VERSION "dbc-export 1 2025.20.8"

NS_ :

BS_:

BU_: ADSP APB APP APS APSB BB BMS CC CMP CMPD CP DAS DI DIF DIR DPB EPAS3P EPAS3S EPASTP EPASTS EPBL EPBR ESP EVSE FC GTW HCML HCMR HVP IBST ICR IDB LS OCS1P ODIN PARK PCS PLG PM PMF PMR PNCD PTC RADC RCM RCM2 RCM3 RCU SCCM SCM SCS SDCR TAS TCU TPMS TRCM UDS UI UIS UMC USM VC VCFRONT VCLEFT VCRIGHT VCSEC VEH

BO_ 1560 UDS_icrRequest: 8 UDS
 SG_ UDS_icrRequestData : 7|64@0+ (1,0) [0|1.84467440737e+19] "" Vector__XXX

BO_ 1603 UDS_ocs1pRequest: 8 UDS
 SG_ UDS_ocs1pRequestData : 7|64@0+ (1,0) [0|1.84467440737e+19] "" Vector__XXX

BO_ 1614 UDS_parkRequest: 8 UDS
 SG_ UDS_parkRequestData : 7|64@0+ (1,0) [0|1.84467440737e+19] "" Vector__XXX

BO_ 1576 UDS_pcsRequest: 8 UDS
 SG_ UDS_pcsRequestData : 7|64@0+ (1,0) [0|1.84467440737e+19] "" Vector__XXX

BO_ 1634 UDS_plgRequest: 8 UDS
 SG_ UDS_plgRequestData : 7|64@0+ (1,0) [0|1.84467440737e+19] "" Vector__XXX

BO_ 1568 UDS_pmRequest: 8 UDS
 SG_ UDS_pmRequestData : 7|64@0+ (1,0) [0|1.84467440737e+19] "" Vector__XXX

BO_ 1604 UDS_pmfRequest: 8 UDS
 SG_ UDS_pmfRequestData : 7|64@0+ (1,0) [0|1.84467440737e+19] "" Vector__XXX

BO_ 1540 UDS_pmrRequest: 8 UDS
 SG_ UDS_pmrRequestData : 7|64@0+ (1,0) [0|1.84467440737e+19] "" Vector__XXX

BO_ 1734 UDS_ptcRequest: 8 UDS
 SG_ UDS_ptcRequestData : 7|64@0+ (1,0) [0|1.84467440737e+19] "" Vector__XXX

BO_ 1649 UDS_radcRequest: 8 UDS
 SG_ UDS_radcRequestData : 7|64@0+ (1,0) [0|1.84467440737e+19] "" Vector__XXX

BO_ 1601 UDS_rcmRequest: 8 UDS
 SG_ UDS_rcmRequestData : 7|64@0+ (1,0) [0|1.84467440737e+19] "" Vector__XXX

BO_ 1664 UDS_sccmRequest: 8 UDS
 SG_ UDS_sccmRequestData : 7|64@0+ (1,0) [0|1.84467440737e+19] "" Vector__XXX

BO_ 1723 UDS_sdcrRequest: 8 UDS
 SG_ UDS_sdcrRequestData : 7|64@0+ (1,0) [0|1.84467440737e+19] "" Vector__XXX

BO_ 1611 UDS_tasRequest: 8 UDS
 SG_ UDS_tasRequestData : 7|64@0+ (1,0) [0|1.84467440737e+19] "" Vector__XXX

BO_ 1551 UDS_thcRequest: 8 UDS
 SG_ UDS_thcRequestData_H : 7|32@0+ (1,0) [0|4294967295] "" Vector__XXX
 SG_ UDS_thcRequestData_L : 39|32@0+ (1,0) [0|4294967295] "" Vector__XXX

BO_ 1615 UDS_tpmsRequest: 8 UDS
 SG_ UDS_tpmsRequestData : 7|64@0+ (1,0) [0|1.84467440737e+19] "" Vector__XXX

BO_ 1578 UDS_vcbatt1Request: 8 UDS
 SG_ UDS_vcbatt1RequestData : 7|64@0+ (1,0) [0|1.84467440737e+19] "" Vector__XXX

BO_ 1588 UDS_vcbatt2Request: 8 UDS
 SG_ UDS_vcbatt2RequestData : 7|64@0+ (1,0) [0|1.84467440737e+19] "" Vector__XXX

BO_ 1636 UDS_vcbattRequest: 8 UDS
 SG_ UDS_vcbattRequestData : 7|64@0+ (1,0) [0|1.84467440737e+19] "" Vector__XXX

BO_ 1580 UDS_vcfront1Request: 8 UDS
 SG_ UDS_vcfront1RequestData : 7|64@0+ (1,0) [0|1.84467440737e+19] "" Vector__XXX

BO_ 1582 UDS_vcfront2Request: 8 UDS
 SG_ UDS_vcfront2RequestData : 7|64@0+ (1,0) [0|1.84467440737e+19] "" Vector__XXX

BO_ 1536 UDS_vcfrontRequest: 8 UDS
 SG_ UDS_vcfrontRequestData : 7|64@0+ (1,0) [0|1.84467440737e+19] "" Vector__XXX

BO_ 1570 UDS_vcleftRequest: 8 UDS
 SG_ UDS_vcleftRequestData_H : 7|32@0+ (1,0) [0|4294967295] "" Vector__XXX
 SG_ UDS_vcleftRequestData_L : 39|32@0+ (1,0) [0|4294967295] "" Vector__XXX

BO_ 1544 UDS_vcrightRequest: 8 UDS
 SG_ UDS_vcrightRequestData_H : 7|32@0+ (1,0) [0|4294967295] "" Vector__XXX
 SG_ UDS_vcrightRequestData_L : 39|32@0+ (1,0) [0|4294967295] "" Vector__XXX

BO_ 1546 UDS_vcsecRequest: 8 UDS
 SG_ UDS_vcsecRequestData : 7|64@0+ (1,0) [0|1.84467440737e+19] "" Vector__XXX

BO_ 1056 UIS_log: 8 UIS
 SG_ UIS_logMux M : 0|32@1+ (1,0) [0|4294967295] "" Vector__XXX
 SG_ UIS_zramWriteTicks m0 : 32|32@1+ (1,0) [0|4294967295] "" Vector__XXX
 SG_ UIS_zramWriteIO m1 : 32|32@1+ (1,0) [0|4294967295] "" Vector__XXX
 SG_ UIS_zramReadTicks m2 : 32|32@1+ (1,0) [0|4294967295] "" Vector__XXX
 SG_ UIS_zramReadIO m3 : 32|32@1+ (1,0) [0|4294967295] "" Vector__XXX
 SG_ UIS_zramOriginalSize m4 : 32|32@1+ (1,0) [0|4294967295] "" Vector__XXX
 SG_ UIS_zramNotifyFree m5 : 32|32@1+ (1,0) [0|4294967295] "" Vector__XXX
 SG_ UIS_zramInvalidIO m6 : 32|32@1+ (1,0) [0|4294967295] "" Vector__XXX
 SG_ UIS_zramFailedWrites m7 : 32|32@1+ (1,0) [0|4294967295] "" Vector__XXX
 SG_ UIS_zramFailedReads m8 : 32|32@1+ (1,0) [0|4294967295] "" Vector__XXX
 SG_ UIS_zramCompressionRatio m9 : 32|32@1+ (1,0) [0|4294967295] "" Vector__XXX
 SG_ UIS_zramCompressedSize m10 : 32|32@1+ (1,0) [0|4294967295] "" Vector__XXX
 SG_ UIS_wifiTemperature m11 : 32|32@1+ (1,0) [0|4294967295] "" Vector__XXX
 SG_ UIS_wifiStackState m12 : 32|32@1+ (1,0) [0|4294967295] "" Vector__XXX
 SG_ UIS_wifiStackReady m13 : 32|32@1+ (1,0) [0|4294967295] "" Vector__XXX
 SG_ UIS_wifiBars m14 : 32|32@1+ (1,0) [0|4294967295] "" Vector__XXX
 SG_ UIS_wifiAutoJoinLowRSSI m15 : 32|32@1+ (1,0) [0|1] "" Vector__XXX
 SG_ UIS_webbrowserMemUsage m16 : 32|32@1+ (1,0) [0|4294967295] "" Vector__XXX
 SG_ UIS_webbrowserCPUUsage m17 : 32|32@1+ (1,0) [0|4294967295] "" Vector__XXX
 SG_ UIS_vmtouchMemUsage m18 : 32|32@1+ (1,0) [0|4294967295] "" Vector__XXX
 SG_ UIS_vmtouchCPUUsage m19 : 32|32@1+ (1,0) [0|4294967295] "" Vector__XXX
 SG_ UIS_videodMemUsage m20 : 32|32@1+ (1,0) [0|4294967295] "" Vector__XXX
 SG_ UIS_videodCPUUsage m21 : 32|32@1+ (1,0) [0|4294967295] "" Vector__XXX
 SG_ UIS_vehicleMemUsage m22 : 32|32@1+ (1,0) [0|4294967295] "" Vector__XXX
 SG_ UIS_vehicleCPUUsage m23 : 32|32@1+ (1,0) [0|4294967295] "" Vector__XXX
 SG_ UIS_valhallaserverMemUsage m24 : 32|32@1+ (1,0) [0|4294967295] "" Vector__XXX
 SG_ UIS_valhallaserverCPUUsage m25 : 32|32@1+ (1,0) [0|4294967295] "" Vector__XXX
 SG_ UIS_valetMode m26 : 32|32@1+ (1,0) [0|1] "" Vector__XXX
 SG_ UIS_uiQtCarUptime m27 : 32|32@1+ (1,0) [0|4294967295] "" Vector__XXX
 SG_ UIS_uiQtCarSwapUsage m28 : 32|32@1+ (1,0) [0|4294967295] "" Vector__XXX
 SG_ UIS_uiMeanFPS m29 : 32|32@1+ (1,0) [0|4294967295] "" Vector__XXX
 SG_ UIS_uiMaxFrametime m30 : 32|32@1+ (1,0) [0|4294967295] "" Vector__XXX
 SG_ UIS_uiFramesOver200Ms m31 : 32|32@1+ (1,0) [0|4294967295] "" Vector__XXX
 SG_ UIS_uiFramesOver100Ms m32 : 32|32@1+ (1,0) [0|4294967295] "" Vector__XXX
 SG_ UIS_tunerVoltageUBatt m33 : 32|32@1+ (1,0) [0|4294967295] "" Vector__XXX
 SG_ UIS_tunerVoltageOperation m34 : 32|32@1+ (1,0) [0|4294967295] "" Vector__XXX
 SG_ UIS_tunerVoltageMQS m35 : 32|32@1+ (1,0) [0|4294967295] "" Vector__XXX
 SG_ UIS_tunerVoltageAntenna2 m36 : 32|32@1+ (1,0) [0|4294967295] "" Vector__XXX
 SG_ UIS_tunerVoltageAntenna1 m37 : 32|32@1+ (1,0) [0|4294967295] "" Vector__XXX
 SG_ UIS_tunerVoltage3V3 m38 : 32|32@1+ (1,0) [0|4294967295] "" Vector__XXX
 SG_ UIS_tunerVoltage1V8 m39 : 32|32@1+ (1,0) [0|4294967295] "" Vector__XXX
 SG_ UIS_tunerTemperatureFahrenheit m40 : 32|32@1+ (1,0) [0|4294967295] "" Vector__XXX
 SG_ UIS_tunerTemperatureCelsius m41 : 32|32@1+ (1,0) [0|4294967295] "" Vector__XXX
 SG_ UIS_tunerCurrentAntenna2 m42 : 32|32@1+ (1,0) [0|4294967295] "" Vector__XXX
 SG_ UIS_tunerCurrentAntenna1 m43 : 32|32@1+ (1,0) [0|4294967295] "" Vector__XXX
 SG_ UIS_touchEventsAggCount m44 : 32|32@1+ (1,0) [0|4294967295] "" Vector__XXX
 SG_ UIS_tmserverMemUsage m45 : 32|32@1+ (1,0) [0|4294967295] "" Vector__XXX
 SG_ UIS_tmserverCPUUsage m46 : 32|32@1+ (1,0) [0|4294967295] "" Vector__XXX
 SG_ UIS_testDriveMode m47 : 32|32@1+ (1,0) [0|4294967295] "" Vector__XXX
 SG_ UIS_teslachromiumMemUsage m48 : 32|32@1+ (1,0) [0|4294967295] "" Vector__XXX
 SG_ UIS_teslachromiumCPUUsage m49 : 32|32@1+ (1,0) [0|4294967295] "" Vector__XXX
 SG_ UIS_teslacefzygotMemUsage m50 : 32|32@1+ (1,0) [0|4294967295] "" Vector__XXX
 SG_ UIS_teslacefzygotCPUUsage m51 : 32|32@1+ (1,0) [0|4294967295] "" Vector__XXX
 SG_ UIS_teslacefgpuMemUsage m52 : 32|32@1+ (1,0) [0|4294967295] "" Vector__XXX
 SG_ UIS_teslacefgpuCPUUsage m53 : 32|32@1+ (1,0) [0|4294967295] "" Vector__XXX
 SG_ UIS_teslaMediaCacheSize m54 : 32|32@1+ (1,0) [0|4294967295] "" Vector__XXX
 SG_ UIS_teslaMediaCacheCost m55 : 32|32@1+ (1,0) [0|4294967295] "" Vector__XXX
 SG_ UIS_tegraModemManState m56 : 32|32@1+ (1,0) [0|4294967295] "" Vector__XXX
 SG_ UIS_systemWakeTime m57 : 32|32@1+ (1,0) [0|4294967295] "" Vector__XXX
 SG_ UIS_systemUptime m58 : 32|32@1+ (1,0) [0|4294967295] "" Vector__XXX
 SG_ UIS_systemMemSwapUsage m59 : 32|32@1+ (1,0) [0|4294967295] "" Vector__XXX
 SG_ UIS_suspensionGeofence m60 : 32|32@1+ (1,0) [0|1] "" Vector__XXX
 SG_ UIS_superchargePaymentNeeded m61 : 32|32@1+ (1,0) [0|4294967295] "" Vector__XXX
 SG_ UIS_sudokuMemUsage m62 : 32|32@1+ (1,0) [0|4294967295] "" Vector__XXX
 SG_ UIS_sudokuCPUUsage m63 : 32|32@1+ (1,0) [0|4294967295] "" Vector__XXX
 SG_ UIS_spotifyserverMemUsage m64 : 32|32@1+ (1,0) [0|4294967295] "" Vector__XXX
 SG_ UIS_spotifyserverCPUUsage m65 : 32|32@1+ (1,0) [0|4294967295] "" Vector__XXX
 SG_ UIS_speechrecoMemUsage m66 : 32|32@1+ (1,0) [0|4294967295] "" Vector__XXX
 SG_ UIS_speechrecoCPUUsage m67 : 32|32@1+ (1,0) [0|4294967295] "" Vector__XXX
 SG_ UIS_solitaireMemUsage m68 : 32|32@1+ (1,0) [0|4294967295] "" Vector__XXX
 SG_ UIS_solitaireCPUUsage m69 : 32|32@1+ (1,0) [0|4294967295] "" Vector__XXX
 SG_ UIS_sleepType m70 : 32|32@1+ (1,0) [0|4294967295] "" Vector__XXX
 SG_ UIS_sleepTime m71 : 32|32@1+ (1,0) [0|4294967295] "" Vector__XXX
 SG_ UIS_sleepState m72 : 32|32@1+ (1,0) [0|4294967295] "" Vector__XXX
 SG_ UIS_sleepCount m73 : 32|32@1+ (1,0) [0|4294967295] "" Vector__XXX
 SG_ UIS_slackerLoginResult m74 : 32|32@1+ (1,0) [0|4294967295] "" Vector__XXX
 SG_ UIS_settingsAutoTurnSignal m75 : 32|32@1+ (1,0) [0|4294967295] "" Vector__XXX
 SG_ UIS_serviceModePlus m76 : 32|32@1+ (1,0) [0|4294967295] "" Vector__XXX
 SG_ UIS_serviceMode m77 : 32|32@1+ (1,0) [0|4294967295] "" Vector__XXX
 SG_ UIS_serverMemUsage m78 : 32|32@1+ (1,0) [0|4294967295] "" Vector__XXX
 SG_ UIS_serverCPUUsage m79 : 32|32@1+ (1,0) [0|4294967295] "" Vector__XXX
 SG_ UIS_sentryState m80 : 32|32@1+ (1,0) [0|4294967295] "" Vector__XXX
 SG_ UIS_sentryNeedsNap m81 : 32|32@1+ (1,0) [0|4294967295] "" Vector__XXX
 SG_ UIS_sentryIncidentCount m82 : 32|32@1+ (1,0) [0|4294967295] "" Vector__XXX
 SG_ UIS_scheduledChargingMode m83 : 32|32@1+ (1,0) [0|4294967295] "" Vector__XXX
 SG_ UIS_scheduleChargeStartTime m84 : 32|32@1+ (1,0) [0|4294967295] "" Vector__XXX
 SG_ UIS_scheduleChargeEndTime m85 : 32|32@1+ (1,0) [0|4294967295] "" Vector__XXX
 SG_ UIS_remoteRequestType m86 : 32|32@1+ (1,0) [0|4294967295] "" Vector__XXX
 SG_ UIS_releasenotesMemUsage m87 : 32|32@1+ (1,0) [0|4294967295] "" Vector__XXX
 SG_ UIS_releasenotesCPUUsage m88 : 32|32@1+ (1,0) [0|4294967295] "" Vector__XXX
 SG_ UIS_rearDisplayUserPresent m89 : 32|32@1+ (1,0) [0|1] "" Vector__XXX
 SG_ UIS_rearDisplayState m90 : 32|32@1+ (1,0) [0|4294967295] "" Vector__XXX
 SG_ UIS_radioserveMemUsage m91 : 32|32@1+ (1,0) [0|4294967295] "" Vector__XXX
 SG_ UIS_radioserveCPUUsage m92 : 32|32@1+ (1,0) [0|4294967295] "" Vector__XXX
 SG_ UIS_qtcarMemUsage m93 : 32|32@1+ (1,0) [0|4294967295] "" Vector__XXX
 SG_ UIS_qtcarCPUUsage m94 : 32|32@1+ (1,0) [0|4294967295] "" Vector__XXX
 SG_ UIS_psiMemSome m95 : 32|32@1+ (1,0) [0|4294967295] "" Vector__XXX
 SG_ UIS_psiMemFull m96 : 32|32@1+ (1,0) [0|4294967295] "" Vector__XXX
 SG_ UIS_psiIOSome m97 : 32|32@1+ (1,0) [0|4294967295] "" Vector__XXX
 SG_ UIS_psiIOFull m98 : 32|32@1+ (1,0) [0|4294967295] "" Vector__XXX
 SG_ UIS_psiCpuSome m99 : 32|32@1+ (1,0) [0|4294967295] "" Vector__XXX
 SG_ UIS_powerManagerState m100 : 32|5@1+ (1,0) [0|31] "" Vector__XXX
 SG_ UIS_polytopiax8664MemUsage m101 : 32|32@1+ (1,0) [0|4294967295] "" Vector__XXX
 SG_ UIS_polytopiax8664CPUUsage m102 : 32|32@1+ (1,0) [0|4294967295] "" Vector__XXX
 SG_ UIS_odincefMemUsage m103 : 32|32@1+ (1,0) [0|4294967295] "" Vector__XXX
 SG_ UIS_odincefCPUUsage m104 : 32|32@1+ (1,0) [0|4294967295] "" Vector__XXX
 SG_ UIS_odinStatusCmdResult m105 : 32|32@1+ (1,0) [0|4294967295] "" Vector__XXX
 SG_ UIS_odinStatusCmdDurationMs m106 : 32|32@1+ (1,0) [0|4294967295] "" Vector__XXX
 SG_ UIS_odinProcessState m107 : 32|32@1+ (1,0) [0|4294967295] "" Vector__XXX
 SG_ UIS_odinOrchestratorStartCount m108 : 32|32@1+ (1,0) [0|4294967295] "" Vector__XXX
 SG_ UIS_odinOrchestratorFailCount m109 : 32|32@1+ (1,0) [0|4294967295] "" Vector__XXX
 SG_ UIS_odinNetworkStartCount m110 : 32|32@1+ (1,0) [0|4294967295] "" Vector__XXX
 SG_ UIS_odinNetworkFailCount m111 : 32|32@1+ (1,0) [0|4294967295] "" Vector__XXX
 SG_ UIS_odinMemUsage m112 : 32|32@1+ (1,0) [0|4294967295] "" Vector__XXX
 SG_ UIS_odinListTasksCmdResult m113 : 32|32@1+ (1,0) [0|4294967295] "" Vector__XXX
 SG_ UIS_odinListTasksCmdDurationMs m114 : 32|32@1+ (1,0) [0|4294967295] "" Vector__XXX
 SG_ UIS_odinHrlUploadLimits m115 : 32|32@1+ (1,0) [0|4294967295] "" Vector__XXX
 SG_ UIS_odinHrlLogUploadState m116 : 32|32@1+ (1,0) [0|4294967295] "" Vector__XXX
 SG_ UIS_odinHermesConnectionState m117 : 32|32@1+ (1,0) [0|4294967295] "" Vector__XXX
 SG_ UIS_odinGatewayConnectionState m118 : 32|32@1+ (1,0) [0|4294967295] "" Vector__XXX
 SG_ UIS_odinFileSystemState m119 : 32|32@1+ (1,0) [0|4294967295] "" Vector__XXX
 SG_ UIS_odinEcuLogUploadState m120 : 32|32@1+ (1,0) [0|4294967295] "" Vector__XXX
 SG_ UIS_odinEcuLogForceTriggerUpload m121 : 32|32@1+ (1,0) [0|4294967295] "" Vector__XXX
 SG_ UIS_odinCPUUsage m122 : 32|32@1+ (1,0) [0|4294967295] "" Vector__XXX
 SG_ UIS_odinAuthFailCount m123 : 32|32@1+ (1,0) [0|4294967295] "" Vector__XXX
 SG_ UIS_odinAuthCount m124 : 32|32@1+ (1,0) [0|4294967295] "" Vector__XXX
 SG_ UIS_nvmeTemperature m125 : 32|32@1+ (1,0) [0|4294967295] "" Vector__XXX
 SG_ UIS_nvmePercentLifetimeUsed m126 : 32|32@1+ (1,0) [0|4294967295] "" Vector__XXX
 SG_ UIS_nvmeDataUnitsWritten100mb m127 : 32|32@1+ (1,0) [0|4294967295] "" Vector__XXX
 SG_ UIS_numUncorrMemErrorsECC m128 : 32|32@1+ (1,0) [0|4294967295] "" Vector__XXX
 SG_ UIS_numCorrMemErrorsECC m129 : 32|32@1+ (1,0) [0|4294967295] "" Vector__XXX
 SG_ UIS_nuanceserverMemUsage m130 : 32|32@1+ (1,0) [0|4294967295] "" Vector__XXX
 SG_ UIS_nuanceserverCPUUsage m131 : 32|32@1+ (1,0) [0|4294967295] "" Vector__XXX
 SG_ UIS_navAudioVolume m132 : 32|32@1+ (1,0) [0|4294967295] "" Vector__XXX
 SG_ UIS_muteNavVolume m133 : 32|32@1+ (1,0) [0|4294967295] "" Vector__XXX
 SG_ UIS_mounterdState m134 : 32|32@1+ (1,0) [0|4294967295] "" Vector__XXX
 SG_ UIS_mounterdMountCountTotal m135 : 32|32@1+ (1,0) [0|4294967295] "" Vector__XXX
 SG_ UIS_mounterdFrontHubDisconnected m136 : 32|32@1+ (1,0) [0|4294967295] "" Vector__XXX
 SG_ UIS_mounterdFrontHubConnected m137 : 32|32@1+ (1,0) [0|4294967295] "" Vector__XXX
 SG_ UIS_mounterdFilesystemCountFat32 m138 : 32|32@1+ (1,0) [0|4294967295] "" Vector__XXX
 SG_ UIS_mounterdFilesystemCountExt4 m139 : 32|32@1+ (1,0) [0|4294967295] "" Vector__XXX
 SG_ UIS_mounterdFilesystemCountExt3 m140 : 32|32@1+ (1,0) [0|4294967295] "" Vector__XXX
 SG_ UIS_mounterdFilesystemCountExfat m141 : 32|32@1+ (1,0) [0|4294967295] "" Vector__XXX
 SG_ UIS_mounterdEncryptionCapacityGB m142 : 32|32@1+ (1,0) [0|4294967295] "" Vector__XXX
 SG_ UIS_mounterdDeviceCount m143 : 32|32@1+ (1,0) [0|4294967295] "" Vector__XXX
 SG_ UIS_mounterdDashcamCapacityGB m144 : 32|32@1+ (1,0) [0|4294967295] "" Vector__XXX
 SG_ UIS_modemECallppAvail m145 : 32|32@1+ (1,0) [0|1] "" Vector__XXX
 SG_ UIS_modemBusyActive m146 : 32|32@1+ (1,0) [0|1] "" Vector__XXX
 SG_ UIS_mirrorGeofenceActive m147 : 32|32@1+ (1,0) [0|1] "" Vector__XXX
 SG_ UIS_mediaserveMemUsage m148 : 32|32@1+ (1,0) [0|4294967295] "" Vector__XXX
 SG_ UIS_mediaserveCPUUsage m149 : 32|32@1+ (1,0) [0|4294967295] "" Vector__XXX
 SG_ UIS_mediaPlaybackStatus m150 : 32|32@1+ (1,0) [0|4294967295] "" Vector__XXX
 SG_ UIS_mediaNeedAuthToken m151 : 32|32@1+ (1,0) [0|1] "" Vector__XXX
 SG_ UIS_mediaImageCacheSize m152 : 32|32@1+ (1,0) [0|4294967295] "" Vector__XXX
 SG_ UIS_mediaImageCacheCost m153 : 32|32@1+ (1,0) [0|4294967295] "" Vector__XXX
 SG_ UIS_limex8664MemUsage m154 : 32|32@1+ (1,0) [0|4294967295] "" Vector__XXX
 SG_ UIS_limex8664CPUUsage m155 : 32|32@1+ (1,0) [0|4294967295] "" Vector__XXX
 SG_ UIS_inSuperchargerGeofence m156 : 32|32@1+ (1,0) [0|1] "" Vector__XXX
 SG_ UIS_igpuTemperature m157 : 32|32@1+ (1,0) [0|4294967295] "" Vector__XXX
 SG_ UIS_homelinkState m158 : 32|32@1+ (1,0) [0|4294967295] "" Vector__XXX
 SG_ UIS_hermesdynamicMemUsage m159 : 32|32@1+ (1,0) [0|4294967295] "" Vector__XXX
 SG_ UIS_hermesdynamicCPUUsage m160 : 32|32@1+ (1,0) [0|4294967295] "" Vector__XXX
 SG_ UIS_hermesclientMemUsage m161 : 32|32@1+ (1,0) [0|4294967295] "" Vector__XXX
 SG_ UIS_hermesclientCPUUsage m162 : 32|32@1+ (1,0) [0|4294967295] "" Vector__XXX
 SG_ UIS_headsetPairResult m163 : 32|32@1+ (1,0) [0|4294967295] "" Vector__XXX
 SG_ UIS_headsetConnectionState m164 : 32|32@1+ (1,0) [0|4294967295] "" Vector__XXX
 SG_ UIS_gtwSocUartTxStatTimeouts m165 : 32|32@1+ (1,0) [0|4294967295] "" Vector__XXX
 SG_ UIS_gtwSocUartTxStatPackets m166 : 32|32@1+ (1,0) [0|4294967295] "" Vector__XXX
 SG_ UIS_gtwSocUartTxStatNacks m167 : 32|32@1+ (1,0) [0|4294967295] "" Vector__XXX
 SG_ UIS_gtwSocUartTxStatBadTooBig m168 : 32|32@1+ (1,0) [0|4294967295] "" Vector__XXX
 SG_ UIS_gtwSocUartTxStatAnsMismatch m169 : 32|32@1+ (1,0) [0|4294967295] "" Vector__XXX
 SG_ UIS_gtwSocUartRxStatValidPackets m170 : 32|32@1+ (1,0) [0|4294967295] "" Vector__XXX
 SG_ UIS_gtwSocUartRxStatUnhandled m171 : 32|32@1+ (1,0) [0|4294967295] "" Vector__XXX
 SG_ UIS_gtwSocUartRxStatMsgErr m172 : 32|32@1+ (1,0) [0|4294967295] "" Vector__XXX
 SG_ UIS_gtwSocUartRxStatHeartbeats m173 : 32|32@1+ (1,0) [0|4294967295] "" Vector__XXX
 SG_ UIS_gtwSocUartRxStatHandleErr m174 : 32|32@1+ (1,0) [0|4294967295] "" Vector__XXX
 SG_ UIS_gtwSocUartRxStatBadTooSmall m175 : 32|32@1+ (1,0) [0|4294967295] "" Vector__XXX
 SG_ UIS_gtwSocUartRxStatBadTooBig m176 : 32|32@1+ (1,0) [0|4294967295] "" Vector__XXX
 SG_ UIS_gtwSocUartRxStatBadChecksum m177 : 32|32@1+ (1,0) [0|4294967295] "" Vector__XXX
 SG_ UIS_gpsmanagerMemUsage m178 : 32|32@1+ (1,0) [0|4294967295] "" Vector__XXX
 SG_ UIS_gpsmanagerCPUUsage m179 : 32|32@1+ (1,0) [0|4294967295] "" Vector__XXX
 SG_ UIS_godot_TIME_PROCESS m180 : 32|32@1+ (1,0) [0|4294967295] "" Vector__XXX
 SG_ UIS_godot_TIME_FPS m181 : 32|32@1+ (1,0) [0|4294967295] "" Vector__XXX
 SG_ UIS_godot_MEMORY_STATIC m182 : 32|32@1+ (1,0) [0|4294967295] "" Vector__XXX
 SG_ UIS_godot_MEMORY_DYNAMIC m183 : 32|32@1+ (1,0) [0|4294967295] "" Vector__XXX
 SG_ UIS_godotMemUsage m184 : 32|32@1+ (1,0) [0|4294967295] "" Vector__XXX
 SG_ UIS_godotCPUUsage m185 : 32|32@1+ (1,0) [0|4294967295] "" Vector__XXX
 SG_ UIS_firmwareReleaseScope m186 : 32|32@1+ (1,0) [0|4294967295] "" Vector__XXX
 SG_ UIS_featureSuperchargingEnabled m187 : 32|32@1+ (1,0) [0|4294967295] "" Vector__XXX
 SG_ UIS_estimatedOccupancyCount m188 : 32|32@1+ (1,0) [0|4294967295] "" Vector__XXX
 SG_ UIS_embeddedGameState m189 : 32|32@1+ (1,0) [0|4294967295] "" Vector__XXX
 SG_ UIS_embeddedGameName m190 : 32|32@1+ (1,0) [0|4294967295] "" Vector__XXX
 SG_ UIS_dumTclipUploadState m191 : 32|32@1+ (1,0) [0|4294967295] "" Vector__XXX
 SG_ UIS_dumTclipUploadActive m192 : 32|32@1+ (1,0) [0|4294967295] "" Vector__XXX
 SG_ UIS_dumTclipTransferCount m193 : 32|32@1+ (1,0) [0|4294967295] "" Vector__XXX
 SG_ UIS_dumTclipSuccessfulUploadCoun m194 : 32|32@1+ (1,0) [0|4294967295] "" Vector__XXX
 SG_ UIS_dumTclipClipCount m195 : 32|32@1+ (1,0) [0|4294967295] "" Vector__XXX
 SG_ UIS_dmRearTouchDeviceExists m196 : 32|32@1+ (1,0) [0|4294967295] "" Vector__XXX
 SG_ UIS_dmRearPowerState m197 : 32|32@1+ (1,0) [0|1] "" Vector__XXX
 SG_ UIS_dmRearLinkCheckOk m198 : 32|32@1+ (1,0) [0|1] "" Vector__XXX
 SG_ UIS_dmRearEnabled m199 : 32|32@1+ (1,0) [0|4294967295] "" Vector__XXX
 SG_ UIS_dmRearConnected m200 : 32|32@1+ (1,0) [0|4294967295] "" Vector__XXX
 SG_ UIS_dmRearBacklightPowerLevel m201 : 32|32@1+ (1,0) [0|4294967295] "" Vector__XXX
 SG_ UIS_dmRearBacklightNits m202 : 32|32@1+ (1,0) [0|4294967295] "" Vector__XXX
 SG_ UIS_dmRearBacklightFault m203 : 32|32@1+ (1,0) [0|4294967295] "" Vector__XXX
 SG_ UIS_dmRearBacklightDutyCycle m204 : 32|32@1+ (1,0) [0|4294967295] "" Vector__XXX
 SG_ UIS_dmRearBacklightDevExists m205 : 32|32@1+ (1,0) [0|1] "" Vector__XXX
 SG_ UIS_dmRearAsilStatusMsb m206 : 32|32@1+ (1,0) [0|4294967295] "" Vector__XXX
 SG_ UIS_dmRearAsilStatusLsb m207 : 32|32@1+ (1,0) [0|4294967295] "" Vector__XXX
 SG_ UIS_dmIcuTouchIrqCount m208 : 32|32@1+ (1,0) [0|4294967295] "" Vector__XXX
 SG_ UIS_dmIcuPowerState m209 : 32|32@1+ (1,0) [0|1] "" Vector__XXX
 SG_ UIS_dmIcuLinkCheckOk m210 : 32|32@1+ (1,0) [0|1] "" Vector__XXX
 SG_ UIS_dmIcuEnabled m211 : 32|32@1+ (1,0) [0|4294967295] "" Vector__XXX
 SG_ UIS_dmIcuConnected m212 : 32|32@1+ (1,0) [0|4294967295] "" Vector__XXX
 SG_ UIS_dmIcuBacklightPowerLevel m213 : 32|32@1+ (1,0) [0|4294967295] "" Vector__XXX
 SG_ UIS_dmIcuBacklightNits m214 : 32|32@1+ (1,0) [0|4294967295] "" Vector__XXX
 SG_ UIS_dmIcuBacklightFault m215 : 32|32@1+ (1,0) [0|4294967295] "" Vector__XXX
 SG_ UIS_dmIcuBacklightDutyCycle m216 : 32|32@1+ (1,0) [0|4294967295] "" Vector__XXX
 SG_ UIS_dmIcuBacklightDevExists m217 : 32|32@1+ (1,0) [0|1] "" Vector__XXX
 SG_ UIS_dmIcuAsilShortFlag m218 : 32|32@1+ (1,0) [0|4294967295] "" Vector__XXX
 SG_ UIS_dmIcuAsilResumeFlag m219 : 32|32@1+ (1,0) [0|4294967295] "" Vector__XXX
 SG_ UIS_dmIcuAsilOpenFlag m220 : 32|32@1+ (1,0) [0|4294967295] "" Vector__XXX
 SG_ UIS_dmIcuAsilFirmwareStatus m221 : 32|32@1+ (1,0) [0|4294967295] "" Vector__XXX
 SG_ UIS_dmGatewayLinkWedged m222 : 32|32@1+ (1,0) [0|4294967295] "" Vector__XXX
 SG_ UIS_dmCenterTouchIrqCount m223 : 32|32@1+ (1,0) [0|4294967295] "" Vector__XXX
 SG_ UIS_dmCenterTouchDeviceExists m224 : 32|32@1+ (1,0) [0|4294967295] "" Vector__XXX
 SG_ UIS_dmCenterSOsdVideoCrcData m225 : 32|32@1+ (1,0) [0|4294967295] "" Vector__XXX
 SG_ UIS_dmCenterSOsdExactCrcCheck m226 : 32|32@1+ (1,0) [0|4294967295] "" Vector__XXX
 SG_ UIS_dmCenterPowerState m227 : 32|32@1+ (1,0) [0|1] "" Vector__XXX
 SG_ UIS_dmCenterOsdDisplayedState m228 : 32|32@1+ (1,0) [0|1] "" Vector__XXX
 SG_ UIS_dmCenterOsdDayNightState m229 : 32|32@1+ (1,0) [0|4294967295] "" Vector__XXX
 SG_ UIS_dmCenterModeSettingStatus m230 : 32|32@1+ (1,0) [0|4294967295] "" Vector__XXX
 SG_ UIS_dmCenterMOsdVideoCrcData m231 : 32|32@1+ (1,0) [0|4294967295] "" Vector__XXX
 SG_ UIS_dmCenterMOsdExactCrcCheck m232 : 32|32@1+ (1,0) [0|4294967295] "" Vector__XXX
 SG_ UIS_dmCenterLinkCheckOk m233 : 32|32@1+ (1,0) [0|1] "" Vector__XXX
 SG_ UIS_dmCenterEnabled m234 : 32|32@1+ (1,0) [0|4294967295] "" Vector__XXX
 SG_ UIS_dmCenterConnected m235 : 32|32@1+ (1,0) [0|4294967295] "" Vector__XXX
 SG_ UIS_dmCenterBacklightPowerLevel m236 : 32|32@1+ (1,0) [0|4294967295] "" Vector__XXX
 SG_ UIS_dmCenterBacklightNits m237 : 32|32@1+ (1,0) [0|4294967295] "" Vector__XXX
 SG_ UIS_dmCenterBacklightFault m238 : 32|32@1+ (1,0) [0|4294967295] "" Vector__XXX
 SG_ UIS_dmCenterBacklightDutyCycle m239 : 32|32@1+ (1,0) [0|4294967295] "" Vector__XXX
 SG_ UIS_dmCenterBacklightDevExists m240 : 32|32@1+ (1,0) [0|1] "" Vector__XXX
 SG_ UIS_dmCenterAsilShortFlag m241 : 32|32@1+ (1,0) [0|4294967295] "" Vector__XXX
 SG_ UIS_dmCenterAsilResumeFlag m242 : 32|32@1+ (1,0) [0|4294967295] "" Vector__XXX
 SG_ UIS_dmCenterAsilOpenFlag m243 : 32|32@1+ (1,0) [0|4294967295] "" Vector__XXX
 SG_ UIS_dmCenterAsilFirmwareStatus m244 : 32|32@1+ (1,0) [0|4294967295] "" Vector__XXX
 SG_ UIS_dgpuTemperature m245 : 32|32@1+ (1,0) [0|4294967295] "" Vector__XXX
 SG_ UIS_developerMode m246 : 32|32@1+ (1,0) [0|4294967295] "" Vector__XXX
 SG_ UIS_dashcamviewerMemUsage m247 : 32|32@1+ (1,0) [0|4294967295] "" Vector__XXX
 SG_ UIS_dashcamviewerCPUUsage m248 : 32|32@1+ (1,0) [0|4294967295] "" Vector__XXX
 SG_ UIS_dashcamTransferTimeMs m249 : 32|32@1+ (1,0) [0|4294967295] "" Vector__XXX
 SG_ UIS_dashcamTransferSizeMB m250 : 32|32@1+ (1,0) [0|4294967295] "" Vector__XXX
 SG_ UIS_dashcamTransferRateMBps m251 : 32|32@1+ (1,0) [0|4294967295] "" Vector__XXX
 SG_ UIS_dashcamTransferFileCount m252 : 32|32@1+ (1,0) [0|4294967295] "" Vector__XXX
 SG_ UIS_dashcamTransferCount m253 : 32|32@1+ (1,0) [0|4294967295] "" Vector__XXX
 SG_ UIS_dashcamStorageState m254 : 32|32@1+ (1,0) [0|4294967295] "" Vector__XXX
 SG_ UIS_dashcamStorageSentryMB m255 : 32|32@1+ (1,0) [0|4294967295] "" Vector__XXX
 SG_ UIS_dashcamStorageSavedMB m256 : 32|32@1+ (1,0) [0|4294967295] "" Vector__XXX
 SG_ UIS_dashcamStorageRecentMB m257 : 32|32@1+ (1,0) [0|4294967295] "" Vector__XXX
 SG_ UIS_dashcamStorageAvailableMB m258 : 32|32@1+ (1,0) [0|4294967295] "" Vector__XXX
 SG_ UIS_dashcamState m259 : 32|32@1+ (1,0) [0|4294967295] "" Vector__XXX
 SG_ UIS_dashcamSavedToSentryCount m260 : 32|32@1+ (1,0) [0|4294967295] "" Vector__XXX
 SG_ UIS_dashcamSavedToSavedCount m261 : 32|32@1+ (1,0) [0|4294967295] "" Vector__XXX
 SG_ UIS_dashcamSavedToOnboardCount m262 : 32|32@1+ (1,0) [0|4294967295] "" Vector__XXX
 SG_ UIS_dashcamOnboardTransferCount m263 : 32|32@1+ (1,0) [0|4294967295] "" Vector__XXX
 SG_ UIS_dashcamOnboardSavePressCount m264 : 32|32@1+ (1,0) [0|4294967295] "" Vector__XXX
 SG_ UIS_dashcamOnboardMB m265 : 32|32@1+ (1,0) [0|4294967295] "" Vector__XXX
 SG_ UIS_dashcamOnboardAvailableMB m266 : 32|32@1+ (1,0) [0|4294967295] "" Vector__XXX
 SG_ UIS_cpuTemperature m267 : 32|32@1+ (1,0) [0|4294967295] "" Vector__XXX
 SG_ UIS_compositorRenderMinRenderTim m268 : 32|32@1+ (1,0) [0|4294967295] "" Vector__XXX
 SG_ UIS_compositorRenderMinFrameTime m269 : 32|32@1+ (1,0) [0|4294967295] "" Vector__XXX
 SG_ UIS_compositorRenderMaxRenderTim m270 : 32|32@1+ (1,0) [0|4294967295] "" Vector__XXX
 SG_ UIS_compositorRenderMaxFrameTime m271 : 32|32@1+ (1,0) [0|4294967295] "" Vector__XXX
 SG_ UIS_compositorRenderGpuPercentag m272 : 32|32@1+ (1,0) [0|4294967295] "" Vector__XXX
 SG_ UIS_compositorRenderFrameRate m273 : 32|32@1+ (1,0) [0|4294967295] "" Vector__XXX
 SG_ UIS_compositorRenderFrameCount m274 : 32|32@1+ (1,0) [0|4294967295] "" Vector__XXX
 SG_ UIS_compositorRenderAvgRenderTim m275 : 32|32@1+ (1,0) [0|4294967295] "" Vector__XXX
 SG_ UIS_compositorFrameMonitorState m276 : 32|32@1+ (1,0) [0|4294967295] "" Vector__XXX
 SG_ UIS_cobaltlinuxMemUsage m277 : 32|32@1+ (1,0) [0|4294967295] "" Vector__XXX
 SG_ UIS_cobaltlinuxCPUUsage m278 : 32|32@1+ (1,0) [0|4294967295] "" Vector__XXX
 SG_ UIS_clusterMemUsage m279 : 32|32@1+ (1,0) [0|4294967295] "" Vector__XXX
 SG_ UIS_clusterMeanFPS m280 : 32|32@1+ (1,0) [0|4294967295] "" Vector__XXX
 SG_ UIS_clusterMaxFrametime m281 : 32|32@1+ (1,0) [0|4294967295] "" Vector__XXX
 SG_ UIS_clusterFramesOver200Ms m282 : 32|32@1+ (1,0) [0|4294967295] "" Vector__XXX
 SG_ UIS_clusterFramesOver100Ms m283 : 32|32@1+ (1,0) [0|4294967295] "" Vector__XXX
 SG_ UIS_clusterDisplayState m284 : 32|32@1+ (1,0) [0|4294967295] "" Vector__XXX
 SG_ UIS_clusterCPUUsage m285 : 32|32@1+ (1,0) [0|4294967295] "" Vector__XXX
 SG_ UIS_chromiumadapterMemUsage m286 : 32|32@1+ (1,0) [0|4294967295] "" Vector__XXX
 SG_ UIS_chromiumadapterCPUUsage m287 : 32|32@1+ (1,0) [0|4294967295] "" Vector__XXX
 SG_ UIS_chargeOnSolarNoChargeReason m288 : 32|32@1+ (1,0) [0|4294967295] "" Vector__XXX
 SG_ UIS_ceruleanx8664MemUsage m289 : 32|32@1+ (1,0) [0|4294967295] "" Vector__XXX
 SG_ UIS_ceruleanx8664CPUUsage m290 : 32|32@1+ (1,0) [0|4294967295] "" Vector__XXX
 SG_ UIS_centerDisplayState m291 : 32|32@1+ (1,0) [0|4294967295] "" Vector__XXX
 SG_ UIS_centerDisplayEvent m292 : 32|32@1+ (1,0) [0|4294967295] "" Vector__XXX
 SG_ UIS_centerDispAsilB_msb m293 : 32|32@1+ (1,0) [0|4294967295] "" Vector__XXX
 SG_ UIS_centerDispAsilB_lsb m294 : 32|32@1+ (1,0) [0|4294967295] "" Vector__XXX
 SG_ UIS_centerDispAsilA_msb m295 : 32|32@1+ (1,0) [0|4294967295] "" Vector__XXX
 SG_ UIS_centerDispAsilA_lsb m296 : 32|32@1+ (1,0) [0|4294967295] "" Vector__XXX
 SG_ UIS_cellularLinkManagerState m297 : 32|32@1+ (1,0) [0|4294967295] "" Vector__XXX
 SG_ UIS_carAssistState m298 : 32|32@1+ (1,0) [0|4294967295] "" Vector__XXX
 SG_ UIS_carAssistSessionCount m299 : 32|32@1+ (1,0) [0|4294967295] "" Vector__XXX
 SG_ UIS_carAssistErrorCode m300 : 32|32@1+ (1,0) [0|4294967295] "" Vector__XXX
 SG_ UIS_cameraRRepeaterStreamMissing m301 : 32|32@1+ (1,0) [0|1] "" Vector__XXX
 SG_ UIS_cameraRRepeaterStream m302 : 32|32@1+ (1,0) [0|4294967295] "" Vector__XXX
 SG_ UIS_cameraRRepeaterPopup m303 : 32|32@1+ (1,0) [0|1] "" Vector__XXX
 SG_ UIS_cameraRRepeaterPipeline m304 : 32|32@1+ (1,0) [0|4294967295] "" Vector__XXX
 SG_ UIS_cameraRRepeaterMaxFrametime m305 : 32|32@1+ (1,0) [0|4294967295] "" Vector__XXX
 SG_ UIS_cameraRRepeaterLateFrames m306 : 32|32@1+ (1,0) [0|4294967295] "" Vector__XXX
 SG_ UIS_cameraRRepeaterFramerate m307 : 32|32@1+ (1,0) [0|4294967295] "" Vector__XXX
 SG_ UIS_cameraLRepeaterStreamMissing m308 : 32|32@1+ (1,0) [0|1] "" Vector__XXX
 SG_ UIS_cameraLRepeaterStream m309 : 32|32@1+ (1,0) [0|4294967295] "" Vector__XXX
 SG_ UIS_cameraLRepeaterPopup m310 : 32|32@1+ (1,0) [0|1] "" Vector__XXX
 SG_ UIS_cameraLRepeaterPipeline m311 : 32|32@1+ (1,0) [0|4294967295] "" Vector__XXX
 SG_ UIS_cameraLRepeaterMaxFrametime m312 : 32|32@1+ (1,0) [0|4294967295] "" Vector__XXX
 SG_ UIS_cameraLRepeaterLateFrames m313 : 32|32@1+ (1,0) [0|4294967295] "" Vector__XXX
 SG_ UIS_cameraLRepeaterFramerate m314 : 32|32@1+ (1,0) [0|4294967295] "" Vector__XXX
 SG_ UIS_cameraFrontStreamMissing m315 : 32|32@1+ (1,0) [0|4294967295] "" Vector__XXX
 SG_ UIS_cameraFrontStream m316 : 32|32@1+ (1,0) [0|4294967295] "" Vector__XXX
 SG_ UIS_cameraFrontPopup m317 : 32|32@1+ (1,0) [0|4294967295] "" Vector__XXX
 SG_ UIS_cameraFrontPipeline m318 : 32|32@1+ (1,0) [0|4294967295] "" Vector__XXX
 SG_ UIS_cameraBackupStreamQuality m319 : 32|32@1+ (1,0) [0|4294967295] "" Vector__XXX
 SG_ UIS_cameraBackupStreamMissing m320 : 32|32@1+ (1,0) [0|1] "" Vector__XXX
 SG_ UIS_cameraBackupStream m321 : 32|32@1+ (1,0) [0|4294967295] "" Vector__XXX
 SG_ UIS_cameraBackupPopup m322 : 32|32@1+ (1,0) [0|1] "" Vector__XXX
 SG_ UIS_cameraBackupPipeline m323 : 32|32@1+ (1,0) [0|4294967295] "" Vector__XXX
 SG_ UIS_cameraBackupMaxFrametime m324 : 32|32@1+ (1,0) [0|4294967295] "" Vector__XXX
 SG_ UIS_cameraBackupLateFrames m325 : 32|32@1+ (1,0) [0|4294967295] "" Vector__XXX
 SG_ UIS_cameraBackupFramerate m326 : 32|32@1+ (1,0) [0|4294967295] "" Vector__XXX
 SG_ UIS_camBackupDecodeMinFrametime m327 : 32|32@1+ (1,0) [0|4294967295] "" Vector__XXX
 SG_ UIS_camBackupDecodeMaxFrametime m328 : 32|32@1+ (1,0) [0|4294967295] "" Vector__XXX
 SG_ UIS_camBackupDecodeFramecount m329 : 32|32@1+ (1,0) [0|4294967295] "" Vector__XXX
 SG_ UIS_camBackupDecodeAvgFrametime m330 : 32|32@1+ (1,0) [0|4294967295] "" Vector__XXX
 SG_ UIS_bootCount m331 : 32|32@1+ (1,0) [0|4294967295] "" Vector__XXX
 SG_ UIS_boardTemperature m332 : 32|32@1+ (1,0) [0|4294967295] "" Vector__XXX
 SG_ UIS_bluetoothStackState m333 : 32|32@1+ (1,0) [0|4294967295] "" Vector__XXX
 SG_ UIS_bluetoothStackRearState m334 : 32|32@1+ (1,0) [0|4294967295] "" Vector__XXX
 SG_ UIS_bluetoothPairResult m335 : 32|32@1+ (1,0) [0|4294967295] "" Vector__XXX
 SG_ UIS_bluetoothMemUsage m336 : 32|32@1+ (1,0) [0|4294967295] "" Vector__XXX
 SG_ UIS_bluetoothConnectionState m337 : 32|32@1+ (1,0) [0|4294967295] "" Vector__XXX
 SG_ UIS_bluetoothCPUUsage m338 : 32|32@1+ (1,0) [0|4294967295] "" Vector__XXX
 SG_ UIS_bluetoothAutoConnectionState m339 : 32|32@1+ (1,0) [0|4294967295] "" Vector__XXX
 SG_ UIS_bifrostOdinEngineUp m340 : 32|32@1+ (1,0) [0|4294967295] "" Vector__XXX
 SG_ UIS_bifrostOdinEngineRequests m341 : 32|32@1+ (1,0) [0|4294967295] "" Vector__XXX
 SG_ UIS_bifrostMemUsage m342 : 32|32@1+ (1,0) [0|4294967295] "" Vector__XXX
 SG_ UIS_bifrostCPUUsage m343 : 32|32@1+ (1,0) [0|4294967295] "" Vector__XXX
 SG_ UIS_backlightUserRequest m344 : 32|32@1+ (1,0) [0|4294967295] "" Vector__XXX
 SG_ UIS_audioVolumeLevel m345 : 32|32@1+ (1,0) [0|4294967295] "" Vector__XXX
 SG_ UIS_audioType m346 : 32|32@1+ (1,0) [0|4294967295] "" Vector__XXX
 SG_ UIS_audioState m347 : 32|32@1+ (1,0) [0|4294967295] "" Vector__XXX
 SG_ UIS_audioSource m348 : 32|32@1+ (1,0) [0|4294967295] "" Vector__XXX
 SG_ UIS_audioPWSGain m349 : 32|32@1+ (1,0) [0|4294967295] "" Vector__XXX
 SG_ UIS_audioMediaPlaying m350 : 32|32@1+ (1,0) [0|4294967295] "" Vector__XXX
 SG_ UIS_audioMediaBrowsing m351 : 32|32@1+ (1,0) [0|4294967295] "" Vector__XXX
 SG_ UIS_audioA2BRediscoveryCount m352 : 32|32@1+ (1,0) [0|4294967295] "" Vector__XXX
 SG_ UIS_amdSocPkgPower m353 : 32|32@1+ (1,0) [0|4294967295] "" Vector__XXX
 SG_ UIS_activeAppView m354 : 32|32@1+ (1,0) [0|4294967295] "" Vector__XXX

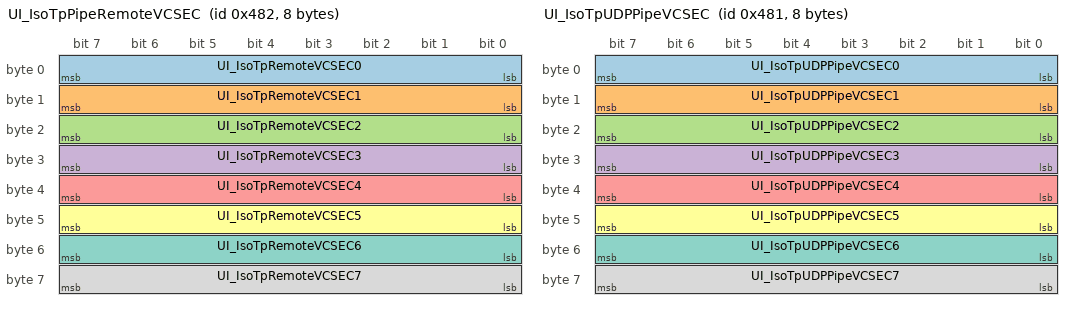
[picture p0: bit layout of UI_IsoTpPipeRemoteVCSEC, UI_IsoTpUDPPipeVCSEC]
BO_ 1154 UI_IsoTpPipeRemoteVCSEC: 8 UI
 SG_ UI_IsoTpRemoteVCSEC0 : 0|8@1+ (1,0) [0|255] "" Vector__XXX
 SG_ UI_IsoTpRemoteVCSEC1 : 8|8@1+ (1,0) [0|255] "" Vector__XXX
 SG_ UI_IsoTpRemoteVCSEC2 : 16|8@1+ (1,0) [0|255] "" Vector__XXX
 SG_ UI_IsoTpRemoteVCSEC3 : 24|8@1+ (1,0) [0|255] "" Vector__XXX
 SG_ UI_IsoTpRemoteVCSEC4 : 32|8@1+ (1,0) [0|255] "" Vector__XXX
 SG_ UI_IsoTpRemoteVCSEC5 : 40|8@1+ (1,0) [0|255] "" Vector__XXX
 SG_ UI_IsoTpRemoteVCSEC6 : 48|8@1+ (1,0) [0|255] "" Vector__XXX
 SG_ UI_IsoTpRemoteVCSEC7 : 56|8@1+ (1,0) [0|255] "" Vector__XXX

BO_ 1153 UI_IsoTpUDPPipeVCSEC: 8 UI
 SG_ UI_IsoTpUDPPipeVCSEC0 : 0|8@1+ (1,0) [0|255] "" Vector__XXX
 SG_ UI_IsoTpUDPPipeVCSEC1 : 8|8@1+ (1,0) [0|255] "" Vector__XXX
 SG_ UI_IsoTpUDPPipeVCSEC2 : 16|8@1+ (1,0) [0|255] "" Vector__XXX
 SG_ UI_IsoTpUDPPipeVCSEC3 : 24|8@1+ (1,0) [0|255] "" Vector__XXX
 SG_ UI_IsoTpUDPPipeVCSEC4 : 32|8@1+ (1,0) [0|255] "" Vector__XXX
 SG_ UI_IsoTpUDPPipeVCSEC5 : 40|8@1+ (1,0) [0|255] "" Vector__XXX
 SG_ UI_IsoTpUDPPipeVCSEC6 : 48|8@1+ (1,0) [0|255] "" Vector__XXX
 SG_ UI_IsoTpUDPPipeVCSEC7 : 56|8@1+ (1,0) [0|255] "" Vector__XXX

BO_ 979 UI_airbagCutoffStatus: 1 UI
 SG_ UI_airbagCutoffSwState : 0|2@1+ (1,0) [0|3] "" Vector__XXX
 SG_ UI_warningIndicatorStatus : 2|2@1+ (1,0) [0|2] "" Vector__XXX

BO_ 1523 UI_alertLog: 8 UI
 SG_ UI_alertID M : 0|8@1+ (1,0) [0|255] "" Vector__XXX
 SG_ UI_alertState : 15|1@1+ (1,0) [0|1] "" Vector__XXX
 SG_ UI_a006_remoteServiceAlertCode m6 : 16|32@1+ (1,0) [0|4294967295] "" Vector__XXX
 SG_ UI_a034_BackupCamera m34 : 16|1@1+ (1,0) [0|1] "" Vector__XXX
 SG_ UI_a034_Tuner m34 : 17|1@1+ (1,0) [0|1] "" Vector__XXX
 SG_ UI_a034_Bluetooth m34 : 18|1@1+ (1,0) [0|1] "" Vector__XXX
 SG_ UI_a034_WiFi m34 : 19|1@1+ (1,0) [0|1] "" Vector__XXX
 SG_ UI_a034_Cellular m34 : 20|1@1+ (1,0) [0|1] "" Vector__XXX
 SG_ UI_a034_TouchScreen m34 : 21|1@1+ (1,0) [0|1] "" Vector__XXX
 SG_ UI_a034_Display m34 : 22|1@1+ (1,0) [0|1] "" Vector__XXX
 SG_ UI_a034_Audio m34 : 23|1@1+ (1,0) [0|1] "" Vector__XXX
 SG_ UI_a034_FatalWakeup m34 : 24|1@1+ (1,0) [0|1] "" Vector__XXX
 SG_ UI_a034_UnknownWakeupError m34 : 25|1@1+ (1,0) [0|1] "" Vector__XXX
 SG_ UI_a036_audioWatchdogReason m36 : 16|8@1+ (1,0) [0|255] "" Vector__XXX
 SG_ UI_a045_ManualECallDisabled m45 : 16|1@1+ (1,0) [0|1] "" Vector__XXX
 SG_ UI_a045_ManualECallButtonDisconn m45 : 17|1@1+ (1,0) [0|1] "" Vector__XXX
 SG_ UI_a045_CellAntenna m45 : 18|1@1+ (1,0) [0|1] "" Vector__XXX
 SG_ UI_a045_GPSAntenna m45 : 19|1@1+ (1,0) [0|1] "" Vector__XXX
 SG_ UI_a045_ECallSpeaker m45 : 20|1@1+ (1,0) [0|1] "" Vector__XXX
 SG_ UI_a045_ECallMic m45 : 21|1@1+ (1,0) [0|1] "" Vector__XXX
 SG_ UI_a045_SIMTest m45 : 22|1@1+ (1,0) [0|1] "" Vector__XXX
 SG_ UI_a045_ENSTest m45 : 23|1@1+ (1,0) [0|1] "" Vector__XXX
 SG_ UI_a045_CellularTest m45 : 24|1@1+ (1,0) [0|1] "" Vector__XXX
 SG_ UI_a045_ModemFirmwareTest m45 : 25|1@1+ (1,0) [0|1] "" Vector__XXX
 SG_ UI_a052_kernelPanicSignature m52 : 16|32@1+ (1,0) [0|4294967295] "" Vector__XXX
 SG_ UI_a066_ProcessId m66 : 16|8@1+ (1,0) [0|255] "" Vector__XXX
 SG_ UI_a066_RingBlitter m66 : 24|1@1+ (1,0) [0|1] "" Vector__XXX
 SG_ UI_a066_RingBSD m66 : 25|1@1+ (1,0) [0|1] "" Vector__XXX
 SG_ UI_a066_RingRender m66 : 26|1@1+ (1,0) [0|1] "" Vector__XXX
 SG_ UI_a066_RingVideoEnhancement m66 : 27|1@1+ (1,0) [0|1] "" Vector__XXX
 SG_ UI_a066_EnginesHung m66 : 28|1@1+ (1,0) [0|1] "" Vector__XXX
 SG_ UI_a066_EnginesWedged m66 : 29|1@1+ (1,0) [0|1] "" Vector__XXX
 SG_ UI_a066_RecoveryFailed m66 : 30|1@1+ (1,0) [0|1] "" Vector__XXX
 SG_ UI_a066_FlipDoneTimedOut m66 : 31|1@1+ (1,0) [0|1] "" Vector__XXX
 SG_ UI_a066_TimedoutSoftRecovered m66 : 32|1@1+ (1,0) [0|1] "" Vector__XXX
 SG_ UI_a087_BmpResetType m87 : 16|3@1+ (1,0) [0|7] "" Vector__XXX
 SG_ UI_a096_PipelineId m96 : 16|8@1+ (1,0) [0|255] "" Vector__XXX
 SG_ UI_a096_UdpTimeout m96 : 24|1@1+ (1,0) [0|1] "" Vector__XXX
 SG_ UI_a096_PipelineWarning m96 : 25|1@1+ (1,0) [0|1] "" Vector__XXX
 SG_ UI_a096_PipelineError m96 : 26|1@1+ (1,0) [0|1] "" Vector__XXX
 SG_ UI_a096_UnexpectedExit m96 : 27|1@1+ (1,0) [0|1] "" Vector__XXX
 SG_ UI_a096_PipelineOverrun m96 : 28|1@1+ (1,0) [0|1] "" Vector__XXX
 SG_ UI_a096_MissingXWindow m96 : 29|1@1+ (1,0) [0|1] "" Vector__XXX
 SG_ UI_a099_emmcStatusRegister m99 : 16|32@1+ (1,0) [0|4294967295] "" Vector__XXX
 SG_ UI_a100_emmcFTLCounter m100 : 16|32@1+ (1,0) [0|4294967295] "" Vector__XXX
 SG_ UI_a131_DisplayPortFailureType m131 : 16|1@1+ (1,0) [0|1] "" Vector__XXX
 SG_ UI_a147_whichASIL m147 : 16|1@1+ (1,0) [0|1] "" Vector__XXX
 SG_ UI_a147_errorCode m147 : 24|8@1+ (1,0) [0|255] "" Vector__XXX
 SG_ UI_a148_sleepType m148 : 16|2@1+ (1,0) [0|3] "" Vector__XXX
 SG_ UI_a148_lastFailedDev m148 : 24|32@1+ (1,0) [0|4294967295] "" Vector__XXX
 SG_ UI_a148_lastFailedPmSuspendDev m148 : 56|5@1+ (1,0) [0|31] "" Vector__XXX
 SG_ UI_a149_displayType m149 : 16|8@1+ (1,0) [0|255] "" Vector__XXX
 SG_ UI_a149_errorCode m149 : 24|32@1+ (1,0) [0|4294967295] "" Vector__XXX
 SG_ UI_a153_processName m153 : 16|8@1+ (1,0) [0|255] "" Vector__XXX
 SG_ UI_a153_restartReason m153 : 24|8@1+ (1,0) [0|255] "" Vector__XXX
 SG_ UI_a158_UsbDeviceMountErrorCode m158 : 16|32@1+ (1,0) [0|4294967295] "" Vector__XXX
 SG_ UI_a160_WatchdogStarving m160 : 16|1@1+ (1,0) [0|1] "" Vector__XXX
 SG_ UI_a160_MemoryPressureCritical m160 : 17|1@1+ (1,0) [0|1] "" Vector__XXX
 SG_ UI_a160_MemoryUsageCritical m160 : 18|1@1+ (1,0) [0|1] "" Vector__XXX
 SG_ UI_a160_SlabUsageCritical m160 : 19|1@1+ (1,0) [0|1] "" Vector__XXX
 SG_ UI_a165_fsCorruptedDevice m165 : 16|4@1+ (1,0) [0|15] "" Vector__XXX
 SG_ UI_a166_fsErrorDevice m166 : 16|4@1+ (1,0) [0|15] "" Vector__XXX
 SG_ UI_a167_processId m167 : 16|5@1+ (1,0) [0|31] "" Vector__XXX
 SG_ UI_a173_errorCode m173 : 16|2@1+ (1,0) [0|3] "" Vector__XXX
 SG_ UI_a173_hookIndex m173 : 18|4@1+ (1,0) [0|15] "" Vector__XXX
 SG_ UI_a173_lastFailedPmSuspendDev m173 : 24|5@1+ (1,0) [0|31] "" Vector__XXX
 SG_ UI_a176_PrimaryAntenna m176 : 16|3@1+ (1,0) [0|7] "" Vector__XXX
 SG_ UI_a176_SecondaryAntenna m176 : 19|3@1+ (1,0) [0|7] "" Vector__XXX
 SG_ UI_a176_TertiaryAntenna m176 : 24|3@1+ (1,0) [0|7] "" Vector__XXX
 SG_ UI_a177_errorCode m177 : 16|5@1+ (1,0) [0|31] "" Vector__XXX
 SG_ UI_a178_irqNumber m178 : 16|16@1+ (1,0) [0|65535] "" Vector__XXX
 SG_ UI_a178_irqSourceId m178 : 32|32@1+ (1,0) [0|4294967295] "" Vector__XXX
 SG_ UI_a192_AudioRebootState m192 : 16|4@1+ (1,0) [0|15] "" Vector__XXX
 SG_ UI_a214_errorCode m214 : 16|8@1+ (1,0) [0|255] "" Vector__XXX
 SG_ UI_a214_lastFailedDev m214 : 24|32@1+ (1,0) [0|4294967295] "" Vector__XXX
 SG_ UI_a214_lastFailedPmSuspendDev m214 : 56|5@1+ (1,0) [0|31] "" Vector__XXX
 SG_ UI_a216_circuitProblem m216 : 16|8@1+ (1,0) [0|255] "" Vector__XXX
 SG_ UI_a216_circuitNode m216 : 24|8@1+ (1,0) [0|255] "" Vector__XXX
 SG_ UI_a217_cgroupName m217 : 16|5@1+ (1,0) [0|31] "" Vector__XXX
 SG_ UI_a220_errorCode m220 : 16|4@1+ (1,0) [0|15] "" Vector__XXX
 SG_ UI_a222_errorCode m222 : 16|4@1+ (1,0) [0|15] "" Vector__XXX
 SG_ UI_a223_database m223 : 16|6@1+ (1,0) [0|63] "" Vector__XXX
 SG_ UI_a226_count m226 : 16|16@1+ (1,0) [0|65535] "" Vector__XXX
 SG_ UI_a229_errorCode m229 : 16|8@1+ (1,0) [0|255] "" Vector__XXX
 SG_ UI_a231_sleepType m231 : 16|2@1+ (1,0) [0|3] "" Vector__XXX
 SG_ UI_a232_processExited m232 : 16|8@1+ (1,0) [0|255] "" Vector__XXX
 SG_ UI_a232_processSignal m232 : 24|8@1+ (1,0) [0|255] "" Vector__XXX
 SG_ UI_a240_ethErrorType m240 : 16|8@1+ (1,0) [0|255] "" Vector__XXX
 SG_ UI_a241_errorCode m241 : 16|8@1+ (1,0) [0|255] "" Vector__XXX

BO_ 291 UI_alertMatrix1: 8 UI
 SG_ UI_a001_DriverDoorOpen : 0|1@1+ (1,0) [0|1] "" Vector__XXX
 SG_ UI_a002_DoorOpen : 1|1@1+ (1,0) [0|1] "" Vector__XXX
 SG_ UI_a003_TrunkOpen : 2|1@1+ (1,0) [0|1] "" Vector__XXX
 SG_ UI_a004_FrunkOpen : 3|1@1+ (1,0) [0|1] "" Vector__XXX
 SG_ UI_a005_HeadlightsOnDoorOpen : 4|1@1+ (1,0) [0|1] "" Vector__XXX
 SG_ UI_a006_RemoteServiceAlert : 5|1@1+ (1,0) [0|1] "" Vector__XXX
 SG_ UI_a007_SoftPackConfigMismatch : 6|1@1+ (1,0) [0|1] "" Vector__XXX
 SG_ UI_a008_TouchScreenError : 7|1@1+ (1,0) [0|1] "" Vector__XXX
 SG_ UI_a009_SquashfsError : 8|1@1+ (1,0) [0|1] "" Vector__XXX
 SG_ UI_a010_MapsMissing : 9|1@1+ (1,0) [0|1] "" Vector__XXX
 SG_ UI_a011_IncorrectMap : 10|1@1+ (1,0) [0|1] "" Vector__XXX
 SG_ UI_a012_NotOnPrivateProperty : 11|1@1+ (1,0) [0|1] "" Vector__XXX
 SG_ UI_a013_TPMSHardWarning : 12|1@1+ (1,0) [0|1] "" Vector__XXX
 SG_ UI_a014_TPMSSoftWarning : 13|1@1+ (1,0) [0|1] "" Vector__XXX
 SG_ UI_a015_TPMSOverPressureWarning : 14|1@1+ (1,0) [0|1] "" Vector__XXX
 SG_ UI_a016_TPMSTemperatureWarning : 15|1@1+ (1,0) [0|1] "" Vector__XXX
 SG_ UI_a017_TPMSSystemFault : 16|1@1+ (1,0) [0|1] "" Vector__XXX
 SG_ UI_a018_SlipStartOn : 17|1@1+ (1,0) [0|1] "" Vector__XXX
 SG_ UI_a019_ParkBrakeFault : 18|1@1+ (1,0) [0|1] "" Vector__XXX
 SG_ UI_a020_SteeringReduced : 19|1@1+ (1,0) [0|1] "" Vector__XXX
 SG_ UI_a021_RearSeatbeltUnbuckled : 20|1@1+ (1,0) [0|1] "" Vector__XXX
 SG_ UI_a022_ApeFusesEtc : 21|1@1+ (1,0) [0|1] "" Vector__XXX
 SG_ UI_a023_CellInternetCheckFailed : 22|1@1+ (1,0) [0|1] "" Vector__XXX
 SG_ UI_a024_WifiInternetCheckFailed : 23|1@1+ (1,0) [0|1] "" Vector__XXX
 SG_ UI_a026_ModemResetLoopDetected : 25|1@1+ (1,0) [0|1] "" Vector__XXX
 SG_ UI_a027_AutoSteerMIA : 26|1@1+ (1,0) [0|1] "" Vector__XXX
 SG_ UI_a028_FrontTrunkPopupClosed : 27|1@1+ (1,0) [0|1] "" Vector__XXX
 SG_ UI_a029_ModemMIA : 28|1@1+ (1,0) [0|1] "" Vector__XXX
 SG_ UI_a030_ModemVMCrash : 29|1@1+ (1,0) [0|1] "" Vector__XXX
 SG_ UI_a031_BrakeFluidLow : 30|1@1+ (1,0) [0|1] "" Vector__XXX
 SG_ UI_a032_CellModemRecoveryResets : 31|1@1+ (1,0) [0|1] "" Vector__XXX
 SG_ UI_a033_ApTrialExpired : 32|1@1+ (1,0) [0|1] "" Vector__XXX
 SG_ UI_a034_WakeupProblem : 33|1@1+ (1,0) [0|1] "" Vector__XXX
 SG_ UI_a035_FrunkOpenChime : 34|1@1+ (1,0) [0|1] "" Vector__XXX
 SG_ UI_a036_AudioWatchdog : 35|1@1+ (1,0) [0|1] "" Vector__XXX
 SG_ UI_a037_AudioWatchdogXrunStormEr : 36|1@1+ (1,0) [0|1] "" Vector__XXX
 SG_ UI_a038_AudioWatchdogA2bI2cLocku : 37|1@1+ (1,0) [0|1] "" Vector__XXX
 SG_ UI_a039_AudioA2bNeedRediscovery : 38|1@1+ (1,0) [0|1] "" Vector__XXX
 SG_ UI_a040_HomelinkTransmit : 39|1@1+ (1,0) [0|1] "" Vector__XXX
 SG_ UI_a041_AudioDmesgXrun : 40|1@1+ (1,0) [0|1] "" Vector__XXX
 SG_ UI_a042_AudioDmesgRtThrottling : 41|1@1+ (1,0) [0|1] "" Vector__XXX
 SG_ UI_a043_InvalidMapDataOverride : 42|1@1+ (1,0) [0|1] "" Vector__XXX
 SG_ UI_a044_AudioDmesgDspException : 43|1@1+ (1,0) [0|1] "" Vector__XXX
 SG_ UI_a045_ECallSystemCheckFailed : 44|1@1+ (1,0) [0|1] "" Vector__XXX
 SG_ UI_a046_BackupCameraStreamError : 45|1@1+ (1,0) [0|1] "" Vector__XXX
 SG_ UI_a047_CellRoamingDisallowed : 46|1@1+ (1,0) [0|1] "" Vector__XXX
 SG_ UI_a048_AudioPremiumAmpCheckFail : 47|1@1+ (1,0) [0|1] "" Vector__XXX
 SG_ UI_a049_BrakeShiftRequired : 48|1@1+ (1,0) [0|1] "" Vector__XXX
 SG_ UI_a050_BackupCameraIPUTimeout : 49|1@1+ (1,0) [0|1] "" Vector__XXX
 SG_ UI_a051_BackupCameraFrameTimeout : 50|1@1+ (1,0) [0|1] "" Vector__XXX
 SG_ UI_a052_KernelPanicReported : 51|1@1+ (1,0) [0|1] "" Vector__XXX
 SG_ UI_a053_QtCarExitError : 52|1@1+ (1,0) [0|1] "" Vector__XXX
 SG_ UI_a054_AudioBoostPowerBad : 53|1@1+ (1,0) [0|1] "" Vector__XXX
 SG_ UI_a055_ManualECallDisabled : 54|1@1+ (1,0) [0|1] "" Vector__XXX
 SG_ UI_a056_ManualECallButtonDisconn : 55|1@1+ (1,0) [0|1] "" Vector__XXX
 SG_ UI_a057_CellAntennaDisconnected : 56|1@1+ (1,0) [0|1] "" Vector__XXX
 SG_ UI_a058_GPSAntennaDisconnected : 57|1@1+ (1,0) [0|1] "" Vector__XXX
 SG_ UI_a059_ECallSpeakerDisconnected : 58|1@1+ (1,0) [0|1] "" Vector__XXX
 SG_ UI_a060_ECallMicDisconnected : 59|1@1+ (1,0) [0|1] "" Vector__XXX
 SG_ UI_a061_SIMTestFailed : 60|1@1+ (1,0) [0|1] "" Vector__XXX
 SG_ UI_a062_ENSTestFailed : 61|1@1+ (1,0) [0|1] "" Vector__XXX
 SG_ UI_a063_CellularTestFailed : 62|1@1+ (1,0) [0|1] "" Vector__XXX
 SG_ UI_a064_ModemFirmwareTestFailed : 63|1@1+ (1,0) [0|1] "" Vector__XXX

BO_ 292 UI_alertMatrix2: 8 UI
 SG_ UI_a065_WiFiRecoveryReset : 0|1@1+ (1,0) [0|1] "" Vector__XXX
 SG_ UI_a066_GpuHangDetected : 1|1@1+ (1,0) [0|1] "" Vector__XXX
 SG_ UI_a067_WarnOnI915 : 2|1@1+ (1,0) [0|1] "" Vector__XXX
 SG_ UI_a068_VideoUnexpectedExit : 3|1@1+ (1,0) [0|1] "" Vector__XXX
 SG_ UI_a069_VideoUDPTimeout : 4|1@1+ (1,0) [0|1] "" Vector__XXX
 SG_ UI_a070_VideoPipelineWarning : 5|1@1+ (1,0) [0|1] "" Vector__XXX
 SG_ UI_a071_VideoPipelineError : 6|1@1+ (1,0) [0|1] "" Vector__XXX
 SG_ UI_a072_ECallAnalogMicFailed : 7|1@1+ (1,0) [0|1] "" Vector__XXX
 SG_ UI_a073_ECallDigitalMicFailed : 8|1@1+ (1,0) [0|1] "" Vector__XXX
 SG_ UI_a074_EMMCHangDetected : 9|1@1+ (1,0) [0|1] "" Vector__XXX
 SG_ UI_a075_BackupCameraInitError : 10|1@1+ (1,0) [0|1] "" Vector__XXX
 SG_ UI_a076_NumFalseManualECalls : 11|1@1+ (1,0) [0|1] "" Vector__XXX
 SG_ UI_a077_AudioA2bMicChannelSwap : 12|1@1+ (1,0) [0|1] "" Vector__XXX
 SG_ UI_a078_DashcamUsbDriveUnmountab : 13|1@1+ (1,0) [0|1] "" Vector__XXX
 SG_ UI_a079_DashcamUsbDriveFull : 14|1@1+ (1,0) [0|1] "" Vector__XXX
 SG_ UI_a080_DashcamUsbDriveSlow : 15|1@1+ (1,0) [0|1] "" Vector__XXX
 SG_ UI_a081_CellModemSearchExpired : 16|1@1+ (1,0) [0|1] "" Vector__XXX
 SG_ UI_a082_NumModemRebootStuckInECa : 17|1@1+ (1,0) [0|1] "" Vector__XXX
 SG_ UI_a083_ECallProxyWatchdogTrigge : 18|1@1+ (1,0) [0|1] "" Vector__XXX
 SG_ UI_a084_SerializerError : 19|1@1+ (1,0) [0|1] "" Vector__XXX
 SG_ UI_a085_DeserializerError : 20|1@1+ (1,0) [0|1] "" Vector__XXX
 SG_ UI_a086_TouchEnumerationError : 21|1@1+ (1,0) [0|1] "" Vector__XXX
 SG_ UI_a087_BmpReset : 22|1@1+ (1,0) [0|1] "" Vector__XXX
 SG_ UI_a088_CellRemovableSimMissing : 23|1@1+ (1,0) [0|1] "" Vector__XXX
 SG_ UI_a089_RadioSoftResetError : 24|1@1+ (1,0) [0|1] "" Vector__XXX
 SG_ UI_a090_RadioPingFailError : 25|1@1+ (1,0) [0|1] "" Vector__XXX
 SG_ UI_a091_VehicleLinkStall : 26|1@1+ (1,0) [0|1] "" Vector__XXX
 SG_ UI_a092_updateStarted : 27|1@1+ (1,0) [0|1] "" Vector__XXX
 SG_ UI_a093_updateEnded : 28|1@1+ (1,0) [0|1] "" Vector__XXX
 SG_ UI_a094_ModemPowerOnFailure : 29|1@1+ (1,0) [0|1] "" Vector__XXX
 SG_ UI_a095_CidStorageRunningLow : 30|1@1+ (1,0) [0|1] "" Vector__XXX
 SG_ UI_a096_VideodPipelineIssueDetec : 31|1@1+ (1,0) [0|1] "" Vector__XXX
 SG_ UI_a097_AudiodRestarted : 32|1@1+ (1,0) [0|1] "" Vector__XXX
 SG_ UI_a098_DiskCheckFailure : 33|1@1+ (1,0) [0|1] "" Vector__XXX
 SG_ UI_a099_eMMCStatusError : 34|1@1+ (1,0) [0|1] "" Vector__XXX
 SG_ UI_a100_eMMCFTLError : 35|1@1+ (1,0) [0|1] "" Vector__XXX
 SG_ UI_a101_wifiStackProblem : 36|1@1+ (1,0) [0|1] "" Vector__XXX
 SG_ UI_a102_A2bDiscoveryFailed : 37|1@1+ (1,0) [0|1] "" Vector__XXX
 SG_ UI_a103_UsbHubNotEnumerating : 38|1@1+ (1,0) [0|1] "" Vector__XXX
 SG_ UI_a104_DashcamUsbDriveMissing : 39|1@1+ (1,0) [0|1] "" Vector__XXX
 SG_ UI_a105_firmwareReinstallRequest : 40|1@1+ (1,0) [0|1] "" Vector__XXX
 SG_ UI_a106_rebootBackstopTriggered : 41|1@1+ (1,0) [0|1] "" Vector__XXX
 SG_ UI_a107_DashcamUsbDriveTooBigFor : 42|1@1+ (1,0) [0|1] "" Vector__XXX
 SG_ UI_a108_DashcamUsbDriveGettingFu : 43|1@1+ (1,0) [0|1] "" Vector__XXX
 SG_ UI_a109_DashcamUsbDriveTooSmall : 44|1@1+ (1,0) [0|1] "" Vector__XXX
 SG_ UI_a110_DashcamUsbDriveCorrupt : 45|1@1+ (1,0) [0|1] "" Vector__XXX
 SG_ UI_a111_DashcamUsbDriveNotSuperS : 46|1@1+ (1,0) [0|1] "" Vector__XXX
 SG_ UI_a112_badUSBDevice : 47|1@1+ (1,0) [0|1] "" Vector__XXX
 SG_ UI_a113_DashcamHasOnboardSentryC : 48|1@1+ (1,0) [0|1] "" Vector__XXX
 SG_ UI_a114_drivingVisualizationDegr : 49|1@1+ (1,0) [0|1] "" Vector__XXX
 SG_ UI_a115_IrisEDLMode : 50|1@1+ (1,0) [0|1] "" Vector__XXX
 SG_ UI_a116_UncorrectableMemoryError : 51|1@1+ (1,0) [0|1] "" Vector__XXX
 SG_ UI_a117_VehicleSelfTestRunning : 52|1@1+ (1,0) [0|1] "" Vector__XXX
 SG_ UI_a118_NVMeReset : 53|1@1+ (1,0) [0|1] "" Vector__XXX
 SG_ UI_a119_nvmeBlockDeviceMissing : 54|1@1+ (1,0) [0|1] "" Vector__XXX
 SG_ UI_a120_nvmePCIeLinkErrorDetecte : 55|1@1+ (1,0) [0|1] "" Vector__XXX
 SG_ UI_a121_nvmeSmartLogCritical : 56|1@1+ (1,0) [0|1] "" Vector__XXX
 SG_ UI_a122_AMDI2C0LostArbitration : 57|1@1+ (1,0) [0|1] "" Vector__XXX
 SG_ UI_a123_AMDI2C1LostArbitration : 58|1@1+ (1,0) [0|1] "" Vector__XXX
 SG_ UI_a124_AMDI2C0TxRxAborted : 59|1@1+ (1,0) [0|1] "" Vector__XXX
 SG_ UI_a125_AMDI2C1TxRxAborted : 60|1@1+ (1,0) [0|1] "" Vector__XXX
 SG_ UI_a126_UsbErrorDriveCorrupt : 61|1@1+ (1,0) [0|1] "" Vector__XXX
 SG_ UI_a128_dgpuNotDetected : 63|1@1+ (1,0) [0|1] "" Vector__XXX

BO_ 293 UI_alertMatrix3: 8 UI
 SG_ UI_a129_dgpuOperationFailure : 0|1@1+ (1,0) [0|1] "" Vector__XXX
 SG_ UI_a130_QtCarClusterExitError : 1|1@1+ (1,0) [0|1] "" Vector__XXX
 SG_ UI_a131_DisplayPortFailure : 2|1@1+ (1,0) [0|1] "" Vector__XXX
 SG_ UI_a132_AdspWatchdogRecoveryTrig : 3|1@1+ (1,0) [0|1] "" Vector__XXX
 SG_ UI_a133_AdspWatchdogRecoveryFail : 4|1@1+ (1,0) [0|1] "" Vector__XXX
 SG_ UI_a134_DashcamUsbDriveNoMedium : 5|1@1+ (1,0) [0|1] "" Vector__XXX
 SG_ UI_a135_warnRunOverlayExists : 6|1@1+ (1,0) [0|1] "" Vector__XXX
 SG_ UI_a136_warnSettingsConfExists : 7|1@1+ (1,0) [0|1] "" Vector__XXX
 SG_ UI_a137_ServiceShellActiveConnec : 8|1@1+ (1,0) [0|1] "" Vector__XXX
 SG_ UI_a138_applyingConfigChange : 9|1@1+ (1,0) [0|1] "" Vector__XXX
 SG_ UI_a139_postponedConfigChange : 10|1@1+ (1,0) [0|1] "" Vector__XXX
 SG_ UI_a140_NeverSleepActive : 11|1@1+ (1,0) [0|1] "" Vector__XXX
 SG_ UI_a141_falconDoorOpen : 12|1@1+ (1,0) [0|1] "" Vector__XXX
 SG_ UI_a142_CorrectableMemoryError : 13|1@1+ (1,0) [0|1] "" Vector__XXX
 SG_ UI_a143_FPSCrawling : 14|1@1+ (1,0) [0|1] "" Vector__XXX
 SG_ UI_a144_nvmeWarning : 15|1@1+ (1,0) [0|1] "" Vector__XXX
 SG_ UI_a145_nvmeUnsafeShutdown : 16|1@1+ (1,0) [0|1] "" Vector__XXX
 SG_ UI_a146_nvmeNeedsReplacement : 17|1@1+ (1,0) [0|1] "" Vector__XXX
 SG_ UI_a147_ASILGlobalError : 18|1@1+ (1,0) [0|1] "" Vector__XXX
 SG_ UI_a148_SleepFailure : 19|1@1+ (1,0) [0|1] "" Vector__XXX
 SG_ UI_a149_DisplayCheckFailure : 20|1@1+ (1,0) [0|1] "" Vector__XXX
 SG_ UI_a150_infoCPURunningHot : 21|1@1+ (1,0) [0|1] "" Vector__XXX
 SG_ UI_a151_carComputerThermalProble : 22|1@1+ (1,0) [0|1] "" Vector__XXX
 SG_ UI_a152_infoThrottling : 23|1@1+ (1,0) [0|1] "" Vector__XXX
 SG_ UI_a153_serviceRestarted : 24|1@1+ (1,0) [0|1] "" Vector__XXX
 SG_ UI_a154_AudiodBufferError : 25|1@1+ (1,0) [0|1] "" Vector__XXX
 SG_ UI_a155_UsbFrontHubUnavailable : 26|1@1+ (1,0) [0|1] "" Vector__XXX
 SG_ UI_a156_UsbFrontHubInstallMismat : 27|1@1+ (1,0) [0|1] "" Vector__XXX
 SG_ UI_a157_MCUActiveCoolingRequeste : 28|1@1+ (1,0) [0|1] "" Vector__XXX
 SG_ UI_a158_UsbDeviceMountError : 29|1@1+ (1,0) [0|1] "" Vector__XXX
 SG_ UI_a159_AudioHeartbeatFailure : 30|1@1+ (1,0) [0|1] "" Vector__XXX
 SG_ UI_a160_SystemWatchdogFailure : 31|1@1+ (1,0) [0|1] "" Vector__XXX
 SG_ UI_a161_ECallTemporarilyUnavaila : 32|1@1+ (1,0) [0|1] "" Vector__XXX
 SG_ UI_a162_voiceRecClipsUploaded : 33|1@1+ (1,0) [0|1] "" Vector__XXX
 SG_ UI_a163_QtCarVehicleExitError : 34|1@1+ (1,0) [0|1] "" Vector__XXX
 SG_ UI_a164_AudiodConnTimeout : 35|1@1+ (1,0) [0|1] "" Vector__XXX
 SG_ UI_a165_fsCorrupted : 36|1@1+ (1,0) [0|1] "" Vector__XXX
 SG_ UI_a166_fsError : 37|1@1+ (1,0) [0|1] "" Vector__XXX
 SG_ UI_a167_CgroupOverMemKill : 38|1@1+ (1,0) [0|1] "" Vector__XXX
 SG_ UI_a168_dgpuPowerOnSelfTestFailu : 39|1@1+ (1,0) [0|1] "" Vector__XXX
 SG_ UI_a169_SteamLoadShedFailure : 40|1@1+ (1,0) [0|1] "" Vector__XXX
 SG_ UI_a170_AMDdGPULoadShedFailure : 41|1@1+ (1,0) [0|1] "" Vector__XXX
 SG_ UI_a171_GraphicsLoadShedRequeste : 42|1@1+ (1,0) [0|1] "" Vector__XXX
 SG_ UI_a172_GraphicsLoadShedUIFailur : 43|1@1+ (1,0) [0|1] "" Vector__XXX
 SG_ UI_a173_pmSuspendFailure : 44|1@1+ (1,0) [0|1] "" Vector__XXX
 SG_ UI_a174_HistorySaveLoop : 45|1@1+ (1,0) [0|1] "" Vector__XXX
 SG_ UI_a176_CellularAntennaAlert : 47|1@1+ (1,0) [0|1] "" Vector__XXX
 SG_ UI_a177_MediaPlayerFailure : 48|1@1+ (1,0) [0|1] "" Vector__XXX
 SG_ UI_a178_irqDisabled : 49|1@1+ (1,0) [0|1] "" Vector__XXX
 SG_ UI_a179_TestDriveVideoDownloadFa : 50|1@1+ (1,0) [0|1] "" Vector__XXX
 SG_ UI_a180_AudiodInputRestarted : 51|1@1+ (1,0) [0|1] "" Vector__XXX
 SG_ UI_a181_ModemFirmwareVersionMism : 52|1@1+ (1,0) [0|1] "" Vector__XXX
 SG_ UI_a182_VideoPipelineOverrun : 53|1@1+ (1,0) [0|1] "" Vector__XXX
 SG_ UI_a183_DDAWFaulted : 54|1@1+ (1,0) [0|1] "" Vector__XXX
 SG_ UI_a184_ISAFaulted : 55|1@1+ (1,0) [0|1] "" Vector__XXX
 SG_ UI_a185_ELKSDisabled : 56|1@1+ (1,0) [0|1] "" Vector__XXX
 SG_ UI_a186_ELKSUnavailable : 57|1@1+ (1,0) [0|1] "" Vector__XXX
 SG_ UI_a187_TunerFirmwareMismatchedV : 58|1@1+ (1,0) [0|1] "" Vector__XXX
 SG_ UI_a188_TunerFirmwareMismatchedA : 59|1@1+ (1,0) [0|1] "" Vector__XXX
 SG_ UI_a189_TunerWatchdogReset : 60|1@1+ (1,0) [0|1] "" Vector__XXX
 SG_ UI_a190_TunerMIA : 61|1@1+ (1,0) [0|1] "" Vector__XXX
 SG_ UI_a191_TunerUpdateFailed : 62|1@1+ (1,0) [0|1] "" Vector__XXX
 SG_ UI_a192_AudioWatchdogReboot : 63|1@1+ (1,0) [0|1] "" Vector__XXX

BO_ 294 UI_alertMatrix4: 8 UI
 SG_ UI_a193_TcuRNandFwVersionMismatc : 0|1@1+ (1,0) [0|1] "" Vector__XXX
 SG_ UI_a194_AudioweaverRestarted : 1|1@1+ (1,0) [0|1] "" Vector__XXX
 SG_ UI_a195_gtwMfdUdpApiFired : 2|1@1+ (1,0) [0|1] "" Vector__XXX
 SG_ UI_a196_AMDI2C3BusInoperable : 3|1@1+ (1,0) [0|1] "" Vector__XXX
 SG_ UI_a197_AMDI2C1BusInoperable : 4|1@1+ (1,0) [0|1] "" Vector__XXX
 SG_ UI_a198_IncompatibleBTUSBHubHard : 5|1@1+ (1,0) [0|1] "" Vector__XXX
 SG_ UI_a199_HighAPedalDetectedAtColl : 6|1@1+ (1,0) [0|1] "" Vector__XXX
 SG_ UI_a200_UIFirmwareVersionMismatc : 7|1@1+ (1,0) [0|1] "" Vector__XXX
 SG_ UI_a201_rearDisplayDisconnected : 8|1@1+ (1,0) [0|1] "" Vector__XXX
 SG_ UI_a202_sysMemoryIncorrect : 9|1@1+ (1,0) [0|1] "" Vector__XXX
 SG_ UI_a204_ModemSleepFailure : 11|1@1+ (1,0) [0|1] "" Vector__XXX
 SG_ UI_a205_ModemSleepSignalMismatch : 12|1@1+ (1,0) [0|1] "" Vector__XXX
 SG_ UI_a206_ModemMIAAfterWake : 13|1@1+ (1,0) [0|1] "" Vector__XXX
 SG_ UI_a207_mqttClientDisconnected : 14|1@1+ (1,0) [0|1] "" Vector__XXX
 SG_ UI_a208_mqttDisconnectReason : 15|1@1+ (1,0) [0|1] "" Vector__XXX
 SG_ UI_a209_dataCallDisconnected : 16|1@1+ (1,0) [0|1] "" Vector__XXX
 SG_ UI_a210_CellularCSRegFail : 17|1@1+ (1,0) [0|1] "" Vector__XXX
 SG_ UI_a211_AEBSDisabled : 18|1@1+ (1,0) [0|1] "" Vector__XXX
 SG_ UI_a212_AEBSFaulted : 19|1@1+ (1,0) [0|1] "" Vector__XXX
 SG_ UI_a213_ISADisabled : 20|1@1+ (1,0) [0|1] "" Vector__XXX
 SG_ UI_a214_pmHelperFailure : 21|1@1+ (1,0) [0|1] "" Vector__XXX
 SG_ UI_a215_compositorStallDetected : 22|1@1+ (1,0) [0|1] "" Vector__XXX
 SG_ UI_a216_AudioA2bCircuitProblem : 23|1@1+ (1,0) [0|1] "" Vector__XXX
 SG_ UI_a217_CgroupMemoryPressure : 24|1@1+ (1,0) [0|1] "" Vector__XXX
 SG_ UI_a218_AudiodNoAudioDevices : 25|1@1+ (1,0) [0|1] "" Vector__XXX
 SG_ UI_a219_CompositorWatchdog : 26|1@1+ (1,0) [0|1] "" Vector__XXX
 SG_ UI_a220_MediaBrowseError : 27|1@1+ (1,0) [0|1] "" Vector__XXX
 SG_ UI_a221_NavigationServiceError : 28|1@1+ (1,0) [0|1] "" Vector__XXX
 SG_ UI_a222_QtCarRestart : 29|1@1+ (1,0) [0|1] "" Vector__XXX
 SG_ UI_a223_databaseError : 30|1@1+ (1,0) [0|1] "" Vector__XXX
 SG_ UI_a224_centerDisplayDisconnecte : 31|1@1+ (1,0) [0|1] "" Vector__XXX
 SG_ UI_a225_clusterDisplayDisconnect : 32|1@1+ (1,0) [0|1] "" Vector__XXX
 SG_ UI_a226_largePhoneContactSync : 33|1@1+ (1,0) [0|1] "" Vector__XXX
 SG_ UI_a228_pipewireXrunBurst : 35|1@1+ (1,0) [0|1] "" Vector__XXX
 SG_ UI_a229_SerDesError : 36|1@1+ (1,0) [0|1] "" Vector__XXX
 SG_ UI_a230_ModemSimCardMismatch : 37|1@1+ (1,0) [0|1] "" Vector__XXX
 SG_ UI_a231_SleepCancelled : 38|1@1+ (1,0) [0|1] "" Vector__XXX
 SG_ UI_a232_processExitError : 39|1@1+ (1,0) [0|1] "" Vector__XXX
 SG_ UI_a233_ModemRFFailure : 40|1@1+ (1,0) [0|1] "" Vector__XXX
 SG_ UI_a234_AMDI2C0Timeout : 41|1@1+ (1,0) [0|1] "" Vector__XXX
 SG_ UI_a235_AMDI2C1Timeout : 42|1@1+ (1,0) [0|1] "" Vector__XXX
 SG_ UI_a236_ModemOnResetState : 43|1@1+ (1,0) [0|1] "" Vector__XXX
 SG_ UI_a237_ClipUploadActive : 44|1@1+ (1,0) [0|1] "" Vector__XXX
 SG_ UI_a238_ModemConfigMismatch : 45|1@1+ (1,0) [0|1] "" Vector__XXX
 SG_ UI_a239_stateOfVehiclesFunctions : 46|1@1+ (1,0) [0|1] "" Vector__XXX
 SG_ UI_a240_ethError : 47|1@1+ (1,0) [0|1] "" Vector__XXX
 SG_ UI_a241_AxCPError : 48|1@1+ (1,0) [0|1] "" Vector__XXX

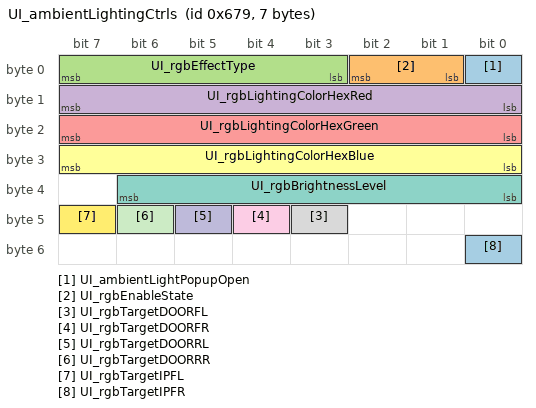
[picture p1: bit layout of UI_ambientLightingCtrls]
BO_ 1657 UI_ambientLightingCtrls: 7 UI
 SG_ UI_ambientLightPopupOpen : 0|1@1+ (1,0) [0|1] "" Vector__XXX
 SG_ UI_rgbEnableState : 1|2@1+ (1,0) [0|3] "" Vector__XXX
 SG_ UI_rgbEffectType : 3|5@1+ (1,0) [0|31] "" Vector__XXX
 SG_ UI_rgbLightingColorHexRed : 8|8@1+ (1,0) [0|255] "" Vector__XXX
 SG_ UI_rgbLightingColorHexGreen : 16|8@1+ (1,0) [0|255] "" Vector__XXX
 SG_ UI_rgbLightingColorHexBlue : 24|8@1+ (1,0) [0|255] "" Vector__XXX
 SG_ UI_rgbBrightnessLevel : 32|7@1+ (1,0) [0|100] "%" Vector__XXX
 SG_ UI_rgbTargetDOORFL : 43|1@1+ (1,0) [0|1] "" Vector__XXX
 SG_ UI_rgbTargetDOORFR : 44|1@1+ (1,0) [0|1] "" Vector__XXX
 SG_ UI_rgbTargetDOORRL : 45|1@1+ (1,0) [0|1] "" Vector__XXX
 SG_ UI_rgbTargetDOORRR : 46|1@1+ (1,0) [0|1] "" Vector__XXX
 SG_ UI_rgbTargetIPFL : 47|1@1+ (1,0) [0|1] "" Vector__XXX
 SG_ UI_rgbTargetIPFR : 48|1@1+ (1,0) [0|1] "" Vector__XXX

BO_TX_BU_ 1560 : UDS;
BO_TX_BU_ 1603 : UDS;
BO_TX_BU_ 1614 : UDS;
BO_TX_BU_ 1576 : UDS;
BO_TX_BU_ 1634 : UDS;
BO_TX_BU_ 1568 : UDS;
BO_TX_BU_ 1604 : UDS;
BO_TX_BU_ 1540 : UDS;
BO_TX_BU_ 1734 : UDS;
BO_TX_BU_ 1649 : UDS;
BO_TX_BU_ 1601 : UDS;
BO_TX_BU_ 1664 : UDS;
BO_TX_BU_ 1723 : UDS;
BO_TX_BU_ 1611 : UDS;
BO_TX_BU_ 1551 : UDS;
BO_TX_BU_ 1615 : UDS;
BO_TX_BU_ 1578 : UDS;
BO_TX_BU_ 1588 : UDS;
BO_TX_BU_ 1636 : UDS;
BO_TX_BU_ 1580 : UDS;
BO_TX_BU_ 1582 : UDS;
BO_TX_BU_ 1536 : UDS;
BO_TX_BU_ 1570 : UDS;
BO_TX_BU_ 1544 : UDS;
BO_TX_BU_ 1546 : UDS;
BO_TX_BU_ 1056 : UIS;
BO_TX_BU_ 1154 : UI;
BO_TX_BU_ 1153 : UI;
BO_TX_BU_ 979 : UI;
BO_TX_BU_ 1523 : UI;
BO_TX_BU_ 291 : UI;
BO_TX_BU_ 292 : UI;
BO_TX_BU_ 293 : UI;
BO_TX_BU_ 294 : UI;
BO_TX_BU_ 1657 : UI;
CM_ BO_ 1560 "UDS ECU message: icr request";
CM_ SG_ 1560 UDS_icrRequestData "UDS ECU: icr request data";
CM_ BO_ 1603 "UDS ECU message: ocs1p request";
CM_ SG_ 1603 UDS_ocs1pRequestData "UDS ECU: ocs1p request data";
CM_ BO_ 1614 "UDS ECU message: park request";
CM_ SG_ 1614 UDS_parkRequestData "UDS ECU: park request data";
CM_ BO_ 1576 "UDS ECU message: pcs request";
CM_ SG_ 1576 UDS_pcsRequestData "UDS ECU: pcs request data";
CM_ BO_ 1634 "UDS ECU message: plg request";
CM_ SG_ 1634 UDS_plgRequestData "UDS ECU: plg request data";
CM_ BO_ 1568 "UDS ECU message: pm request";
CM_ SG_ 1568 UDS_pmRequestData "UDS ECU: pm request data";
CM_ BO_ 1604 "UDS ECU message: pmf request";
CM_ SG_ 1604 UDS_pmfRequestData "UDS ECU: pmf request data";
CM_ BO_ 1540 "UDS ECU message: pmr request";
CM_ SG_ 1540 UDS_pmrRequestData "UDS ECU: pmr request data";
CM_ BO_ 1734 "UDS ECU message: ptc request";
CM_ SG_ 1734 UDS_ptcRequestData "UDS ECU: ptc request data";
CM_ BO_ 1649 "UDS ECU message: radc request";
CM_ SG_ 1649 UDS_radcRequestData "UDS ECU: radc request data";
CM_ BO_ 1601 "UDS ECU message: rcm request";
CM_ SG_ 1601 UDS_rcmRequestData "UDS ECU: rcm request data";
CM_ BO_ 1664 "UDS ECU message: sccm request";
CM_ SG_ 1664 UDS_sccmRequestData "UDS ECU: sccm request data";
CM_ BO_ 1723 "UDS ECU message: sdcr request";
CM_ SG_ 1723 UDS_sdcrRequestData "UDS ECU: sdcr request data";
CM_ BO_ 1611 "UDS ECU message: tas request";
CM_ SG_ 1611 UDS_tasRequestData "UDS ECU: tas request data";
CM_ BO_ 1551 "UDS ECU message: thc request";
CM_ SG_ 1551 UDS_thcRequestData_H "UDS ECU: thc request data h";
CM_ SG_ 1551 UDS_thcRequestData_L "UDS ECU: thc request data l";
CM_ BO_ 1615 "UDS ECU message: tpms request";
CM_ SG_ 1615 UDS_tpmsRequestData "UDS ECU: tpms request data";
CM_ BO_ 1578 "UDS ECU message: vcbatt1 request";
CM_ SG_ 1578 UDS_vcbatt1RequestData "UDS ECU: vcbatt1 request data";
CM_ BO_ 1588 "UDS ECU message: vcbatt2 request";
CM_ SG_ 1588 UDS_vcbatt2RequestData "UDS ECU: vcbatt2 request data";
CM_ BO_ 1636 "UDS ECU message: vcbatt request";
CM_ SG_ 1636 UDS_vcbattRequestData "UDS ECU: vcbatt request data";
CM_ BO_ 1580 "UDS ECU message: vcfront1 request";
CM_ SG_ 1580 UDS_vcfront1RequestData "UDS ECU: vcfront1 request data";
CM_ BO_ 1582 "UDS ECU message: vcfront2 request";
CM_ SG_ 1582 UDS_vcfront2RequestData "UDS ECU: vcfront2 request data";
CM_ BO_ 1536 "UDS ECU message: vcfront request";
CM_ SG_ 1536 UDS_vcfrontRequestData "UDS ECU: vcfront request data";
CM_ BO_ 1570 "UDS ECU message: vcleft request";
CM_ SG_ 1570 UDS_vcleftRequestData_H "UDS ECU: vcleft request data h";
CM_ SG_ 1570 UDS_vcleftRequestData_L "UDS ECU: vcleft request data l";
CM_ BO_ 1544 "UDS ECU message: vcright request";
CM_ SG_ 1544 UDS_vcrightRequestData_H "UDS ECU: vcright request data h";
CM_ SG_ 1544 UDS_vcrightRequestData_L "UDS ECU: vcright request data l";
CM_ BO_ 1546 "UDS ECU message: vcsec request";
CM_ SG_ 1546 UDS_vcsecRequestData "UDS ECU: vcsec request data";
CM_ BO_ 1056 "UIS ECU message: log";
CM_ SG_ 1056 UIS_logMux "UIS ECU: log mux";
CM_ SG_ 1056 UIS_zramWriteTicks "UIS ECU: zram write ticks";
CM_ SG_ 1056 UIS_zramWriteIO "UIS ECU: zram write IO";
CM_ SG_ 1056 UIS_zramReadTicks "UIS ECU: zram read ticks";
CM_ SG_ 1056 UIS_zramReadIO "UIS ECU: zram read IO";
CM_ SG_ 1056 UIS_zramOriginalSize "UIS ECU: zram original size";
CM_ SG_ 1056 UIS_zramNotifyFree "UIS ECU: zram notify free";
CM_ SG_ 1056 UIS_zramInvalidIO "UIS ECU: zram invalid IO";
CM_ SG_ 1056 UIS_zramFailedWrites "UIS ECU: zram failed writes";
CM_ SG_ 1056 UIS_zramFailedReads "UIS ECU: zram failed reads";
CM_ SG_ 1056 UIS_zramCompressionRatio "UIS ECU: zram compression ratio";
CM_ SG_ 1056 UIS_zramCompressedSize "UIS ECU: zram compressed size";
CM_ SG_ 1056 UIS_wifiTemperature "Current temperature reported for wifi";
CM_ SG_ 1056 UIS_wifiStackState "WiFi stack state description";
CM_ SG_ 1056 UIS_wifiStackReady "UIS ECU: wifi stack ready";
CM_ SG_ 1056 UIS_wifiBars "WiFi bars for connected network";
CM_ SG_ 1056 UIS_wifiAutoJoinLowRSSI "Indicates an attempt to auto-join a known network with low Received Signal Strength Indicator (RSSI).";
CM_ SG_ 1056 UIS_webbrowserMemUsage "UIS ECU: webbrowser mem usage";
CM_ SG_ 1056 UIS_webbrowserCPUUsage "UIS ECU: webbrowser CPU usage";
CM_ SG_ 1056 UIS_vmtouchMemUsage "UIS ECU: vmtouch mem usage";
CM_ SG_ 1056 UIS_vmtouchCPUUsage "UIS ECU: vmtouch CPU usage";
CM_ SG_ 1056 UIS_videodMemUsage "UIS ECU: videod mem usage";
CM_ SG_ 1056 UIS_videodCPUUsage "UIS ECU: videod CPU usage";
CM_ SG_ 1056 UIS_vehicleMemUsage "UIS ECU: vehicle mem usage";
CM_ SG_ 1056 UIS_vehicleCPUUsage "UIS ECU: vehicle CPU usage";
CM_ SG_ 1056 UIS_valhallaserverMemUsage "UIS ECU: valhallaserver mem usage";
CM_ SG_ 1056 UIS_valhallaserverCPUUsage "UIS ECU: valhallaserver CPU usage";
CM_ SG_ 1056 UIS_valetMode "UI Valet Mode state";
CM_ SG_ 1056 UIS_uiQtCarUptime "Touchscreen UI software uptime";
CM_ SG_ 1056 UIS_uiQtCarSwapUsage "Signal reported by UIS ECU";
CM_ SG_ 1056 UIS_uiMeanFPS "UI mean frames per second over a 60s period";
CM_ SG_ 1056 UIS_uiMaxFrametime "UIS ECU: ui max frametime";
CM_ SG_ 1056 UIS_uiFramesOver200Ms "UIS ECU: ui frames over200 ms";
CM_ SG_ 1056 UIS_uiFramesOver100Ms "UIS ECU: ui frames over100 ms";
CM_ SG_ 1056 UIS_tunerVoltageUBatt "UIS ECU: tuner voltage u batt";
CM_ SG_ 1056 UIS_tunerVoltageOperation "Radio tuner operating voltage (mV)";
CM_ SG_ 1056 UIS_tunerVoltageMQS "UIS ECU: tuner voltage MQS";
CM_ SG_ 1056 UIS_tunerVoltageAntenna2 "Radio tuner voltage (mV) for antenna 2";
CM_ SG_ 1056 UIS_tunerVoltageAntenna1 "Radio tuner voltage (mV) for antenna 1";
CM_ SG_ 1056 UIS_tunerVoltage3V3 "UIS ECU: tuner voltage3 V3";
CM_ SG_ 1056 UIS_tunerVoltage1V8 "UIS ECU: tuner voltage1 V8";
CM_ SG_ 1056 UIS_tunerTemperatureFahrenheit "UIS ECU: tuner temperature fahrenheit";
CM_ SG_ 1056 UIS_tunerTemperatureCelsius "UIS ECU: tuner temperature celsius";
CM_ SG_ 1056 UIS_tunerCurrentAntenna2 "Radio tuner current (mA) for antenna 2";
CM_ SG_ 1056 UIS_tunerCurrentAntenna1 "Radio tuner current (mA) for antenna 1";
CM_ SG_ 1056 UIS_touchEventsAggCount "UIS ECU: touch events agg count";
CM_ SG_ 1056 UIS_tmserverMemUsage "UIS ECU: tmserver mem usage";
CM_ SG_ 1056 UIS_tmserverCPUUsage "UIS ECU: tmserver CPU usage";
CM_ SG_ 1056 UIS_testDriveMode "UIS ECU: test drive mode";
CM_ SG_ 1056 UIS_teslachromiumMemUsage "UIS ECU: teslachromium mem usage";
CM_ SG_ 1056 UIS_teslachromiumCPUUsage "UIS ECU: teslachromium CPU usage";
CM_ SG_ 1056 UIS_teslacefzygotMemUsage "UIS ECU: teslacefzygot mem usage";
CM_ SG_ 1056 UIS_teslacefzygotCPUUsage "UIS ECU: teslacefzygot CPU usage";
CM_ SG_ 1056 UIS_teslacefgpuMemUsage "UIS ECU: teslacefgpu mem usage";
CM_ SG_ 1056 UIS_teslacefgpuCPUUsage "UIS ECU: teslacefgpu CPU usage";
CM_ SG_ 1056 UIS_teslaMediaCacheSize "UIS ECU: tesla media cache size";
CM_ SG_ 1056 UIS_teslaMediaCacheCost "UIS ECU: tesla media cache cost";
CM_ SG_ 1056 UIS_tegraModemManState "Tegra Cellular Modem Manager state";
CM_ SG_ 1056 UIS_systemWakeTime "Length of time since wake or boot if UI has not slept (seconds)";
CM_ SG_ 1056 UIS_systemUptime "Reports the system uptime duration.";
CM_ SG_ 1056 UIS_systemMemSwapUsage "UIS ECU: system mem swap usage";
CM_ SG_ 1056 UIS_suspensionGeofence "Status of suspension geofence add or remove";
CM_ SG_ 1056 UIS_superchargePaymentNeeded "Reports that Supercharging payment is needed.";
CM_ SG_ 1056 UIS_sudokuMemUsage "UIS ECU: sudoku mem usage";
CM_ SG_ 1056 UIS_sudokuCPUUsage "UIS ECU: sudoku CPU usage";
CM_ SG_ 1056 UIS_spotifyserverMemUsage "UIS ECU: spotifyserver mem usage";
CM_ SG_ 1056 UIS_spotifyserverCPUUsage "UIS ECU: spotifyserver CPU usage";
CM_ SG_ 1056 UIS_speechrecoMemUsage "UIS ECU: speechreco mem usage";
CM_ SG_ 1056 UIS_speechrecoCPUUsage "UIS ECU: speechreco CPU usage";
CM_ SG_ 1056 UIS_solitaireMemUsage "UIS ECU: solitaire mem usage";
CM_ SG_ 1056 UIS_solitaireCPUUsage "UIS ECU: solitaire CPU usage";
CM_ SG_ 1056 UIS_sleepType "Reports the system sleep type.";
CM_ SG_ 1056 UIS_sleepTime "Reports the system sleep duration.";
CM_ SG_ 1056 UIS_sleepState "Reports the system sleep state.";
CM_ SG_ 1056 UIS_sleepCount "UIS ECU: sleep count";
CM_ SG_ 1056 UIS_slackerLoginResult "Reports Slacker Media login events";
CM_ SG_ 1056 UIS_settingsAutoTurnSignal "UIS ECU: settings auto turn signal";
CM_ SG_ 1056 UIS_serviceModePlus "Signal reported by UIS ECU";
CM_ SG_ 1056 UIS_serviceMode "Signal reported by UIS ECU";
CM_ SG_ 1056 UIS_serverMemUsage "UIS ECU: server mem usage";
CM_ SG_ 1056 UIS_serverCPUUsage "UIS ECU: server CPU usage";
CM_ SG_ 1056 UIS_sentryState "Sentry Mode state";
CM_ SG_ 1056 UIS_sentryNeedsNap "Sentry Mode sleep indicator, max uptime reached";
CM_ SG_ 1056 UIS_sentryIncidentCount "Sentry Mode incident count, initializes to 0";
CM_ SG_ 1056 UIS_scheduledChargingMode "Scheduled charging mode";
CM_ SG_ 1056 UIS_scheduleChargeStartTime "Reports the scheduled charging start date time in MMDDHHMM format.";
CM_ SG_ 1056 UIS_scheduleChargeEndTime "Reports the scheduled charging end date time in MMDDHHMM format.";
CM_ SG_ 1056 UIS_remoteRequestType "Reports the signed remote request type sent to vehicle, excluding closures and start requests.";
CM_ SG_ 1056 UIS_releasenotesMemUsage "UIS ECU: releasenotes mem usage";
CM_ SG_ 1056 UIS_releasenotesCPUUsage "UIS ECU: releasenotes CPU usage";
CM_ SG_ 1056 UIS_rearDisplayUserPresent "Indicates if a user is present in the rear seat based on seat occupancy and rear display usage";
CM_ SG_ 1056 UIS_rearDisplayState "Reports the rear display state.";
CM_ SG_ 1056 UIS_radioserveMemUsage "UIS ECU: radioserve mem usage";
CM_ SG_ 1056 UIS_radioserveCPUUsage "UIS ECU: radioserve CPU usage";
CM_ SG_ 1056 UIS_qtcarMemUsage "Signal reported by UIS ECU";
CM_ SG_ 1056 UIS_qtcarCPUUsage "Signal reported by UIS ECU";
CM_ SG_ 1056 UIS_psiMemSome "UIS ECU: psi mem some";
CM_ SG_ 1056 UIS_psiMemFull "UIS ECU: psi mem full";
CM_ SG_ 1056 UIS_psiIOSome "UIS ECU: psi IO some";
CM_ SG_ 1056 UIS_psiIOFull "UIS ECU: psi IO full";
CM_ SG_ 1056 UIS_psiCpuSome "UIS ECU: psi cpu some";
CM_ SG_ 1056 UIS_powerManagerState "UI power manager state signal; raw 18 = signal not available (SNA)";
CM_ SG_ 1056 UIS_polytopiax8664MemUsage "polytopiax8664's Resident Memory usage in MB";
CM_ SG_ 1056 UIS_polytopiax8664CPUUsage "polytopiax8664's CPU usage in CPU usage %";
CM_ SG_ 1056 UIS_odincefMemUsage "UIS ECU: odincef mem usage";
CM_ SG_ 1056 UIS_odincefCPUUsage "UIS ECU: odincef CPU usage";
CM_ SG_ 1056 UIS_odinStatusCmdResult "Signal reported by UIS ECU";
CM_ SG_ 1056 UIS_odinStatusCmdDurationMs "Signal reported by UIS ECU";
CM_ SG_ 1056 UIS_odinProcessState "Signal reported by UIS ECU";
CM_ SG_ 1056 UIS_odinOrchestratorStartCount "Signal reported by UIS ECU";
CM_ SG_ 1056 UIS_odinOrchestratorFailCount "Signal reported by UIS ECU";
CM_ SG_ 1056 UIS_odinNetworkStartCount "Signal reported by UIS ECU";
CM_ SG_ 1056 UIS_odinNetworkFailCount "Signal reported by UIS ECU";
CM_ SG_ 1056 UIS_odinMemUsage "Signal reported by UIS ECU";
CM_ SG_ 1056 UIS_odinListTasksCmdResult "Signal reported by UIS ECU";
CM_ SG_ 1056 UIS_odinListTasksCmdDurationMs "Signal reported by UIS ECU";
CM_ SG_ 1056 UIS_odinHrlUploadLimits "Signal reported by UIS ECU";
CM_ SG_ 1056 UIS_odinHrlLogUploadState "Signal reported by UIS ECU";
CM_ SG_ 1056 UIS_odinHermesConnectionState "Signal reported by UIS ECU";
CM_ SG_ 1056 UIS_odinGatewayConnectionState "Signal reported by UIS ECU";
CM_ SG_ 1056 UIS_odinFileSystemState "Signal reported by UIS ECU";
CM_ SG_ 1056 UIS_odinEcuLogUploadState "Signal reported by UIS ECU";
CM_ SG_ 1056 UIS_odinEcuLogForceTriggerUpload "Signal reported by UIS ECU";
CM_ SG_ 1056 UIS_odinCPUUsage "Signal reported by UIS ECU";
CM_ SG_ 1056 UIS_odinAuthFailCount "Signal reported by UIS ECU";
CM_ SG_ 1056 UIS_odinAuthCount "Signal reported by UIS ECU";
CM_ SG_ 1056 UIS_nvmeTemperature "UIS ECU: nvme temperature";
CM_ SG_ 1056 UIS_nvmePercentLifetimeUsed "UIS ECU: nvme percent lifetime used";
CM_ SG_ 1056 UIS_nvmeDataUnitsWritten100mb "UIS ECU: nvme data units written100mb";
CM_ SG_ 1056 UIS_numUncorrMemErrorsECC "UIS ECU: num uncorr mem errors ECC";
CM_ SG_ 1056 UIS_numCorrMemErrorsECC "UIS ECU: num corr mem errors ECC";
CM_ SG_ 1056 UIS_nuanceserverMemUsage "UIS ECU: nuanceserver mem usage";
CM_ SG_ 1056 UIS_nuanceserverCPUUsage "UIS ECU: nuanceserver CPU usage";
CM_ SG_ 1056 UIS_navAudioVolume "Navigation audio volume level";
CM_ SG_ 1056 UIS_muteNavVolume "Mute state of the navigation audio";
CM_ SG_ 1056 UIS_mounterdState "UIS ECU: mounterd state";
CM_ SG_ 1056 UIS_mounterdMountCountTotal "UIS ECU: mounterd mount count total";
CM_ SG_ 1056 UIS_mounterdFrontHubDisconnected "UIS ECU: mounterd front hub disconnected";
CM_ SG_ 1056 UIS_mounterdFrontHubConnected "UIS ECU: mounterd front hub connected";
CM_ SG_ 1056 UIS_mounterdFilesystemCountFat32 "UIS ECU: mounterd filesystem count fat32";
CM_ SG_ 1056 UIS_mounterdFilesystemCountExt4 "UIS ECU: mounterd filesystem count ext4";
CM_ SG_ 1056 UIS_mounterdFilesystemCountExt3 "UIS ECU: mounterd filesystem count ext3";
CM_ SG_ 1056 UIS_mounterdFilesystemCountExfat "UIS ECU: mounterd filesystem count exfat";
CM_ SG_ 1056 UIS_mounterdEncryptionCapacityGB "UIS ECU: mounterd encryption capacity GB";
CM_ SG_ 1056 UIS_mounterdDeviceCount "UIS ECU: mounterd device count";
CM_ SG_ 1056 UIS_mounterdDashcamCapacityGB "UIS ECU: mounterd dashcam capacity GB";
CM_ SG_ 1056 UIS_modemECallppAvail "Reports whether eCall++ is enabled and is running on Telematics Control Unit (TCU).";
CM_ SG_ 1056 UIS_modemBusyActive "Reports whether the modem busy logic is requested to be active on the modem application processor.";
CM_ SG_ 1056 UIS_mirrorGeofenceActive "Folding mirror geofence active status";
CM_ SG_ 1056 UIS_mediaserveMemUsage "UIS ECU: mediaserve mem usage";
CM_ SG_ 1056 UIS_mediaserveCPUUsage "UIS ECU: mediaserve CPU usage";
CM_ SG_ 1056 UIS_mediaPlaybackStatus "Media Current Playback Status";
CM_ SG_ 1056 UIS_mediaNeedAuthToken "Indicates whether the media system needs a new authentication token.";
CM_ SG_ 1056 UIS_mediaImageCacheSize "UIS ECU: media image cache size";
CM_ SG_ 1056 UIS_mediaImageCacheCost "UIS ECU: media image cache cost";
CM_ SG_ 1056 UIS_limex8664MemUsage "UIS ECU: limex8664 mem usage";
CM_ SG_ 1056 UIS_limex8664CPUUsage "UIS ECU: limex8664 CPU usage";
CM_ SG_ 1056 UIS_inSuperchargerGeofence "Vehicle inside Supercharger Geofence";
CM_ SG_ 1056 UIS_igpuTemperature "UIS ECU: igpu temperature";
CM_ SG_ 1056 UIS_homelinkState "State of Homelink sate machine";
CM_ SG_ 1056 UIS_hermesdynamicMemUsage "UIS ECU: hermesdynamic mem usage";
CM_ SG_ 1056 UIS_hermesdynamicCPUUsage "UIS ECU: hermesdynamic CPU usage";
CM_ SG_ 1056 UIS_hermesclientMemUsage "UIS ECU: hermesclient mem usage";
CM_ SG_ 1056 UIS_hermesclientCPUUsage "UIS ECU: hermesclient CPU usage";
CM_ SG_ 1056 UIS_headsetPairResult "Bluetooth headset pairing result";
CM_ SG_ 1056 UIS_headsetConnectionState "Bluetooth headset connection state";
CM_ SG_ 1056 UIS_gtwSocUartTxStatTimeouts "UIS ECU: gtw soc uart tx stat timeouts";
CM_ SG_ 1056 UIS_gtwSocUartTxStatPackets "UIS ECU: gtw soc uart tx stat packets";
CM_ SG_ 1056 UIS_gtwSocUartTxStatNacks "UIS ECU: gtw soc uart tx stat nacks";
CM_ SG_ 1056 UIS_gtwSocUartTxStatBadTooBig "UIS ECU: gtw soc uart tx stat bad too big";
CM_ SG_ 1056 UIS_gtwSocUartTxStatAnsMismatch "UIS ECU: gtw soc uart tx stat ans mismatch";
CM_ SG_ 1056 UIS_gtwSocUartRxStatValidPackets "UIS ECU: gtw soc uart rx stat valid packets";
CM_ SG_ 1056 UIS_gtwSocUartRxStatUnhandled "UIS ECU: gtw soc uart rx stat unhandled";
CM_ SG_ 1056 UIS_gtwSocUartRxStatMsgErr "UIS ECU: gtw soc uart rx stat msg err";
CM_ SG_ 1056 UIS_gtwSocUartRxStatHeartbeats "UIS ECU: gtw soc uart rx stat heartbeats";
CM_ SG_ 1056 UIS_gtwSocUartRxStatHandleErr "UIS ECU: gtw soc uart rx stat handle err";
CM_ SG_ 1056 UIS_gtwSocUartRxStatBadTooSmall "UIS ECU: gtw soc uart rx stat bad too small";
CM_ SG_ 1056 UIS_gtwSocUartRxStatBadTooBig "UIS ECU: gtw soc uart rx stat bad too big";
CM_ SG_ 1056 UIS_gtwSocUartRxStatBadChecksum "UIS ECU: gtw soc uart rx stat bad checksum";
CM_ SG_ 1056 UIS_gpsmanagerMemUsage "gpsManager's Resident Memory usage in MB";
CM_ SG_ 1056 UIS_gpsmanagerCPUUsage "gpsManager's CPU usage in CPU usage %";
CM_ SG_ 1056 UIS_godot_TIME_PROCESS "UIS ECU: godot TIME PROCESS";
CM_ SG_ 1056 UIS_godot_TIME_FPS "UIS ECU: godot TIME FPS";
CM_ SG_ 1056 UIS_godot_MEMORY_STATIC "UIS ECU: godot MEMORY STATIC";
CM_ SG_ 1056 UIS_godot_MEMORY_DYNAMIC "UIS ECU: godot MEMORY DYNAMIC";
CM_ SG_ 1056 UIS_godotMemUsage "UIS ECU: godot mem usage";
CM_ SG_ 1056 UIS_godotCPUUsage "UIS ECU: godot CPU usage";
CM_ SG_ 1056 UIS_firmwareReleaseScope "UIS ECU: firmware release scope";
CM_ SG_ 1056 UIS_featureSuperchargingEnabled "Reports the Supercharging enabled feature status.";
CM_ SG_ 1056 UIS_estimatedOccupancyCount "UIS ECU: estimated occupancy count";
CM_ SG_ 1056 UIS_embeddedGameState "UIS ECU: embedded game state";
CM_ SG_ 1056 UIS_embeddedGameName "UIS ECU: embedded game name";
CM_ SG_ 1056 UIS_dumTclipUploadState "UIS ECU: dum tclip upload state";
CM_ SG_ 1056 UIS_dumTclipUploadActive "UIS ECU: dum tclip upload active";
CM_ SG_ 1056 UIS_dumTclipTransferCount "UIS ECU: dum tclip transfer count";
CM_ SG_ 1056 UIS_dumTclipSuccessfulUploadCoun "UIS ECU: dum tclip successful upload count";
CM_ SG_ 1056 UIS_dumTclipClipCount "UIS ECU: dum tclip clip count";
CM_ SG_ 1056 UIS_dmRearTouchDeviceExists "Reports status of rear display power state.";
CM_ SG_ 1056 UIS_dmRearPowerState "Logs rear display power state status";
CM_ SG_ 1056 UIS_dmRearLinkCheckOk "Logs whether rear display-hardware-init was successful";
CM_ SG_ 1056 UIS_dmRearEnabled "Rear display is enabled";
CM_ SG_ 1056 UIS_dmRearConnected "Rear display is connected";
CM_ SG_ 1056 UIS_dmRearBacklightPowerLevel "UIS ECU: dm rear backlight power level";
CM_ SG_ 1056 UIS_dmRearBacklightNits "UIS ECU: dm rear backlight nits";
CM_ SG_ 1056 UIS_dmRearBacklightFault "UIS ECU: dm rear backlight fault";
CM_ SG_ 1056 UIS_dmRearBacklightDutyCycle "Logs rear backlight duty cycle status";
CM_ SG_ 1056 UIS_dmRearBacklightDevExists "Logs whether rear backlight device exists and was successfully detected";
CM_ SG_ 1056 UIS_dmRearAsilStatusMsb "UIS ECU: dm rear asil status msb";
CM_ SG_ 1056 UIS_dmRearAsilStatusLsb "UIS ECU: dm rear asil status lsb";
CM_ SG_ 1056 UIS_dmIcuTouchIrqCount "UIS ECU: dm icu touch irq count";
CM_ SG_ 1056 UIS_dmIcuPowerState "Logs cluster display power state status";
CM_ SG_ 1056 UIS_dmIcuLinkCheckOk "Logs whether cluster display-hardware-init was successful";
CM_ SG_ 1056 UIS_dmIcuEnabled "Cluster display is enabled";
CM_ SG_ 1056 UIS_dmIcuConnected "Cluster display is connected";
CM_ SG_ 1056 UIS_dmIcuBacklightPowerLevel "UIS ECU: dm icu backlight power level";
CM_ SG_ 1056 UIS_dmIcuBacklightNits "UIS ECU: dm icu backlight nits";
CM_ SG_ 1056 UIS_dmIcuBacklightFault "UIS ECU: dm icu backlight fault";
CM_ SG_ 1056 UIS_dmIcuBacklightDutyCycle "Logs cluster backlight duty cycle status";
CM_ SG_ 1056 UIS_dmIcuBacklightDevExists "Logs whether cluster backlight device exists and was successfully detected";
CM_ SG_ 1056 UIS_dmIcuAsilShortFlag "UIS ECU: dm icu asil short flag";
CM_ SG_ 1056 UIS_dmIcuAsilResumeFlag "UIS ECU: dm icu asil resume flag";
CM_ SG_ 1056 UIS_dmIcuAsilOpenFlag "UIS ECU: dm icu asil open flag";
CM_ SG_ 1056 UIS_dmIcuAsilFirmwareStatus "UIS ECU: dm icu asil firmware status";
CM_ SG_ 1056 UIS_dmGatewayLinkWedged "Indicates whether the center display gateway link is stuck.";
CM_ SG_ 1056 UIS_dmCenterTouchIrqCount "UIS ECU: dm center touch irq count";
CM_ SG_ 1056 UIS_dmCenterTouchDeviceExists "Detects whether the center display touch input device is present.";
CM_ SG_ 1056 UIS_dmCenterSOsdVideoCrcData "UIS ECU: dm center s osd video crc data";
CM_ SG_ 1056 UIS_dmCenterSOsdExactCrcCheck "UIS ECU: dm center s osd exact crc check";
CM_ SG_ 1056 UIS_dmCenterPowerState "Logs center display power state status";
CM_ SG_ 1056 UIS_dmCenterOsdDisplayedState "Reports the center display On-Screen Display (OSD) shown state.";
CM_ SG_ 1056 UIS_dmCenterOsdDayNightState "UIS ECU: dm center osd day night state";
CM_ SG_ 1056 UIS_dmCenterModeSettingStatus "UIS ECU: dm center mode setting status";
CM_ SG_ 1056 UIS_dmCenterMOsdVideoCrcData "UIS ECU: dm center m osd video crc data";
CM_ SG_ 1056 UIS_dmCenterMOsdExactCrcCheck "UIS ECU: dm center m osd exact crc check";
CM_ SG_ 1056 UIS_dmCenterLinkCheckOk "Logs whether center display-hardware-init was successful";
CM_ SG_ 1056 UIS_dmCenterEnabled "Center display is enabled";
CM_ SG_ 1056 UIS_dmCenterConnected "Center display is connected";
CM_ SG_ 1056 UIS_dmCenterBacklightPowerLevel "Logs backlight power level for center display";
CM_ SG_ 1056 UIS_dmCenterBacklightNits "UIS ECU: dm center backlight nits";
CM_ SG_ 1056 UIS_dmCenterBacklightFault "UIS ECU: dm center backlight fault";
CM_ SG_ 1056 UIS_dmCenterBacklightDutyCycle "Logs center backlight duty cycle status";
CM_ SG_ 1056 UIS_dmCenterBacklightDevExists "Logs whether center backlight device exists and was successfully detected";
CM_ SG_ 1056 UIS_dmCenterAsilShortFlag "UIS ECU: dm center asil short flag";
CM_ SG_ 1056 UIS_dmCenterAsilResumeFlag "UIS ECU: dm center asil resume flag";
CM_ SG_ 1056 UIS_dmCenterAsilOpenFlag "UIS ECU: dm center asil open flag";
CM_ SG_ 1056 UIS_dmCenterAsilFirmwareStatus "UIS ECU: dm center asil firmware status";
CM_ SG_ 1056 UIS_dgpuTemperature "Current temperature reported for dgpu";
CM_ SG_ 1056 UIS_developerMode "UIS ECU: developer mode";
CM_ SG_ 1056 UIS_dashcamviewerMemUsage "dashcamViewer's Resident Memory usage in MB";
CM_ SG_ 1056 UIS_dashcamviewerCPUUsage "dashcamViewer's CPU usage in CPU usage %";
CM_ SG_ 1056 UIS_dashcamTransferTimeMs "UIS ECU: dashcam transfer time ms";
CM_ SG_ 1056 UIS_dashcamTransferSizeMB "UIS ECU: dashcam transfer size MB";
CM_ SG_ 1056 UIS_dashcamTransferRateMBps "UIS ECU: dashcam transfer rate m bps";
CM_ SG_ 1056 UIS_dashcamTransferFileCount "UIS ECU: dashcam transfer file count";
CM_ SG_ 1056 UIS_dashcamTransferCount "UIS ECU: dashcam transfer count";
CM_ SG_ 1056 UIS_dashcamStorageState "Internal state of the dashcam storage";
CM_ SG_ 1056 UIS_dashcamStorageSentryMB "Dashcam USB storage used by Sentry Clips in MB";
CM_ SG_ 1056 UIS_dashcamStorageSavedMB "Dashcam USB storage used by Saved Clips in MB";
CM_ SG_ 1056 UIS_dashcamStorageRecentMB "Dashcam USB storage used by Recent Clips in MB";
CM_ SG_ 1056 UIS_dashcamStorageAvailableMB "Dashcam USB storage that is Available in MB";
CM_ SG_ 1056 UIS_dashcamState "Internal state for the dashcam state machine";
CM_ SG_ 1056 UIS_dashcamSavedToSentryCount "UIS ECU: dashcam saved to sentry count";
CM_ SG_ 1056 UIS_dashcamSavedToSavedCount "UIS ECU: dashcam saved to saved count";
CM_ SG_ 1056 UIS_dashcamSavedToOnboardCount "UIS ECU: dashcam saved to onboard count";
CM_ SG_ 1056 UIS_dashcamOnboardTransferCount "UIS ECU: dashcam onboard transfer count";
CM_ SG_ 1056 UIS_dashcamOnboardSavePressCount "UIS ECU: dashcam onboard save press count";
CM_ SG_ 1056 UIS_dashcamOnboardMB "UIS ECU: dashcam onboard MB";
CM_ SG_ 1056 UIS_dashcamOnboardAvailableMB "UIS ECU: dashcam onboard available MB";
CM_ SG_ 1056 UIS_cpuTemperature "Current temperature reported for cpu";
CM_ SG_ 1056 UIS_compositorRenderMinRenderTim "UIS ECU: compositor render min render time";
CM_ SG_ 1056 UIS_compositorRenderMinFrameTime "UIS ECU: compositor render min frame time";
CM_ SG_ 1056 UIS_compositorRenderMaxRenderTim "UIS ECU: compositor render max render time";
CM_ SG_ 1056 UIS_compositorRenderMaxFrameTime "UIS ECU: compositor render max frame time";
CM_ SG_ 1056 UIS_compositorRenderGpuPercentag "UIS ECU: compositor render gpu percentage";
CM_ SG_ 1056 UIS_compositorRenderFrameRate "UIS ECU: compositor render frame rate";
CM_ SG_ 1056 UIS_compositorRenderFrameCount "UIS ECU: compositor render frame count";
CM_ SG_ 1056 UIS_compositorRenderAvgRenderTim "UIS ECU: compositor render avg render time";
CM_ SG_ 1056 UIS_compositorFrameMonitorState "UIS ECU: compositor frame monitor state";
CM_ SG_ 1056 UIS_cobaltlinuxMemUsage "UIS ECU: cobaltlinux mem usage";
CM_ SG_ 1056 UIS_cobaltlinuxCPUUsage "UIS ECU: cobaltlinux CPU usage";
CM_ SG_ 1056 UIS_clusterMemUsage "cluster's Resident Memory usage in MB";
CM_ SG_ 1056 UIS_clusterMeanFPS "UIS ECU: cluster mean FPS";
CM_ SG_ 1056 UIS_clusterMaxFrametime "UIS ECU: cluster max frametime";
CM_ SG_ 1056 UIS_clusterFramesOver200Ms "UIS ECU: cluster frames over200 ms";
CM_ SG_ 1056 UIS_clusterFramesOver100Ms "UIS ECU: cluster frames over100 ms";
CM_ SG_ 1056 UIS_clusterDisplayState "Reports the instrument cluster display state.";
CM_ SG_ 1056 UIS_clusterCPUUsage "cluster's CPU usage in CPU usage %";
CM_ SG_ 1056 UIS_chromiumadapterMemUsage "UIS ECU: chromiumadapter mem usage";
CM_ SG_ 1056 UIS_chromiumadapterCPUUsage "UIS ECU: chromiumadapter CPU usage";
CM_ SG_ 1056 UIS_chargeOnSolarNoChargeReason "Reason car is not charging on solar";
CM_ SG_ 1056 UIS_ceruleanx8664MemUsage "UIS ECU: ceruleanx8664 mem usage";
CM_ SG_ 1056 UIS_ceruleanx8664CPUUsage "UIS ECU: ceruleanx8664 CPU usage";
CM_ SG_ 1056 UIS_centerDisplayState "Reports the center display state.";
CM_ SG_ 1056 UIS_centerDisplayEvent "Reports the events that cause center display state transitions.";
CM_ SG_ 1056 UIS_centerDispAsilB_msb "UIS ECU: center disp asil b msb";
CM_ SG_ 1056 UIS_centerDispAsilB_lsb "UIS ECU: center disp asil b lsb";
CM_ SG_ 1056 UIS_centerDispAsilA_msb "UIS ECU: center disp asil a msb";
CM_ SG_ 1056 UIS_centerDispAsilA_lsb "UIS ECU: center disp asil a lsb";
CM_ SG_ 1056 UIS_cellularLinkManagerState "CellLink Manager state";
CM_ SG_ 1056 UIS_carAssistState "Car Assist State";
CM_ SG_ 1056 UIS_carAssistSessionCount "Car Assist Session Count";
CM_ SG_ 1056 UIS_carAssistErrorCode "Car Assist Error Code";
CM_ SG_ 1056 UIS_cameraRRepeaterStreamMissing "Signal representing if left repeater camera stream is active within videod";
CM_ SG_ 1056 UIS_cameraRRepeaterStream "UIS ECU: camera r repeater stream";
CM_ SG_ 1056 UIS_cameraRRepeaterPopup "Right repeater camera popup state";
CM_ SG_ 1056 UIS_cameraRRepeaterPipeline "Right repeater videod pipeline state";
CM_ SG_ 1056 UIS_cameraRRepeaterMaxFrametime "UIS ECU: camera r repeater max frametime";
CM_ SG_ 1056 UIS_cameraRRepeaterLateFrames "UIS ECU: camera r repeater late frames";
CM_ SG_ 1056 UIS_cameraRRepeaterFramerate "UIS ECU: camera r repeater framerate";
CM_ SG_ 1056 UIS_cameraLRepeaterStreamMissing "Signal representing if left repeater camera stream is active within videod";
CM_ SG_ 1056 UIS_cameraLRepeaterStream "UIS ECU: camera l repeater stream";
CM_ SG_ 1056 UIS_cameraLRepeaterPopup "Left repeater camera popup state";
CM_ SG_ 1056 UIS_cameraLRepeaterPipeline "Left repeater videod pipeline state";
CM_ SG_ 1056 UIS_cameraLRepeaterMaxFrametime "UIS ECU: camera l repeater max frametime";
CM_ SG_ 1056 UIS_cameraLRepeaterLateFrames "UIS ECU: camera l repeater late frames";
CM_ SG_ 1056 UIS_cameraLRepeaterFramerate "UIS ECU: camera l repeater framerate";
CM_ SG_ 1056 UIS_cameraFrontStreamMissing "UIS ECU: camera front stream missing";
CM_ SG_ 1056 UIS_cameraFrontStream "UIS ECU: camera front stream";
CM_ SG_ 1056 UIS_cameraFrontPopup "UIS ECU: camera front popup";
CM_ SG_ 1056 UIS_cameraFrontPipeline "UIS ECU: camera front pipeline";
CM_ SG_ 1056 UIS_cameraBackupStreamQuality "UIS ECU: camera backup stream quality";
CM_ SG_ 1056 UIS_cameraBackupStreamMissing "Signal representing if backup camera stream is active within videod";
CM_ SG_ 1056 UIS_cameraBackupStream "UIS ECU: camera backup stream";
CM_ SG_ 1056 UIS_cameraBackupPopup "Reports the backup camera popup state.";
CM_ SG_ 1056 UIS_cameraBackupPipeline "Reports the backup camera video pipeline state.";
CM_ SG_ 1056 UIS_cameraBackupMaxFrametime "UIS ECU: camera backup max frametime";
CM_ SG_ 1056 UIS_cameraBackupLateFrames "UIS ECU: camera backup late frames";
CM_ SG_ 1056 UIS_cameraBackupFramerate "Reports the backup camera framerate.";
CM_ SG_ 1056 UIS_camBackupDecodeMinFrametime "UIS ECU: cam backup decode min frametime";
CM_ SG_ 1056 UIS_camBackupDecodeMaxFrametime "UIS ECU: cam backup decode max frametime";
CM_ SG_ 1056 UIS_camBackupDecodeFramecount "UIS ECU: cam backup decode framecount";
CM_ SG_ 1056 UIS_camBackupDecodeAvgFrametime "UIS ECU: cam backup decode avg frametime";
CM_ SG_ 1056 UIS_bootCount "UIS ECU: boot count";
CM_ SG_ 1056 UIS_boardTemperature "Current temperature reported for board";
CM_ SG_ 1056 UIS_bluetoothStackState "Bluetooth stack state";
CM_ SG_ 1056 UIS_bluetoothStackRearState "Bluetooth rear stack state";
CM_ SG_ 1056 UIS_bluetoothPairResult "Bluetooth pairing result";
CM_ SG_ 1056 UIS_bluetoothMemUsage "Reports the Bluetooth process resident memory usage in megabytes.";
CM_ SG_ 1056 UIS_bluetoothConnectionState "Reports the Bluetooth connection state.";
CM_ SG_ 1056 UIS_bluetoothCPUUsage "Reports the Bluetooth process Central Processing Unit (CPU) usage percentage.";
CM_ SG_ 1056 UIS_bluetoothAutoConnectionState "Reports the Bluetooth auto-connection state.";
CM_ SG_ 1056 UIS_bifrostOdinEngineUp "Signal reported by UIS ECU";
CM_ SG_ 1056 UIS_bifrostOdinEngineRequests "Signal reported by UIS ECU";
CM_ SG_ 1056 UIS_bifrostMemUsage "UIS ECU: bifrost mem usage";
CM_ SG_ 1056 UIS_bifrostCPUUsage "UIS ECU: bifrost CPU usage";
CM_ SG_ 1056 UIS_backlightUserRequest "Reports the Graphical User Interface (GUI) backlight user request value.";
CM_ SG_ 1056 UIS_audioVolumeLevel "User facing volume level";
CM_ SG_ 1056 UIS_audioType "Shows which audio amplifier type is currently configured";
CM_ SG_ 1056 UIS_audioState "Shows the state of the audio system";
CM_ SG_ 1056 UIS_audioSource "Shows which internal audio source is currently active";
CM_ SG_ 1056 UIS_audioPWSGain "Reports the pedestrian warning system volume in decibels.";
CM_ SG_ 1056 UIS_audioMediaPlaying "Shows which media source is currently being played";
CM_ SG_ 1056 UIS_audioMediaBrowsing "Shows which media source is currently being viewed";
CM_ SG_ 1056 UIS_audioA2BRediscoveryCount "Shows the count of a2b rediscoveries that have occurred";
CM_ SG_ 1056 UIS_amdSocPkgPower "UIS ECU: amd soc pkg power";
CM_ SG_ 1056 UIS_activeAppView "Shows the currently displayed app";
CM_ BO_ 1154 "Touchscreen user interface computer message: iso tp pipe remote VCSEC";
CM_ SG_ 1154 UI_IsoTpRemoteVCSEC0 "Touchscreen user interface computer: iso tp remote VCSEC0";
CM_ SG_ 1154 UI_IsoTpRemoteVCSEC1 "Touchscreen user interface computer: iso tp remote VCSEC1";
CM_ SG_ 1154 UI_IsoTpRemoteVCSEC2 "Touchscreen user interface computer: iso tp remote VCSEC2";
CM_ SG_ 1154 UI_IsoTpRemoteVCSEC3 "Touchscreen user interface computer: iso tp remote VCSEC3";
CM_ SG_ 1154 UI_IsoTpRemoteVCSEC4 "Touchscreen user interface computer: iso tp remote VCSEC4";
CM_ SG_ 1154 UI_IsoTpRemoteVCSEC5 "Touchscreen user interface computer: iso tp remote VCSEC5";
CM_ SG_ 1154 UI_IsoTpRemoteVCSEC6 "Touchscreen user interface computer: iso tp remote VCSEC6";
CM_ SG_ 1154 UI_IsoTpRemoteVCSEC7 "Touchscreen user interface computer: iso tp remote VCSEC7";
CM_ BO_ 1153 "Touchscreen user interface computer message: iso tp UDP pipe VCSEC";
CM_ SG_ 1153 UI_IsoTpUDPPipeVCSEC0 "Touchscreen user interface computer: iso tp UDP pipe VCSEC0";
CM_ SG_ 1153 UI_IsoTpUDPPipeVCSEC1 "Touchscreen user interface computer: iso tp UDP pipe VCSEC1";
CM_ SG_ 1153 UI_IsoTpUDPPipeVCSEC2 "Touchscreen user interface computer: iso tp UDP pipe VCSEC2";
CM_ SG_ 1153 UI_IsoTpUDPPipeVCSEC3 "Touchscreen user interface computer: iso tp UDP pipe VCSEC3";
CM_ SG_ 1153 UI_IsoTpUDPPipeVCSEC4 "Touchscreen user interface computer: iso tp UDP pipe VCSEC4";
CM_ SG_ 1153 UI_IsoTpUDPPipeVCSEC5 "Touchscreen user interface computer: iso tp UDP pipe VCSEC5";
CM_ SG_ 1153 UI_IsoTpUDPPipeVCSEC6 "Touchscreen user interface computer: iso tp UDP pipe VCSEC6";
CM_ SG_ 1153 UI_IsoTpUDPPipeVCSEC7 "Touchscreen user interface computer: iso tp UDP pipe VCSEC7";
CM_ BO_ 979 "Touchscreen user interface computer message: airbag cutoff status";
CM_ SG_ 979 UI_airbagCutoffSwState "Reports the front passenger airbag cutoff switch request; raw 2 = signal not available (SNA)";
CM_ SG_ 979 UI_warningIndicatorStatus "Touchscreen user interface computer: warning indicator status; raw 3 = signal not available (SNA)";
CM_ BO_ 1523 "Touchscreen user interface computer message: alert log";
CM_ SG_ 1523 UI_alertID "Touchscreen user interface computer: alert ID";
CM_ SG_ 1523 UI_alertState "Touchscreen user interface computer: alert state";
CM_ SG_ 1523 UI_a006_remoteServiceAlertCode "Touchscreen user interface computer: a006 remote service alert code";
CM_ SG_ 1523 UI_a034_BackupCamera "Touchscreen user interface computer: a034 backup camera";
CM_ SG_ 1523 UI_a034_Tuner "Touchscreen user interface computer: a034 tuner";
CM_ SG_ 1523 UI_a034_Bluetooth "Touchscreen user interface computer: a034 bluetooth";
CM_ SG_ 1523 UI_a034_WiFi "Touchscreen user interface computer: a034 wi fi";
CM_ SG_ 1523 UI_a034_Cellular "Touchscreen user interface computer: a034 cellular";
CM_ SG_ 1523 UI_a034_TouchScreen "Touchscreen user interface computer: a034 touch screen";
CM_ SG_ 1523 UI_a034_Display "Touchscreen user interface computer: a034 display";
CM_ SG_ 1523 UI_a034_Audio "Touchscreen user interface computer: a034 audio";
CM_ SG_ 1523 UI_a034_FatalWakeup "Touchscreen user interface computer: a034 fatal wakeup";
CM_ SG_ 1523 UI_a034_UnknownWakeupError "Touchscreen user interface computer: a034 unknown wakeup error";
CM_ SG_ 1523 UI_a036_audioWatchdogReason "Touchscreen user interface computer: a036 audio watchdog reason";
CM_ SG_ 1523 UI_a045_ManualECallDisabled "Touchscreen user interface computer: a045 manual e call disabled";
CM_ SG_ 1523 UI_a045_ManualECallButtonDisconn "Touchscreen user interface computer: a045 manual e call button disconnected";
CM_ SG_ 1523 UI_a045_CellAntenna "Touchscreen user interface computer: a045 cell antenna";
CM_ SG_ 1523 UI_a045_GPSAntenna "Touchscreen user interface computer: a045 GPS antenna";
CM_ SG_ 1523 UI_a045_ECallSpeaker "Touchscreen user interface computer: a045 e call speaker";
CM_ SG_ 1523 UI_a045_ECallMic "Touchscreen user interface computer: a045 e call mic";
CM_ SG_ 1523 UI_a045_SIMTest "Touchscreen user interface computer: a045 SIM test";
CM_ SG_ 1523 UI_a045_ENSTest "Touchscreen user interface computer: a045 ENS test";
CM_ SG_ 1523 UI_a045_CellularTest "Touchscreen user interface computer: a045 cellular test";
CM_ SG_ 1523 UI_a045_ModemFirmwareTest "Touchscreen user interface computer: a045 modem firmware test";
CM_ SG_ 1523 UI_a052_kernelPanicSignature "Touchscreen user interface computer: a052 kernel panic signature";
CM_ SG_ 1523 UI_a066_ProcessId "Touchscreen user interface computer: a066 process id";
CM_ SG_ 1523 UI_a066_RingBlitter "Touchscreen user interface computer: a066 ring blitter";
CM_ SG_ 1523 UI_a066_RingBSD "Touchscreen user interface computer: a066 ring BSD";
CM_ SG_ 1523 UI_a066_RingRender "Touchscreen user interface computer: a066 ring render";
CM_ SG_ 1523 UI_a066_RingVideoEnhancement "Touchscreen user interface computer: a066 ring video enhancement";
CM_ SG_ 1523 UI_a066_EnginesHung "Touchscreen user interface computer: a066 engines hung";
CM_ SG_ 1523 UI_a066_EnginesWedged "Touchscreen user interface computer: a066 engines wedged";
CM_ SG_ 1523 UI_a066_RecoveryFailed "Touchscreen user interface computer: a066 recovery failed";
CM_ SG_ 1523 UI_a066_FlipDoneTimedOut "Touchscreen user interface computer: a066 flip done timed out";
CM_ SG_ 1523 UI_a066_TimedoutSoftRecovered "Touchscreen user interface computer: a066 timedout soft recovered";
CM_ SG_ 1523 UI_a087_BmpResetType "Touchscreen user interface computer: a087 bmp reset type";
CM_ SG_ 1523 UI_a096_PipelineId "Touchscreen user interface computer: a096 pipeline id";
CM_ SG_ 1523 UI_a096_UdpTimeout "Touchscreen user interface computer: a096 udp timeout";
CM_ SG_ 1523 UI_a096_PipelineWarning "Touchscreen user interface computer: a096 pipeline warning";
CM_ SG_ 1523 UI_a096_PipelineError "Touchscreen user interface computer: a096 pipeline error";
CM_ SG_ 1523 UI_a096_UnexpectedExit "Touchscreen user interface computer: a096 unexpected exit";
CM_ SG_ 1523 UI_a096_PipelineOverrun "Touchscreen user interface computer: a096 pipeline overrun";
CM_ SG_ 1523 UI_a096_MissingXWindow "Touchscreen user interface computer: a096 missing x window";
CM_ SG_ 1523 UI_a099_emmcStatusRegister "Touchscreen user interface computer: a099 emmc status register";
CM_ SG_ 1523 UI_a100_emmcFTLCounter "Touchscreen user interface computer: a100 emmc FTL counter";
CM_ SG_ 1523 UI_a131_DisplayPortFailureType "Touchscreen user interface computer: a131 display port failure type";
CM_ SG_ 1523 UI_a147_whichASIL "Touchscreen user interface computer: a147 which ASIL";
CM_ SG_ 1523 UI_a147_errorCode "Touchscreen user interface computer: a147 error code";
CM_ SG_ 1523 UI_a148_sleepType "Touchscreen user interface computer: a148 sleep type";
CM_ SG_ 1523 UI_a148_lastFailedDev "Touchscreen user interface computer: a148 last failed dev";
CM_ SG_ 1523 UI_a148_lastFailedPmSuspendDev "Touchscreen user interface computer: a148 last failed pm suspend dev";
CM_ SG_ 1523 UI_a149_displayType "Touchscreen user interface computer: a149 display type";
CM_ SG_ 1523 UI_a149_errorCode "Touchscreen user interface computer: a149 error code";
CM_ SG_ 1523 UI_a153_processName "Touchscreen user interface computer: a153 process name";
CM_ SG_ 1523 UI_a153_restartReason "Touchscreen user interface computer: a153 restart reason";
CM_ SG_ 1523 UI_a158_UsbDeviceMountErrorCode "Touchscreen user interface computer: a158 usb device mount error code";
CM_ SG_ 1523 UI_a160_WatchdogStarving "Touchscreen user interface computer: a160 watchdog starving";
CM_ SG_ 1523 UI_a160_MemoryPressureCritical "Touchscreen user interface computer: a160 memory pressure critical";
CM_ SG_ 1523 UI_a160_MemoryUsageCritical "Touchscreen user interface computer: a160 memory usage critical";
CM_ SG_ 1523 UI_a160_SlabUsageCritical "Touchscreen user interface computer: a160 slab usage critical";
CM_ SG_ 1523 UI_a165_fsCorruptedDevice "Touchscreen user interface computer: a165 fs corrupted device";
CM_ SG_ 1523 UI_a166_fsErrorDevice "Touchscreen user interface computer: a166 fs error device";
CM_ SG_ 1523 UI_a167_processId "Touchscreen user interface computer: a167 process id";
CM_ SG_ 1523 UI_a173_errorCode "Touchscreen user interface computer: a173 error code";
CM_ SG_ 1523 UI_a173_hookIndex "Touchscreen user interface computer: a173 hook index";
CM_ SG_ 1523 UI_a173_lastFailedPmSuspendDev "Touchscreen user interface computer: a173 last failed pm suspend dev";
CM_ SG_ 1523 UI_a176_PrimaryAntenna "Touchscreen user interface computer: a176 primary antenna";
CM_ SG_ 1523 UI_a176_SecondaryAntenna "Touchscreen user interface computer: a176 secondary antenna";
CM_ SG_ 1523 UI_a176_TertiaryAntenna "Touchscreen user interface computer: a176 tertiary antenna";
CM_ SG_ 1523 UI_a177_errorCode "Touchscreen user interface computer: a177 error code";
CM_ SG_ 1523 UI_a178_irqNumber "Touchscreen user interface computer: a178 irq number";
CM_ SG_ 1523 UI_a178_irqSourceId "Touchscreen user interface computer: a178 irq source id";
CM_ SG_ 1523 UI_a192_AudioRebootState "Touchscreen user interface computer: a192 audio reboot state";
CM_ SG_ 1523 UI_a214_errorCode "Touchscreen user interface computer: a214 error code";
CM_ SG_ 1523 UI_a214_lastFailedDev "Touchscreen user interface computer: a214 last failed dev";
CM_ SG_ 1523 UI_a214_lastFailedPmSuspendDev "Touchscreen user interface computer: a214 last failed pm suspend dev";
CM_ SG_ 1523 UI_a216_circuitProblem "Touchscreen user interface computer: a216 circuit problem";
CM_ SG_ 1523 UI_a216_circuitNode "Touchscreen user interface computer: a216 circuit node";
CM_ SG_ 1523 UI_a217_cgroupName "Touchscreen user interface computer: a217 cgroup name";
CM_ SG_ 1523 UI_a220_errorCode "Touchscreen user interface computer: a220 error code";
CM_ SG_ 1523 UI_a222_errorCode "Touchscreen user interface computer: a222 error code";
CM_ SG_ 1523 UI_a223_database "Touchscreen user interface computer: a223 database";
CM_ SG_ 1523 UI_a226_count "Touchscreen user interface computer: a226 count";
CM_ SG_ 1523 UI_a229_errorCode "Touchscreen user interface computer: a229 error code";
CM_ SG_ 1523 UI_a231_sleepType "Touchscreen user interface computer: a231 sleep type";
CM_ SG_ 1523 UI_a232_processExited "Touchscreen user interface computer: a232 process exited";
CM_ SG_ 1523 UI_a232_processSignal "Touchscreen user interface computer: a232 process signal";
CM_ SG_ 1523 UI_a240_ethErrorType "Touchscreen user interface computer: a240 eth error type";
CM_ SG_ 1523 UI_a241_errorCode "Touchscreen user interface computer: a241 error code";
CM_ BO_ 291 "Touchscreen user interface computer message: alert matrix1";
CM_ SG_ 291 UI_a001_DriverDoorOpen "Touchscreen user interface computer: a001 driver door open";
CM_ SG_ 291 UI_a002_DoorOpen "Touchscreen user interface computer: a002 door open";
CM_ SG_ 291 UI_a003_TrunkOpen "Touchscreen user interface computer: a003 trunk open";
CM_ SG_ 291 UI_a004_FrunkOpen "Touchscreen user interface computer: a004 frunk open";
CM_ SG_ 291 UI_a005_HeadlightsOnDoorOpen "Touchscreen user interface computer: a005 headlights on door open";
CM_ SG_ 291 UI_a006_RemoteServiceAlert "Touchscreen user interface computer: a006 remote service alert";
CM_ SG_ 291 UI_a007_SoftPackConfigMismatch "Touchscreen user interface computer: a007 soft pack config mismatch";
CM_ SG_ 291 UI_a008_TouchScreenError "Touchscreen user interface computer: a008 touch screen error";
CM_ SG_ 291 UI_a009_SquashfsError "Touchscreen user interface computer: a009 squashfs error";
CM_ SG_ 291 UI_a010_MapsMissing "Touchscreen user interface computer: a010 maps missing";
CM_ SG_ 291 UI_a011_IncorrectMap "Touchscreen user interface computer: a011 incorrect map";
CM_ SG_ 291 UI_a012_NotOnPrivateProperty "Touchscreen user interface computer: a012 not on private property";
CM_ SG_ 291 UI_a013_TPMSHardWarning "Touchscreen user interface computer: a013 TPMS hard warning";
CM_ SG_ 291 UI_a014_TPMSSoftWarning "Touchscreen user interface computer: a014 TPMS soft warning";
CM_ SG_ 291 UI_a015_TPMSOverPressureWarning "Touchscreen user interface computer: a015 TPMS over pressure warning";
CM_ SG_ 291 UI_a016_TPMSTemperatureWarning "Touchscreen user interface computer: a016 TPMS temperature warning";
CM_ SG_ 291 UI_a017_TPMSSystemFault "Touchscreen user interface computer: a017 TPMS system fault";
CM_ SG_ 291 UI_a018_SlipStartOn "Touchscreen user interface computer: a018 slip start on";
CM_ SG_ 291 UI_a019_ParkBrakeFault "Touchscreen user interface computer: a019 park brake fault";
CM_ SG_ 291 UI_a020_SteeringReduced "Touchscreen user interface computer: a020 steering reduced";
CM_ SG_ 291 UI_a021_RearSeatbeltUnbuckled "Touchscreen user interface computer: a021 rear seatbelt unbuckled";
CM_ SG_ 291 UI_a022_ApeFusesEtc "Touchscreen user interface computer: a022 ape fuses etc";
CM_ SG_ 291 UI_a023_CellInternetCheckFailed "Touchscreen user interface computer: a023 cell internet check failed";
CM_ SG_ 291 UI_a024_WifiInternetCheckFailed "Touchscreen user interface computer: a024 wifi internet check failed";
CM_ SG_ 291 UI_a026_ModemResetLoopDetected "Touchscreen user interface computer: a026 modem reset loop detected";
CM_ SG_ 291 UI_a027_AutoSteerMIA "Touchscreen user interface computer: a027 auto steer MIA";
CM_ SG_ 291 UI_a028_FrontTrunkPopupClosed "Touchscreen user interface computer: a028 front trunk popup closed";
CM_ SG_ 291 UI_a029_ModemMIA "Touchscreen user interface computer: a029 modem MIA";
CM_ SG_ 291 UI_a030_ModemVMCrash "Touchscreen user interface computer: a030 modem VM crash";
CM_ SG_ 291 UI_a031_BrakeFluidLow "Touchscreen user interface computer: a031 brake fluid low";
CM_ SG_ 291 UI_a032_CellModemRecoveryResets "Touchscreen user interface computer: a032 cell modem recovery resets";
CM_ SG_ 291 UI_a033_ApTrialExpired "Touchscreen user interface computer: a033 ap trial expired";
CM_ SG_ 291 UI_a034_WakeupProblem "Touchscreen user interface computer: a034 wakeup problem";
CM_ SG_ 291 UI_a035_FrunkOpenChime "Touchscreen user interface computer: a035 frunk open chime";
CM_ SG_ 291 UI_a036_AudioWatchdog "Touchscreen user interface computer: a036 audio watchdog";
CM_ SG_ 291 UI_a037_AudioWatchdogXrunStormEr "Touchscreen user interface computer: a037 audio watchdog xrun storm error";
CM_ SG_ 291 UI_a038_AudioWatchdogA2bI2cLocku "Touchscreen user interface computer: a038 audio watchdog a2b i2c lockup error";
CM_ SG_ 291 UI_a039_AudioA2bNeedRediscovery "Touchscreen user interface computer: a039 audio a2b need rediscovery";
CM_ SG_ 291 UI_a040_HomelinkTransmit "Touchscreen user interface computer: a040 homelink transmit";
CM_ SG_ 291 UI_a041_AudioDmesgXrun "Touchscreen user interface computer: a041 audio dmesg xrun";
CM_ SG_ 291 UI_a042_AudioDmesgRtThrottling "Touchscreen user interface computer: a042 audio dmesg rt throttling";
CM_ SG_ 291 UI_a043_InvalidMapDataOverride "Touchscreen user interface computer: a043 invalid map data override";
CM_ SG_ 291 UI_a044_AudioDmesgDspException "Touchscreen user interface computer: a044 audio dmesg dsp exception";
CM_ SG_ 291 UI_a045_ECallSystemCheckFailed "Touchscreen user interface computer: a045 e call system check failed";
CM_ SG_ 291 UI_a046_BackupCameraStreamError "Touchscreen user interface computer: a046 backup camera stream error";
CM_ SG_ 291 UI_a047_CellRoamingDisallowed "Touchscreen user interface computer: a047 cell roaming disallowed";
CM_ SG_ 291 UI_a048_AudioPremiumAmpCheckFail "Touchscreen user interface computer: a048 audio premium amp check failed";
CM_ SG_ 291 UI_a049_BrakeShiftRequired "Touchscreen user interface computer: a049 brake shift required";
CM_ SG_ 291 UI_a050_BackupCameraIPUTimeout "Touchscreen user interface computer: a050 backup camera IPU timeout";
CM_ SG_ 291 UI_a051_BackupCameraFrameTimeout "Touchscreen user interface computer: a051 backup camera frame timeout";
CM_ SG_ 291 UI_a052_KernelPanicReported "Touchscreen user interface computer: a052 kernel panic reported";
CM_ SG_ 291 UI_a053_QtCarExitError "Signal reported by Touchscreen user interface computer";
CM_ SG_ 291 UI_a054_AudioBoostPowerBad "Touchscreen user interface computer: a054 audio boost power bad";
CM_ SG_ 291 UI_a055_ManualECallDisabled "Touchscreen user interface computer: a055 manual e call disabled";
CM_ SG_ 291 UI_a056_ManualECallButtonDisconn "Touchscreen user interface computer: a056 manual e call button disconnected";
CM_ SG_ 291 UI_a057_CellAntennaDisconnected "Touchscreen user interface computer: a057 cell antenna disconnected";
CM_ SG_ 291 UI_a058_GPSAntennaDisconnected "Touchscreen user interface computer: a058 GPS antenna disconnected";
CM_ SG_ 291 UI_a059_ECallSpeakerDisconnected "Touchscreen user interface computer: a059 e call speaker disconnected";
CM_ SG_ 291 UI_a060_ECallMicDisconnected "Touchscreen user interface computer: a060 e call mic disconnected";
CM_ SG_ 291 UI_a061_SIMTestFailed "Touchscreen user interface computer: a061 SIM test failed";
CM_ SG_ 291 UI_a062_ENSTestFailed "Touchscreen user interface computer: a062 ENS test failed";
CM_ SG_ 291 UI_a063_CellularTestFailed "Touchscreen user interface computer: a063 cellular test failed";
CM_ SG_ 291 UI_a064_ModemFirmwareTestFailed "Touchscreen user interface computer: a064 modem firmware test failed";
CM_ BO_ 292 "Touchscreen user interface computer message: alert matrix2";
CM_ SG_ 292 UI_a065_WiFiRecoveryReset "Touchscreen user interface computer: a065 wi fi recovery reset";
CM_ SG_ 292 UI_a066_GpuHangDetected "Touchscreen user interface computer: a066 gpu hang detected";
CM_ SG_ 292 UI_a067_WarnOnI915 "Touchscreen user interface computer: a067 warn on I915";
CM_ SG_ 292 UI_a068_VideoUnexpectedExit "Touchscreen user interface computer: a068 video unexpected exit";
CM_ SG_ 292 UI_a069_VideoUDPTimeout "Touchscreen user interface computer: a069 video UDP timeout";
CM_ SG_ 292 UI_a070_VideoPipelineWarning "Touchscreen user interface computer: a070 video pipeline warning";
CM_ SG_ 292 UI_a071_VideoPipelineError "Touchscreen user interface computer: a071 video pipeline error";
CM_ SG_ 292 UI_a072_ECallAnalogMicFailed "Touchscreen user interface computer: a072 e call analog mic failed";
CM_ SG_ 292 UI_a073_ECallDigitalMicFailed "Touchscreen user interface computer: a073 e call digital mic failed";
CM_ SG_ 292 UI_a074_EMMCHangDetected "Touchscreen user interface computer: a074 EMMC hang detected";
CM_ SG_ 292 UI_a075_BackupCameraInitError "Touchscreen user interface computer: a075 backup camera init error";
CM_ SG_ 292 UI_a076_NumFalseManualECalls "Touchscreen user interface computer: a076 num false manual e calls";
CM_ SG_ 292 UI_a077_AudioA2bMicChannelSwap "Touchscreen user interface computer: a077 audio a2b mic channel swap";
CM_ SG_ 292 UI_a078_DashcamUsbDriveUnmountab "Touchscreen user interface computer: a078 dashcam usb drive unmountable";
CM_ SG_ 292 UI_a079_DashcamUsbDriveFull "Touchscreen user interface computer: a079 dashcam usb drive full";
CM_ SG_ 292 UI_a080_DashcamUsbDriveSlow "Touchscreen user interface computer: a080 dashcam usb drive slow";
CM_ SG_ 292 UI_a081_CellModemSearchExpired "Touchscreen user interface computer: a081 cell modem search expired";
CM_ SG_ 292 UI_a082_NumModemRebootStuckInECa "Touchscreen user interface computer: a082 num modem reboot stuck in e call";
CM_ SG_ 292 UI_a083_ECallProxyWatchdogTrigge "Touchscreen user interface computer: a083 e call proxy watchdog triggered";
CM_ SG_ 292 UI_a084_SerializerError "Touchscreen user interface computer: a084 serializer error";
CM_ SG_ 292 UI_a085_DeserializerError "Touchscreen user interface computer: a085 deserializer error";
CM_ SG_ 292 UI_a086_TouchEnumerationError "Touchscreen user interface computer: a086 touch enumeration error";
CM_ SG_ 292 UI_a087_BmpReset "Touchscreen user interface computer: a087 bmp reset";
CM_ SG_ 292 UI_a088_CellRemovableSimMissing "Touchscreen user interface computer: a088 cell removable sim missing";
CM_ SG_ 292 UI_a089_RadioSoftResetError "Touchscreen user interface computer: a089 radio soft reset error";
CM_ SG_ 292 UI_a090_RadioPingFailError "Touchscreen user interface computer: a090 radio ping fail error";
CM_ SG_ 292 UI_a091_VehicleLinkStall "Touchscreen user interface computer: a091 vehicle link stall";
CM_ SG_ 292 UI_a092_updateStarted "Touchscreen user interface computer: a092 update started";
CM_ SG_ 292 UI_a093_updateEnded "Touchscreen user interface computer: a093 update ended";
CM_ SG_ 292 UI_a094_ModemPowerOnFailure "Touchscreen user interface computer: a094 modem power on failure";
CM_ SG_ 292 UI_a095_CidStorageRunningLow "Touchscreen user interface computer: a095 cid storage running low";
CM_ SG_ 292 UI_a096_VideodPipelineIssueDetec "Touchscreen user interface computer: a096 videod pipeline issue detected";
CM_ SG_ 292 UI_a097_AudiodRestarted "Touchscreen user interface computer: a097 audiod restarted";
CM_ SG_ 292 UI_a098_DiskCheckFailure "Touchscreen user interface computer: a098 disk check failure";
CM_ SG_ 292 UI_a099_eMMCStatusError "Touchscreen user interface computer: a099 e MMC status error";
CM_ SG_ 292 UI_a100_eMMCFTLError "Touchscreen user interface computer: a100 e MMCFTL error";
CM_ SG_ 292 UI_a101_wifiStackProblem "Touchscreen user interface computer: a101 wifi stack problem";
CM_ SG_ 292 UI_a102_A2bDiscoveryFailed "Touchscreen user interface computer: a102 a2b discovery failed";
CM_ SG_ 292 UI_a103_UsbHubNotEnumerating "Touchscreen user interface computer: a103 usb hub not enumerating";
CM_ SG_ 292 UI_a104_DashcamUsbDriveMissing "Touchscreen user interface computer: a104 dashcam usb drive missing";
CM_ SG_ 292 UI_a105_firmwareReinstallRequest "Touchscreen user interface computer: a105 firmware reinstall requested";
CM_ SG_ 292 UI_a106_rebootBackstopTriggered "Touchscreen user interface computer: a106 reboot backstop triggered";
CM_ SG_ 292 UI_a107_DashcamUsbDriveTooBigFor "Touchscreen user interface computer: a107 dashcam usb drive too big for vfat fsck";
CM_ SG_ 292 UI_a108_DashcamUsbDriveGettingFu "Touchscreen user interface computer: a108 dashcam usb drive getting full";
CM_ SG_ 292 UI_a109_DashcamUsbDriveTooSmall "Touchscreen user interface computer: a109 dashcam usb drive too small";
CM_ SG_ 292 UI_a110_DashcamUsbDriveCorrupt "Touchscreen user interface computer: a110 dashcam usb drive corrupt";
CM_ SG_ 292 UI_a111_DashcamUsbDriveNotSuperS "Touchscreen user interface computer: a111 dashcam usb drive not super speed";
CM_ SG_ 292 UI_a112_badUSBDevice "Touchscreen user interface computer: a112 bad USB device";
CM_ SG_ 292 UI_a113_DashcamHasOnboardSentryC "Touchscreen user interface computer: a113 dashcam has onboard sentry clips";
CM_ SG_ 292 UI_a114_drivingVisualizationDegr "Touchscreen user interface computer: a114 driving visualization degraded";
CM_ SG_ 292 UI_a115_IrisEDLMode "Touchscreen user interface computer: a115 iris EDL mode";
CM_ SG_ 292 UI_a116_UncorrectableMemoryError "Touchscreen user interface computer: a116 uncorrectable memory error";
CM_ SG_ 292 UI_a117_VehicleSelfTestRunning "Touchscreen user interface computer: a117 vehicle self test running";
CM_ SG_ 292 UI_a118_NVMeReset "Touchscreen user interface computer: a118 NV me reset";
CM_ SG_ 292 UI_a119_nvmeBlockDeviceMissing "Touchscreen user interface computer: a119 nvme block device missing";
CM_ SG_ 292 UI_a120_nvmePCIeLinkErrorDetecte "Touchscreen user interface computer: a120 nvme PC ie link error detected";
CM_ SG_ 292 UI_a121_nvmeSmartLogCritical "Touchscreen user interface computer: a121 nvme smart log critical";
CM_ SG_ 292 UI_a122_AMDI2C0LostArbitration "Touchscreen user interface computer: a122 AMDI2 C0 lost arbitration";
CM_ SG_ 292 UI_a123_AMDI2C1LostArbitration "Touchscreen user interface computer: a123 AMDI2 C1 lost arbitration";
CM_ SG_ 292 UI_a124_AMDI2C0TxRxAborted "Touchscreen user interface computer: a124 AMDI2 C0 tx rx aborted";
CM_ SG_ 292 UI_a125_AMDI2C1TxRxAborted "Touchscreen user interface computer: a125 AMDI2 C1 tx rx aborted";
CM_ SG_ 292 UI_a126_UsbErrorDriveCorrupt "Touchscreen user interface computer: a126 usb error drive corrupt";
CM_ SG_ 292 UI_a128_dgpuNotDetected "Touchscreen user interface computer: a128 dgpu not detected";
CM_ BO_ 293 "Touchscreen user interface computer message: alert matrix3";
CM_ SG_ 293 UI_a129_dgpuOperationFailure "Touchscreen user interface computer: a129 dgpu operation failure";
CM_ SG_ 293 UI_a130_QtCarClusterExitError "Signal reported by Touchscreen user interface computer";
CM_ SG_ 293 UI_a131_DisplayPortFailure "Touchscreen user interface computer: a131 display port failure";
CM_ SG_ 293 UI_a132_AdspWatchdogRecoveryTrig "Touchscreen user interface computer: a132 adsp watchdog recovery triggered";
CM_ SG_ 293 UI_a133_AdspWatchdogRecoveryFail "Touchscreen user interface computer: a133 adsp watchdog recovery failed";
CM_ SG_ 293 UI_a134_DashcamUsbDriveNoMedium "Touchscreen user interface computer: a134 dashcam usb drive no medium";
CM_ SG_ 293 UI_a135_warnRunOverlayExists "Touchscreen user interface computer: a135 warn run overlay exists";
CM_ SG_ 293 UI_a136_warnSettingsConfExists "Touchscreen user interface computer: a136 warn settings conf exists";
CM_ SG_ 293 UI_a137_ServiceShellActiveConnec "Touchscreen user interface computer: a137 service shell active connection";
CM_ SG_ 293 UI_a138_applyingConfigChange "Touchscreen user interface computer: a138 applying config change";
CM_ SG_ 293 UI_a139_postponedConfigChange "Touchscreen user interface computer: a139 postponed config change";
CM_ SG_ 293 UI_a140_NeverSleepActive "Touchscreen user interface computer: a140 never sleep active";
CM_ SG_ 293 UI_a141_falconDoorOpen "Touchscreen user interface computer: a141 falcon door open";
CM_ SG_ 293 UI_a142_CorrectableMemoryError "Touchscreen user interface computer: a142 correctable memory error";
CM_ SG_ 293 UI_a143_FPSCrawling "Touchscreen user interface computer: a143 FPS crawling";
CM_ SG_ 293 UI_a144_nvmeWarning "Touchscreen user interface computer: a144 nvme warning";
CM_ SG_ 293 UI_a145_nvmeUnsafeShutdown "Touchscreen user interface computer: a145 nvme unsafe shutdown";
CM_ SG_ 293 UI_a146_nvmeNeedsReplacement "Touchscreen user interface computer: a146 nvme needs replacement";
CM_ SG_ 293 UI_a147_ASILGlobalError "Touchscreen user interface computer: a147 ASIL global error";
CM_ SG_ 293 UI_a148_SleepFailure "Touchscreen user interface computer: a148 sleep failure";
CM_ SG_ 293 UI_a149_DisplayCheckFailure "Touchscreen user interface computer: a149 display check failure";
CM_ SG_ 293 UI_a150_infoCPURunningHot "Touchscreen user interface computer: a150 info CPU running hot";
CM_ SG_ 293 UI_a151_carComputerThermalProble "Touchscreen user interface computer: a151 car computer thermal problem";
CM_ SG_ 293 UI_a152_infoThrottling "Touchscreen user interface computer: a152 info throttling";
CM_ SG_ 293 UI_a153_serviceRestarted "Touchscreen user interface computer: a153 service restarted";
CM_ SG_ 293 UI_a154_AudiodBufferError "Touchscreen user interface computer: a154 audiod buffer error";
CM_ SG_ 293 UI_a155_UsbFrontHubUnavailable "Touchscreen user interface computer: a155 usb front hub unavailable";
CM_ SG_ 293 UI_a156_UsbFrontHubInstallMismat "Touchscreen user interface computer: a156 usb front hub install mismatch";
CM_ SG_ 293 UI_a157_MCUActiveCoolingRequeste "Touchscreen user interface computer: a157 MCU active cooling requested";
CM_ SG_ 293 UI_a158_UsbDeviceMountError "Touchscreen user interface computer: a158 usb device mount error";
CM_ SG_ 293 UI_a159_AudioHeartbeatFailure "Touchscreen user interface computer: a159 audio heartbeat failure";
CM_ SG_ 293 UI_a160_SystemWatchdogFailure "Touchscreen user interface computer: a160 system watchdog failure";
CM_ SG_ 293 UI_a161_ECallTemporarilyUnavaila "Touchscreen user interface computer: a161 e call temporarily unavailable";
CM_ SG_ 293 UI_a162_voiceRecClipsUploaded "Touchscreen user interface computer: a162 voice rec clips uploaded";
CM_ SG_ 293 UI_a163_QtCarVehicleExitError "Signal reported by Touchscreen user interface computer";
CM_ SG_ 293 UI_a164_AudiodConnTimeout "Touchscreen user interface computer: a164 audiod conn timeout";
CM_ SG_ 293 UI_a165_fsCorrupted "Touchscreen user interface computer: a165 fs corrupted";
CM_ SG_ 293 UI_a166_fsError "Touchscreen user interface computer: a166 fs error";
CM_ SG_ 293 UI_a167_CgroupOverMemKill "Touchscreen user interface computer: a167 cgroup over mem kill";
CM_ SG_ 293 UI_a168_dgpuPowerOnSelfTestFailu "Touchscreen user interface computer: a168 dgpu power on self test failure";
CM_ SG_ 293 UI_a169_SteamLoadShedFailure "Touchscreen user interface computer: a169 steam load shed failure";
CM_ SG_ 293 UI_a170_AMDdGPULoadShedFailure "Touchscreen user interface computer: a170 AM dd GPU load shed failure";
CM_ SG_ 293 UI_a171_GraphicsLoadShedRequeste "Touchscreen user interface computer: a171 graphics load shed requested";
CM_ SG_ 293 UI_a172_GraphicsLoadShedUIFailur "Touchscreen user interface computer: a172 graphics load shed UI failure";
CM_ SG_ 293 UI_a173_pmSuspendFailure "Touchscreen user interface computer: a173 pm suspend failure";
CM_ SG_ 293 UI_a174_HistorySaveLoop "Touchscreen user interface computer: a174 history save loop";
CM_ SG_ 293 UI_a176_CellularAntennaAlert "Touchscreen user interface computer: a176 cellular antenna alert";
CM_ SG_ 293 UI_a177_MediaPlayerFailure "Touchscreen user interface computer: a177 media player failure";
CM_ SG_ 293 UI_a178_irqDisabled "Touchscreen user interface computer: a178 irq disabled";
CM_ SG_ 293 UI_a179_TestDriveVideoDownloadFa "Touchscreen user interface computer: a179 test drive video download failure";
CM_ SG_ 293 UI_a180_AudiodInputRestarted "Touchscreen user interface computer: a180 audiod input restarted";
CM_ SG_ 293 UI_a181_ModemFirmwareVersionMism "Touchscreen user interface computer: a181 modem firmware version mismatch";
CM_ SG_ 293 UI_a182_VideoPipelineOverrun "Touchscreen user interface computer: a182 video pipeline overrun";
CM_ SG_ 293 UI_a183_DDAWFaulted "Touchscreen user interface computer: a183 DDAW faulted";
CM_ SG_ 293 UI_a184_ISAFaulted "Touchscreen user interface computer: a184 ISA faulted";
CM_ SG_ 293 UI_a185_ELKSDisabled "Touchscreen user interface computer: a185 ELKS disabled";
CM_ SG_ 293 UI_a186_ELKSUnavailable "Touchscreen user interface computer: a186 ELKS unavailable";
CM_ SG_ 293 UI_a187_TunerFirmwareMismatchedV "Touchscreen user interface computer: a187 tuner firmware mismatched version";
CM_ SG_ 293 UI_a188_TunerFirmwareMismatchedA "Touchscreen user interface computer: a188 tuner firmware mismatched API";
CM_ SG_ 293 UI_a189_TunerWatchdogReset "Touchscreen user interface computer: a189 tuner watchdog reset";
CM_ SG_ 293 UI_a190_TunerMIA "Touchscreen user interface computer: a190 tuner MIA";
CM_ SG_ 293 UI_a191_TunerUpdateFailed "Touchscreen user interface computer: a191 tuner update failed";
CM_ SG_ 293 UI_a192_AudioWatchdogReboot "Touchscreen user interface computer: a192 audio watchdog reboot";
CM_ BO_ 294 "Touchscreen user interface computer message: alert matrix4";
CM_ SG_ 294 UI_a193_TcuRNandFwVersionMismatc "Touchscreen user interface computer: a193 tcu r nand fw version mismatch";
CM_ SG_ 294 UI_a194_AudioweaverRestarted "Touchscreen user interface computer: a194 audioweaver restarted";
CM_ SG_ 294 UI_a195_gtwMfdUdpApiFired "Touchscreen user interface computer: a195 gtw mfd udp api fired";
CM_ SG_ 294 UI_a196_AMDI2C3BusInoperable "Touchscreen user interface computer: a196 AMDI2 C3 bus inoperable";
CM_ SG_ 294 UI_a197_AMDI2C1BusInoperable "Touchscreen user interface computer: a197 AMDI2 C1 bus inoperable";
CM_ SG_ 294 UI_a198_IncompatibleBTUSBHubHard "Touchscreen user interface computer: a198 incompatible BTUSB hub hardware";
CM_ SG_ 294 UI_a199_HighAPedalDetectedAtColl "Touchscreen user interface computer: a199 high a pedal detected at collision";
CM_ SG_ 294 UI_a200_UIFirmwareVersionMismatc "Touchscreen user interface computer: a200 UI firmware version mismatch";
CM_ SG_ 294 UI_a201_rearDisplayDisconnected "Touchscreen user interface computer: a201 rear display disconnected";
CM_ SG_ 294 UI_a202_sysMemoryIncorrect "Touchscreen user interface computer: a202 sys memory incorrect";
CM_ SG_ 294 UI_a204_ModemSleepFailure "Touchscreen user interface computer: a204 modem sleep failure";
CM_ SG_ 294 UI_a205_ModemSleepSignalMismatch "Touchscreen user interface computer: a205 modem sleep signal mismatch";
CM_ SG_ 294 UI_a206_ModemMIAAfterWake "Touchscreen user interface computer: a206 modem MIA after wake";
CM_ SG_ 294 UI_a207_mqttClientDisconnected "Touchscreen user interface computer: a207 mqtt client disconnected";
CM_ SG_ 294 UI_a208_mqttDisconnectReason "Touchscreen user interface computer: a208 mqtt disconnect reason";
CM_ SG_ 294 UI_a209_dataCallDisconnected "Touchscreen user interface computer: a209 data call disconnected";
CM_ SG_ 294 UI_a210_CellularCSRegFail "Touchscreen user interface computer: a210 cellular CS reg fail";
CM_ SG_ 294 UI_a211_AEBSDisabled "Touchscreen user interface computer: a211 AEBS disabled";
CM_ SG_ 294 UI_a212_AEBSFaulted "Touchscreen user interface computer: a212 AEBS faulted";
CM_ SG_ 294 UI_a213_ISADisabled "Touchscreen user interface computer: a213 ISA disabled";
CM_ SG_ 294 UI_a214_pmHelperFailure "Touchscreen user interface computer: a214 pm helper failure";
CM_ SG_ 294 UI_a215_compositorStallDetected "Touchscreen user interface computer: a215 compositor stall detected";
CM_ SG_ 294 UI_a216_AudioA2bCircuitProblem "Touchscreen user interface computer: a216 audio a2b circuit problem";
CM_ SG_ 294 UI_a217_CgroupMemoryPressure "Touchscreen user interface computer: a217 cgroup memory pressure";
CM_ SG_ 294 UI_a218_AudiodNoAudioDevices "Touchscreen user interface computer: a218 audiod no audio devices";
CM_ SG_ 294 UI_a219_CompositorWatchdog "Touchscreen user interface computer: a219 compositor watchdog";
CM_ SG_ 294 UI_a220_MediaBrowseError "Touchscreen user interface computer: a220 media browse error";
CM_ SG_ 294 UI_a221_NavigationServiceError "Touchscreen user interface computer: a221 navigation service error";
CM_ SG_ 294 UI_a222_QtCarRestart "Signal reported by Touchscreen user interface computer";
CM_ SG_ 294 UI_a223_databaseError "Touchscreen user interface computer: a223 database error";
CM_ SG_ 294 UI_a224_centerDisplayDisconnecte "Touchscreen user interface computer: a224 center display disconnected";
CM_ SG_ 294 UI_a225_clusterDisplayDisconnect "Touchscreen user interface computer: a225 cluster display disconnected";
CM_ SG_ 294 UI_a226_largePhoneContactSync "Touchscreen user interface computer: a226 large phone contact sync";
CM_ SG_ 294 UI_a228_pipewireXrunBurst "Touchscreen user interface computer: a228 pipewire xrun burst";
CM_ SG_ 294 UI_a229_SerDesError "Touchscreen user interface computer: a229 ser des error";
CM_ SG_ 294 UI_a230_ModemSimCardMismatch "Touchscreen user interface computer: a230 modem sim card mismatch";
CM_ SG_ 294 UI_a231_SleepCancelled "Touchscreen user interface computer: a231 sleep cancelled";
CM_ SG_ 294 UI_a232_processExitError "Touchscreen user interface computer: a232 process exit error";
CM_ SG_ 294 UI_a233_ModemRFFailure "Touchscreen user interface computer: a233 modem RF failure";
CM_ SG_ 294 UI_a234_AMDI2C0Timeout "Touchscreen user interface computer: a234 AMDI2 C0 timeout";
CM_ SG_ 294 UI_a235_AMDI2C1Timeout "Touchscreen user interface computer: a235 AMDI2 C1 timeout";
CM_ SG_ 294 UI_a236_ModemOnResetState "Touchscreen user interface computer: a236 modem on reset state";
CM_ SG_ 294 UI_a237_ClipUploadActive "Touchscreen user interface computer: a237 clip upload active";
CM_ SG_ 294 UI_a238_ModemConfigMismatch "Touchscreen user interface computer: a238 modem config mismatch";
CM_ SG_ 294 UI_a239_stateOfVehiclesFunctions "Touchscreen user interface computer: a239 state of vehicles functions feedback";
CM_ SG_ 294 UI_a240_ethError "Touchscreen user interface computer: a240 eth error";
CM_ SG_ 294 UI_a241_AxCPError "Touchscreen user interface computer: a241 ax CP error";
CM_ BO_ 1657 "Touchscreen user interface computer message: ambient lighting ctrls";
CM_ SG_ 1657 UI_ambientLightPopupOpen "Touchscreen user interface computer: ambient light popup open";
CM_ SG_ 1657 UI_rgbEnableState "Request to enable RGB lights";
CM_ SG_ 1657 UI_rgbEffectType "Reports the RGB light effect type.";
CM_ SG_ 1657 UI_rgbLightingColorHexRed "Touchscreen user interface computer: rgb lighting color hex red";
CM_ SG_ 1657 UI_rgbLightingColorHexGreen "Touchscreen user interface computer: rgb lighting color hex green";
CM_ SG_ 1657 UI_rgbLightingColorHexBlue "Touchscreen user interface computer: rgb lighting color hex blue";
CM_ SG_ 1657 UI_rgbBrightnessLevel "Reports the requested RGB brightness level; raw 127 = signal not available (SNA)";
CM_ SG_ 1657 UI_rgbTargetDOORFL "Target RGB control for front left door";
CM_ SG_ 1657 UI_rgbTargetDOORFR "Target RGB control for the front right door";
CM_ SG_ 1657 UI_rgbTargetDOORRL "Target RGB control for rear left door";
CM_ SG_ 1657 UI_rgbTargetDOORRR "Target RGB control for the rear right door";
CM_ SG_ 1657 UI_rgbTargetIPFL "Reports control for RGB lighting for the front left instrument panel.";
CM_ SG_ 1657 UI_rgbTargetIPFR "Reports control for RGB lighting for the front right instrument panel.";
BA_DEF_ BO_ "GenMsgCycleTime" INT 0 3600000;
BA_DEF_ BO_ "GenMsgSendType" ENUM "Cyclic","NotUsed","NotUsed","NotUsed","NotUsed","NotUsed","NotUsed","IfActive","NoMsgSendType","NotUsed";
BA_DEF_ BO_ "VFrameFormat" ENUM "StandardCAN","ExtendedCAN","reserved","J1939PG","reserved","reserved","reserved","reserved","reserved","reserved","reserved","reserved","reserved","reserved","StandardCAN_FD","ExtendedCAN_FD";
BA_DEF_ BO_ "CANFD_BRS" ENUM "0","1";
BA_DEF_ SG_ "GenSigSNA" STRING;
BA_DEF_ SG_ "SystemSignalLongSymbol" STRING;
BA_DEF_ SG_ "Confidence" ENUM "validated","plausible","layout-only","contradicted";
BA_DEF_DEF_ "GenMsgCycleTime" 0;
BA_DEF_DEF_ "GenMsgSendType" "NoMsgSendType";
BA_DEF_DEF_ "VFrameFormat" "StandardCAN";
BA_DEF_DEF_ "CANFD_BRS" "1";
BA_DEF_DEF_ "GenSigSNA" "";
BA_DEF_DEF_ "SystemSignalLongSymbol" "";
BA_DEF_DEF_ "Confidence" "layout-only";
BA_ "GenMsgCycleTime" BO_ 979 500;
BA_ "GenMsgSendType" BO_ 979 0;
BA_ "GenMsgCycleTime" BO_ 291 1000;
BA_ "GenMsgSendType" BO_ 291 0;
BA_ "GenMsgCycleTime" BO_ 292 1000;
BA_ "GenMsgSendType" BO_ 292 0;
BA_ "GenMsgCycleTime" BO_ 293 1000;
BA_ "GenMsgSendType" BO_ 293 0;
BA_ "GenMsgCycleTime" BO_ 294 1000;
BA_ "GenMsgSendType" BO_ 294 0;
BA_ "GenMsgCycleTime" BO_ 1657 500;
BA_ "GenMsgSendType" BO_ 1657 0;
BA_ "Confidence" SG_ 1560 UDS_icrRequestData 1;
BA_ "Confidence" SG_ 1603 UDS_ocs1pRequestData 1;
BA_ "Confidence" SG_ 1614 UDS_parkRequestData 1;
BA_ "Confidence" SG_ 1576 UDS_pcsRequestData 1;
BA_ "Confidence" SG_ 1634 UDS_plgRequestData 1;
BA_ "Confidence" SG_ 1568 UDS_pmRequestData 1;
BA_ "Confidence" SG_ 1604 UDS_pmfRequestData 1;
BA_ "Confidence" SG_ 1540 UDS_pmrRequestData 1;
BA_ "Confidence" SG_ 1734 UDS_ptcRequestData 1;
BA_ "Confidence" SG_ 1649 UDS_radcRequestData 1;
BA_ "Confidence" SG_ 1601 UDS_rcmRequestData 1;
BA_ "Confidence" SG_ 1664 UDS_sccmRequestData 1;
BA_ "Confidence" SG_ 1723 UDS_sdcrRequestData 1;
BA_ "Confidence" SG_ 1611 UDS_tasRequestData 1;
BA_ "Confidence" SG_ 1551 UDS_thcRequestData_H 1;
BA_ "Confidence" SG_ 1551 UDS_thcRequestData_L 1;
BA_ "Confidence" SG_ 1615 UDS_tpmsRequestData 1;
BA_ "Confidence" SG_ 1578 UDS_vcbatt1RequestData 1;
BA_ "Confidence" SG_ 1588 UDS_vcbatt2RequestData 1;
BA_ "Confidence" SG_ 1636 UDS_vcbattRequestData 1;
BA_ "Confidence" SG_ 1580 UDS_vcfront1RequestData 1;
BA_ "Confidence" SG_ 1582 UDS_vcfront2RequestData 1;
BA_ "Confidence" SG_ 1536 UDS_vcfrontRequestData 1;
BA_ "Confidence" SG_ 1570 UDS_vcleftRequestData_H 1;
BA_ "Confidence" SG_ 1570 UDS_vcleftRequestData_L 1;
BA_ "Confidence" SG_ 1544 UDS_vcrightRequestData_H 1;
BA_ "Confidence" SG_ 1544 UDS_vcrightRequestData_L 1;
BA_ "Confidence" SG_ 1546 UDS_vcsecRequestData 1;
BA_ "Confidence" SG_ 1056 UIS_logMux 1;
BA_ "Confidence" SG_ 1056 UIS_wifiTemperature 0;
BA_ "Confidence" SG_ 1056 UIS_wifiStackState 0;
BA_ "Confidence" SG_ 1056 UIS_wifiStackReady 1;
BA_ "Confidence" SG_ 1056 UIS_wifiBars 0;
BA_ "Confidence" SG_ 1056 UIS_wifiAutoJoinLowRSSI 0;
BA_ "Confidence" SG_ 1056 UIS_valetMode 0;
BA_ "Confidence" SG_ 1056 UIS_uiQtCarUptime 0;
BA_ "Confidence" SG_ 1056 UIS_uiMeanFPS 0;
BA_ "Confidence" SG_ 1056 UIS_tunerVoltageOperation 0;
BA_ "Confidence" SG_ 1056 UIS_tunerVoltageAntenna2 0;
BA_ "Confidence" SG_ 1056 UIS_tunerVoltageAntenna1 0;
BA_ "Confidence" SG_ 1056 UIS_tunerCurrentAntenna2 0;
BA_ "Confidence" SG_ 1056 UIS_tunerCurrentAntenna1 0;
BA_ "Confidence" SG_ 1056 UIS_testDriveMode 1;
BA_ "Confidence" SG_ 1056 UIS_tegraModemManState 0;
BA_ "Confidence" SG_ 1056 UIS_systemWakeTime 0;
BA_ "Confidence" SG_ 1056 UIS_systemUptime 0;
BA_ "Confidence" SG_ 1056 UIS_suspensionGeofence 0;
BA_ "Confidence" SG_ 1056 UIS_superchargePaymentNeeded 0;
BA_ "Confidence" SG_ 1056 UIS_sleepType 0;
BA_ "Confidence" SG_ 1056 UIS_sleepTime 0;
BA_ "Confidence" SG_ 1056 UIS_sleepState 0;
BA_ "Confidence" SG_ 1056 UIS_slackerLoginResult 0;
BA_ "Confidence" SG_ 1056 UIS_settingsAutoTurnSignal 1;
BA_ "Confidence" SG_ 1056 UIS_sentryState 0;
BA_ "Confidence" SG_ 1056 UIS_sentryNeedsNap 0;
BA_ "Confidence" SG_ 1056 UIS_sentryIncidentCount 0;
BA_ "Confidence" SG_ 1056 UIS_scheduledChargingMode 0;
BA_ "Confidence" SG_ 1056 UIS_scheduleChargeStartTime 0;
BA_ "Confidence" SG_ 1056 UIS_scheduleChargeEndTime 0;
BA_ "Confidence" SG_ 1056 UIS_remoteRequestType 0;
BA_ "Confidence" SG_ 1056 UIS_rearDisplayUserPresent 0;
BA_ "Confidence" SG_ 1056 UIS_rearDisplayState 0;
BA_ "Confidence" SG_ 1056 UIS_powerManagerState 0;
BA_ "GenSigSNA" SG_ 1056 UIS_powerManagerState "18";
BA_ "Confidence" SG_ 1056 UIS_polytopiax8664MemUsage 0;
BA_ "Confidence" SG_ 1056 UIS_polytopiax8664CPUUsage 0;
BA_ "Confidence" SG_ 1056 UIS_odinStatusCmdResult 1;
BA_ "Confidence" SG_ 1056 UIS_odinProcessState 1;
BA_ "Confidence" SG_ 1056 UIS_odinListTasksCmdResult 1;
BA_ "Confidence" SG_ 1056 UIS_odinHrlUploadLimits 1;
BA_ "Confidence" SG_ 1056 UIS_odinHrlLogUploadState 1;
BA_ "Confidence" SG_ 1056 UIS_odinHermesConnectionState 1;
BA_ "Confidence" SG_ 1056 UIS_odinGatewayConnectionState 1;
BA_ "Confidence" SG_ 1056 UIS_odinFileSystemState 1;
BA_ "Confidence" SG_ 1056 UIS_odinEcuLogUploadState 1;
BA_ "Confidence" SG_ 1056 UIS_odinEcuLogForceTriggerUpload 1;
BA_ "SystemSignalLongSymbol" SG_ 1056 UIS_odinEcuLogForceTriggerUpload "UIS_odinEcuLogForceTriggerUploadState";
BA_ "Confidence" SG_ 1056 UIS_navAudioVolume 0;
BA_ "Confidence" SG_ 1056 UIS_muteNavVolume 0;
BA_ "Confidence" SG_ 1056 UIS_mounterdState 1;
BA_ "Confidence" SG_ 1056 UIS_modemECallppAvail 0;
BA_ "Confidence" SG_ 1056 UIS_modemBusyActive 0;
BA_ "Confidence" SG_ 1056 UIS_mirrorGeofenceActive 0;
BA_ "Confidence" SG_ 1056 UIS_mediaPlaybackStatus 0;
BA_ "Confidence" SG_ 1056 UIS_mediaNeedAuthToken 0;
BA_ "Confidence" SG_ 1056 UIS_inSuperchargerGeofence 0;
BA_ "Confidence" SG_ 1056 UIS_homelinkState 0;
BA_ "Confidence" SG_ 1056 UIS_headsetPairResult 0;
BA_ "Confidence" SG_ 1056 UIS_headsetConnectionState 0;
BA_ "Confidence" SG_ 1056 UIS_gpsmanagerMemUsage 0;
BA_ "Confidence" SG_ 1056 UIS_gpsmanagerCPUUsage 0;
BA_ "Confidence" SG_ 1056 UIS_firmwareReleaseScope 1;
BA_ "Confidence" SG_ 1056 UIS_featureSuperchargingEnabled 0;
BA_ "Confidence" SG_ 1056 UIS_embeddedGameState 1;
BA_ "Confidence" SG_ 1056 UIS_embeddedGameName 1;
BA_ "Confidence" SG_ 1056 UIS_dumTclipUploadState 1;
BA_ "SystemSignalLongSymbol" SG_ 1056 UIS_dumTclipSuccessfulUploadCoun "UIS_dumTclipSuccessfulUploadCount";
BA_ "Confidence" SG_ 1056 UIS_dmRearTouchDeviceExists 0;
BA_ "Confidence" SG_ 1056 UIS_dmRearPowerState 0;
BA_ "Confidence" SG_ 1056 UIS_dmRearLinkCheckOk 0;
BA_ "Confidence" SG_ 1056 UIS_dmRearEnabled 0;
BA_ "Confidence" SG_ 1056 UIS_dmRearConnected 0;
BA_ "Confidence" SG_ 1056 UIS_dmRearBacklightPowerLevel 1;
BA_ "Confidence" SG_ 1056 UIS_dmRearBacklightDutyCycle 0;
BA_ "Confidence" SG_ 1056 UIS_dmRearBacklightDevExists 0;
BA_ "Confidence" SG_ 1056 UIS_dmIcuPowerState 0;
BA_ "Confidence" SG_ 1056 UIS_dmIcuLinkCheckOk 0;
BA_ "Confidence" SG_ 1056 UIS_dmIcuEnabled 0;
BA_ "Confidence" SG_ 1056 UIS_dmIcuConnected 0;
BA_ "Confidence" SG_ 1056 UIS_dmIcuBacklightPowerLevel 1;
BA_ "Confidence" SG_ 1056 UIS_dmIcuBacklightDutyCycle 0;
BA_ "Confidence" SG_ 1056 UIS_dmIcuBacklightDevExists 0;
BA_ "Confidence" SG_ 1056 UIS_dmIcuAsilResumeFlag 1;
BA_ "Confidence" SG_ 1056 UIS_dmIcuAsilFirmwareStatus 1;
BA_ "Confidence" SG_ 1056 UIS_dmGatewayLinkWedged 0;
BA_ "Confidence" SG_ 1056 UIS_dmCenterTouchDeviceExists 0;
BA_ "Confidence" SG_ 1056 UIS_dmCenterSOsdExactCrcCheck 1;
BA_ "Confidence" SG_ 1056 UIS_dmCenterPowerState 0;
BA_ "Confidence" SG_ 1056 UIS_dmCenterOsdDisplayedState 0;
BA_ "Confidence" SG_ 1056 UIS_dmCenterOsdDayNightState 1;
BA_ "Confidence" SG_ 1056 UIS_dmCenterModeSettingStatus 1;
BA_ "Confidence" SG_ 1056 UIS_dmCenterMOsdExactCrcCheck 1;
BA_ "Confidence" SG_ 1056 UIS_dmCenterLinkCheckOk 0;
BA_ "Confidence" SG_ 1056 UIS_dmCenterEnabled 0;
BA_ "Confidence" SG_ 1056 UIS_dmCenterConnected 0;
BA_ "Confidence" SG_ 1056 UIS_dmCenterBacklightPowerLevel 0;
BA_ "Confidence" SG_ 1056 UIS_dmCenterBacklightDutyCycle 0;
BA_ "Confidence" SG_ 1056 UIS_dmCenterBacklightDevExists 0;
BA_ "Confidence" SG_ 1056 UIS_dmCenterAsilResumeFlag 1;
BA_ "Confidence" SG_ 1056 UIS_dmCenterAsilFirmwareStatus 1;
BA_ "Confidence" SG_ 1056 UIS_dgpuTemperature 0;
BA_ "Confidence" SG_ 1056 UIS_dashcamviewerMemUsage 0;
BA_ "Confidence" SG_ 1056 UIS_dashcamviewerCPUUsage 0;
BA_ "Confidence" SG_ 1056 UIS_dashcamStorageState 0;
BA_ "Confidence" SG_ 1056 UIS_dashcamStorageSentryMB 0;
BA_ "Confidence" SG_ 1056 UIS_dashcamStorageSavedMB 0;
BA_ "Confidence" SG_ 1056 UIS_dashcamStorageRecentMB 0;
BA_ "Confidence" SG_ 1056 UIS_dashcamStorageAvailableMB 0;
BA_ "Confidence" SG_ 1056 UIS_dashcamState 0;
BA_ "Confidence" SG_ 1056 UIS_cpuTemperature 0;
BA_ "SystemSignalLongSymbol" SG_ 1056 UIS_compositorRenderMinRenderTim "UIS_compositorRenderMinRenderTime";
BA_ "SystemSignalLongSymbol" SG_ 1056 UIS_compositorRenderMaxRenderTim "UIS_compositorRenderMaxRenderTime";
BA_ "SystemSignalLongSymbol" SG_ 1056 UIS_compositorRenderGpuPercentag "UIS_compositorRenderGpuPercentage";
BA_ "SystemSignalLongSymbol" SG_ 1056 UIS_compositorRenderAvgRenderTim "UIS_compositorRenderAvgRenderTime";
BA_ "Confidence" SG_ 1056 UIS_compositorFrameMonitorState 1;
BA_ "Confidence" SG_ 1056 UIS_clusterMemUsage 0;
BA_ "Confidence" SG_ 1056 UIS_clusterDisplayState 0;
BA_ "Confidence" SG_ 1056 UIS_clusterCPUUsage 0;
BA_ "Confidence" SG_ 1056 UIS_chargeOnSolarNoChargeReason 0;
BA_ "Confidence" SG_ 1056 UIS_centerDisplayState 0;
BA_ "Confidence" SG_ 1056 UIS_centerDisplayEvent 0;
BA_ "Confidence" SG_ 1056 UIS_cellularLinkManagerState 0;
BA_ "Confidence" SG_ 1056 UIS_carAssistState 0;
BA_ "Confidence" SG_ 1056 UIS_carAssistSessionCount 0;
BA_ "Confidence" SG_ 1056 UIS_carAssistErrorCode 0;
BA_ "Confidence" SG_ 1056 UIS_cameraRRepeaterStreamMissing 0;
BA_ "Confidence" SG_ 1056 UIS_cameraRRepeaterStream 1;
BA_ "Confidence" SG_ 1056 UIS_cameraRRepeaterPopup 0;
BA_ "Confidence" SG_ 1056 UIS_cameraRRepeaterPipeline 0;
BA_ "Confidence" SG_ 1056 UIS_cameraLRepeaterStreamMissing 0;
BA_ "Confidence" SG_ 1056 UIS_cameraLRepeaterStream 1;
BA_ "Confidence" SG_ 1056 UIS_cameraLRepeaterPopup 0;
BA_ "Confidence" SG_ 1056 UIS_cameraLRepeaterPipeline 0;
BA_ "Confidence" SG_ 1056 UIS_cameraFrontStreamMissing 1;
BA_ "Confidence" SG_ 1056 UIS_cameraFrontStream 1;
BA_ "Confidence" SG_ 1056 UIS_cameraFrontPopup 1;
BA_ "Confidence" SG_ 1056 UIS_cameraFrontPipeline 1;
BA_ "Confidence" SG_ 1056 UIS_cameraBackupStreamQuality 1;
BA_ "Confidence" SG_ 1056 UIS_cameraBackupStreamMissing 0;
BA_ "Confidence" SG_ 1056 UIS_cameraBackupStream 1;
BA_ "Confidence" SG_ 1056 UIS_cameraBackupPopup 0;
BA_ "Confidence" SG_ 1056 UIS_cameraBackupPipeline 0;
BA_ "Confidence" SG_ 1056 UIS_cameraBackupFramerate 0;
BA_ "Confidence" SG_ 1056 UIS_boardTemperature 0;
BA_ "Confidence" SG_ 1056 UIS_bluetoothStackState 0;
BA_ "Confidence" SG_ 1056 UIS_bluetoothStackRearState 0;
BA_ "Confidence" SG_ 1056 UIS_bluetoothPairResult 0;
BA_ "Confidence" SG_ 1056 UIS_bluetoothMemUsage 0;
BA_ "Confidence" SG_ 1056 UIS_bluetoothConnectionState 0;
BA_ "Confidence" SG_ 1056 UIS_bluetoothCPUUsage 0;
BA_ "Confidence" SG_ 1056 UIS_bluetoothAutoConnectionState 0;
BA_ "Confidence" SG_ 1056 UIS_backlightUserRequest 0;
BA_ "Confidence" SG_ 1056 UIS_audioVolumeLevel 0;
BA_ "Confidence" SG_ 1056 UIS_audioType 0;
BA_ "Confidence" SG_ 1056 UIS_audioState 0;
BA_ "Confidence" SG_ 1056 UIS_audioSource 0;
BA_ "Confidence" SG_ 1056 UIS_audioPWSGain 0;
BA_ "Confidence" SG_ 1056 UIS_audioMediaPlaying 0;
BA_ "Confidence" SG_ 1056 UIS_audioMediaBrowsing 0;
BA_ "Confidence" SG_ 1056 UIS_audioA2BRediscoveryCount 0;
BA_ "Confidence" SG_ 1056 UIS_activeAppView 0;
BA_ "Confidence" SG_ 979 UI_airbagCutoffSwState 0;
BA_ "GenSigSNA" SG_ 979 UI_airbagCutoffSwState "2";
BA_ "Confidence" SG_ 979 UI_warningIndicatorStatus 1;
BA_ "GenSigSNA" SG_ 979 UI_warningIndicatorStatus "3";
BA_ "Confidence" SG_ 1523 UI_alertID 1;
BA_ "Confidence" SG_ 1523 UI_alertState 1;
BA_ "Confidence" SG_ 1523 UI_a036_audioWatchdogReason 1;
BA_ "SystemSignalLongSymbol" SG_ 1523 UI_a045_ManualECallButtonDisconn "UI_a045_ManualECallButtonDisconnected";
BA_ "Confidence" SG_ 1523 UI_a087_BmpResetType 1;
BA_ "Confidence" SG_ 1523 UI_a131_DisplayPortFailureType 1;
BA_ "Confidence" SG_ 1523 UI_a147_whichASIL 1;
BA_ "Confidence" SG_ 1523 UI_a147_errorCode 1;
BA_ "Confidence" SG_ 1523 UI_a148_sleepType 1;
BA_ "Confidence" SG_ 1523 UI_a148_lastFailedPmSuspendDev 1;
BA_ "Confidence" SG_ 1523 UI_a149_displayType 1;
BA_ "Confidence" SG_ 1523 UI_a149_errorCode 1;
BA_ "Confidence" SG_ 1523 UI_a153_processName 1;
BA_ "Confidence" SG_ 1523 UI_a153_restartReason 1;
BA_ "Confidence" SG_ 1523 UI_a158_UsbDeviceMountErrorCode 1;
BA_ "Confidence" SG_ 1523 UI_a165_fsCorruptedDevice 1;
BA_ "Confidence" SG_ 1523 UI_a166_fsErrorDevice 1;
BA_ "Confidence" SG_ 1523 UI_a167_processId 1;
BA_ "Confidence" SG_ 1523 UI_a173_errorCode 1;
BA_ "Confidence" SG_ 1523 UI_a173_lastFailedPmSuspendDev 1;
BA_ "Confidence" SG_ 1523 UI_a176_PrimaryAntenna 1;
BA_ "Confidence" SG_ 1523 UI_a176_SecondaryAntenna 1;
BA_ "Confidence" SG_ 1523 UI_a176_TertiaryAntenna 1;
BA_ "Confidence" SG_ 1523 UI_a177_errorCode 1;
BA_ "Confidence" SG_ 1523 UI_a192_AudioRebootState 1;
BA_ "Confidence" SG_ 1523 UI_a214_lastFailedPmSuspendDev 1;
BA_ "Confidence" SG_ 1523 UI_a216_circuitProblem 1;
BA_ "Confidence" SG_ 1523 UI_a216_circuitNode 1;
BA_ "Confidence" SG_ 1523 UI_a217_cgroupName 1;
BA_ "Confidence" SG_ 1523 UI_a220_errorCode 1;
BA_ "Confidence" SG_ 1523 UI_a222_errorCode 1;
BA_ "Confidence" SG_ 1523 UI_a223_database 1;
BA_ "Confidence" SG_ 1523 UI_a229_errorCode 1;
BA_ "Confidence" SG_ 1523 UI_a231_sleepType 1;
BA_ "Confidence" SG_ 1523 UI_a232_processExited 1;
BA_ "Confidence" SG_ 1523 UI_a232_processSignal 1;
BA_ "Confidence" SG_ 1523 UI_a240_ethErrorType 1;
BA_ "SystemSignalLongSymbol" SG_ 291 UI_a037_AudioWatchdogXrunStormEr "UI_a037_AudioWatchdogXrunStormError";
BA_ "SystemSignalLongSymbol" SG_ 291 UI_a038_AudioWatchdogA2bI2cLocku "UI_a038_AudioWatchdogA2bI2cLockupError";
BA_ "SystemSignalLongSymbol" SG_ 291 UI_a048_AudioPremiumAmpCheckFail "UI_a048_AudioPremiumAmpCheckFailed";
BA_ "SystemSignalLongSymbol" SG_ 291 UI_a056_ManualECallButtonDisconn "UI_a056_ManualECallButtonDisconnected";
BA_ "SystemSignalLongSymbol" SG_ 292 UI_a078_DashcamUsbDriveUnmountab "UI_a078_DashcamUsbDriveUnmountable";
BA_ "SystemSignalLongSymbol" SG_ 292 UI_a082_NumModemRebootStuckInECa "UI_a082_NumModemRebootStuckInECall";
BA_ "SystemSignalLongSymbol" SG_ 292 UI_a083_ECallProxyWatchdogTrigge "UI_a083_ECallProxyWatchdogTriggered";
BA_ "SystemSignalLongSymbol" SG_ 292 UI_a096_VideodPipelineIssueDetec "UI_a096_VideodPipelineIssueDetected";
BA_ "SystemSignalLongSymbol" SG_ 292 UI_a105_firmwareReinstallRequest "UI_a105_firmwareReinstallRequested";
BA_ "SystemSignalLongSymbol" SG_ 292 UI_a107_DashcamUsbDriveTooBigFor "UI_a107_DashcamUsbDriveTooBigForVfatFsck";
BA_ "SystemSignalLongSymbol" SG_ 292 UI_a108_DashcamUsbDriveGettingFu "UI_a108_DashcamUsbDriveGettingFull";
BA_ "SystemSignalLongSymbol" SG_ 292 UI_a111_DashcamUsbDriveNotSuperS "UI_a111_DashcamUsbDriveNotSuperSpeed";
BA_ "SystemSignalLongSymbol" SG_ 292 UI_a113_DashcamHasOnboardSentryC "UI_a113_DashcamHasOnboardSentryClips";
BA_ "SystemSignalLongSymbol" SG_ 292 UI_a114_drivingVisualizationDegr "UI_a114_drivingVisualizationDegraded";
BA_ "SystemSignalLongSymbol" SG_ 292 UI_a120_nvmePCIeLinkErrorDetecte "UI_a120_nvmePCIeLinkErrorDetected";
BA_ "SystemSignalLongSymbol" SG_ 293 UI_a132_AdspWatchdogRecoveryTrig "UI_a132_AdspWatchdogRecoveryTriggered";
BA_ "SystemSignalLongSymbol" SG_ 293 UI_a133_AdspWatchdogRecoveryFail "UI_a133_AdspWatchdogRecoveryFailed";
BA_ "SystemSignalLongSymbol" SG_ 293 UI_a137_ServiceShellActiveConnec "UI_a137_ServiceShellActiveConnection";
BA_ "SystemSignalLongSymbol" SG_ 293 UI_a151_carComputerThermalProble "UI_a151_carComputerThermalProblem";
BA_ "SystemSignalLongSymbol" SG_ 293 UI_a156_UsbFrontHubInstallMismat "UI_a156_UsbFrontHubInstallMismatch";
BA_ "SystemSignalLongSymbol" SG_ 293 UI_a157_MCUActiveCoolingRequeste "UI_a157_MCUActiveCoolingRequested";
BA_ "SystemSignalLongSymbol" SG_ 293 UI_a161_ECallTemporarilyUnavaila "UI_a161_ECallTemporarilyUnavailable";
BA_ "SystemSignalLongSymbol" SG_ 293 UI_a168_dgpuPowerOnSelfTestFailu "UI_a168_dgpuPowerOnSelfTestFailure";
BA_ "SystemSignalLongSymbol" SG_ 293 UI_a171_GraphicsLoadShedRequeste "UI_a171_GraphicsLoadShedRequested";
BA_ "SystemSignalLongSymbol" SG_ 293 UI_a172_GraphicsLoadShedUIFailur "UI_a172_GraphicsLoadShedUIFailure";
BA_ "SystemSignalLongSymbol" SG_ 293 UI_a179_TestDriveVideoDownloadFa "UI_a179_TestDriveVideoDownloadFailure";
BA_ "SystemSignalLongSymbol" SG_ 293 UI_a181_ModemFirmwareVersionMism "UI_a181_ModemFirmwareVersionMismatch";
BA_ "SystemSignalLongSymbol" SG_ 293 UI_a187_TunerFirmwareMismatchedV "UI_a187_TunerFirmwareMismatchedVersion";
BA_ "SystemSignalLongSymbol" SG_ 293 UI_a188_TunerFirmwareMismatchedA "UI_a188_TunerFirmwareMismatchedAPI";
BA_ "SystemSignalLongSymbol" SG_ 294 UI_a193_TcuRNandFwVersionMismatc "UI_a193_TcuRNandFwVersionMismatch";
BA_ "SystemSignalLongSymbol" SG_ 294 UI_a198_IncompatibleBTUSBHubHard "UI_a198_IncompatibleBTUSBHubHardware";
BA_ "SystemSignalLongSymbol" SG_ 294 UI_a199_HighAPedalDetectedAtColl "UI_a199_HighAPedalDetectedAtCollision";
BA_ "SystemSignalLongSymbol" SG_ 294 UI_a200_UIFirmwareVersionMismatc "UI_a200_UIFirmwareVersionMismatch";
BA_ "SystemSignalLongSymbol" SG_ 294 UI_a224_centerDisplayDisconnecte "UI_a224_centerDisplayDisconnected";
BA_ "SystemSignalLongSymbol" SG_ 294 UI_a225_clusterDisplayDisconnect "UI_a225_clusterDisplayDisconnected";
BA_ "SystemSignalLongSymbol" SG_ 294 UI_a239_stateOfVehiclesFunctions "UI_a239_stateOfVehiclesFunctionsFeedback";
BA_ "Confidence" SG_ 1657 UI_rgbEnableState 0;
BA_ "Confidence" SG_ 1657 UI_rgbEffectType 0;
BA_ "Confidence" SG_ 1657 UI_rgbBrightnessLevel 0;
BA_ "GenSigSNA" SG_ 1657 UI_rgbBrightnessLevel "127";
BA_ "Confidence" SG_ 1657 UI_rgbTargetDOORFL 0;
BA_ "Confidence" SG_ 1657 UI_rgbTargetDOORFR 0;
BA_ "Confidence" SG_ 1657 UI_rgbTargetDOORRL 0;
BA_ "Confidence" SG_ 1657 UI_rgbTargetDOORRR 0;
BA_ "Confidence" SG_ 1657 UI_rgbTargetIPFL 0;
BA_ "Confidence" SG_ 1657 UI_rgbTargetIPFR 0;
VAL_ 1056 UIS_logMux 354 "activeAppView" 353 "amdSocPkgPower" 352 "audioA2BRediscoveryCount" 351 "audioMediaBrowsing" 350 "audioMediaPlaying" 349 "audioPWSGain" 348 "audioSource" 347 "audioState" 346 "audioType" 345 "audioVolumeLevel" 344 "backlightUserRequest" 343 "bifrostCPUUsage" 342 "bifrostMemUsage" 341 "bifrostOdinEngineRequests" 340 "bifrostOdinEngineUp" 339 "bluetoothAutoConnectionState" 338 "bluetoothCPUUsage" 337 "bluetoothConnectionState" 336 "bluetoothMemUsage" 335 "bluetoothPairResult" 334 "bluetoothStackRearState" 333 "bluetoothStackState" 332 "boardTemperature" 331 "bootCount" 330 "camBackupDecodeAvgFrametime" 329 "camBackupDecodeFramecount" 328 "camBackupDecodeMaxFrametime" 327 "camBackupDecodeMinFrametime" 326 "cameraBackupFramerate" 325 "cameraBackupLateFrames" 324 "cameraBackupMaxFrametime" 323 "cameraBackupPipeline" 322 "cameraBackupPopup" 321 "cameraBackupStream" 320 "cameraBackupStreamMissing" 319 "cameraBackupStreamQuality" 318 "cameraFrontPipeline" 317 "cameraFrontPopup" 316 "cameraFrontStream" 315 "cameraFrontStreamMissing" 314 "cameraLRepeaterFramerate" 313 "cameraLRepeaterLateFrames" 312 "cameraLRepeaterMaxFrametime" 311 "cameraLRepeaterPipeline" 310 "cameraLRepeaterPopup" 309 "cameraLRepeaterStream" 308 "cameraLRepeaterStreamMissing" 307 "cameraRRepeaterFramerate" 306 "cameraRRepeaterLateFrames" 305 "cameraRRepeaterMaxFrametime" 304 "cameraRRepeaterPipeline" 303 "cameraRRepeaterPopup" 302 "cameraRRepeaterStream" 301 "cameraRRepeaterStreamMissing" 300 "carAssistErrorCode" 299 "carAssistSessionCount" 298 "carAssistState" 297 "cellularLinkManagerState" 296 "centerDispAsilA_lsb" 295 "centerDispAsilA_msb" 294 "centerDispAsilB_lsb" 293 "centerDispAsilB_msb" 292 "centerDisplayEvent" 291 "centerDisplayState" 290 "ceruleanx8664CPUUsage" 289 "ceruleanx8664MemUsage" 288 "chargeOnSolarNoChargeReason" 287 "chromiumadapterCPUUsage" 286 "chromiumadapterMemUsage" 285 "clusterCPUUsage" 284 "clusterDisplayState" 283 "clusterFramesOver100Ms" 282 "clusterFramesOver200Ms" 281 "clusterMaxFrametime" 280 "clusterMeanFPS" 279 "clusterMemUsage" 278 "cobaltlinuxCPUUsage" 277 "cobaltlinuxMemUsage" 276 "compositorFrameMonitorState" 275 "compositorRenderAvgRenderTime" 274 "compositorRenderFrameCount" 273 "compositorRenderFrameRate" 272 "compositorRenderGpuPercentage" 271 "compositorRenderMaxFrameTime" 270 "compositorRenderMaxRenderTime" 269 "compositorRenderMinFrameTime" 268 "compositorRenderMinRenderTime" 267 "cpuTemperature" 266 "dashcamOnboardAvailableMB" 265 "dashcamOnboardMB" 264 "dashcamOnboardSavePressCount" 263 "dashcamOnboardTransferCount" 262 "dashcamSavedToOnboardCount" 261 "dashcamSavedToSavedCount" 260 "dashcamSavedToSentryCount" 259 "dashcamState" 258 "dashcamStorageAvailableMB" 257 "dashcamStorageRecentMB" 256 "dashcamStorageSavedMB" 255 "dashcamStorageSentryMB" 254 "dashcamStorageState" 253 "dashcamTransferCount" 252 "dashcamTransferFileCount" 251 "dashcamTransferRateMBps" 250 "dashcamTransferSizeMB" 249 "dashcamTransferTimeMs" 248 "dashcamviewerCPUUsage" 247 "dashcamviewerMemUsage" 246 "developerMode" 245 "dgpuTemperature" 244 "dmCenterAsilFirmwareStatus" 243 "dmCenterAsilOpenFlag" 242 "dmCenterAsilResumeFlag" 241 "dmCenterAsilShortFlag" 240 "dmCenterBacklightDevExists" 239 "dmCenterBacklightDutyCycle" 238 "dmCenterBacklightFault" 237 "dmCenterBacklightNits" 236 "dmCenterBacklightPowerLevel" 235 "dmCenterConnected" 234 "dmCenterEnabled" 233 "dmCenterLinkCheckOk" 232 "dmCenterMOsdExactCrcCheck" 231 "dmCenterMOsdVideoCrcData" 230 "dmCenterModeSettingStatus" 229 "dmCenterOsdDayNightState" 228 "dmCenterOsdDisplayedState" 227 "dmCenterPowerState" 226 "dmCenterSOsdExactCrcCheck" 225 "dmCenterSOsdVideoCrcData" 224 "dmCenterTouchDeviceExists" 223 "dmCenterTouchIrqCount" 222 "dmGatewayLinkWedged" 221 "dmIcuAsilFirmwareStatus" 220 "dmIcuAsilOpenFlag" 219 "dmIcuAsilResumeFlag" 218 "dmIcuAsilShortFlag" 217 "dmIcuBacklightDevExists" 216 "dmIcuBacklightDutyCycle" 215 "dmIcuBacklightFault" 214 "dmIcuBacklightNits" 213 "dmIcuBacklightPowerLevel" 212 "dmIcuConnected" 211 "dmIcuEnabled" 210 "dmIcuLinkCheckOk" 209 "dmIcuPowerState" 208 "dmIcuTouchIrqCount" 207 "dmRearAsilStatusLsb" 206 "dmRearAsilStatusMsb" 205 "dmRearBacklightDevExists" 204 "dmRearBacklightDutyCycle" 203 "dmRearBacklightFault" 202 "dmRearBacklightNits" 201 "dmRearBacklightPowerLevel" 200 "dmRearConnected" 199 "dmRearEnabled" 198 "dmRearLinkCheckOk" 197 "dmRearPowerState" 196 "dmRearTouchDeviceExists" 195 "dumTclipClipCount" 194 "dumTclipSuccessfulUploadCount" 193 "dumTclipTransferCount" 192 "dumTclipUploadActive" 191 "dumTclipUploadState" 190 "embeddedGameName" 189 "embeddedGameState" 188 "estimatedOccupancyCount" 187 "featureSuperchargingEnabled" 186 "firmwareReleaseScope" 185 "godotCPUUsage" 184 "godotMemUsage" 183 "godot_MEMORY_DYNAMIC" 182 "godot_MEMORY_STATIC" 181 "godot_TIME_FPS" 180 "godot_TIME_PROCESS" 179 "gpsmanagerCPUUsage" 178 "gpsmanagerMemUsage" 177 "gtwSocUartRxStatBadChecksum" 176 "gtwSocUartRxStatBadTooBig" 175 "gtwSocUartRxStatBadTooSmall" 174 "gtwSocUartRxStatHandleErr" 173 "gtwSocUartRxStatHeartbeats" 172 "gtwSocUartRxStatMsgErr" 171 "gtwSocUartRxStatUnhandled" 170 "gtwSocUartRxStatValidPackets" 169 "gtwSocUartTxStatAnsMismatch" 168 "gtwSocUartTxStatBadTooBig" 167 "gtwSocUartTxStatNacks" 166 "gtwSocUartTxStatPackets" 165 "gtwSocUartTxStatTimeouts" 164 "headsetConnectionState" 163 "headsetPairResult" 162 "hermesclientCPUUsage" 161 "hermesclientMemUsage" 160 "hermesdynamicCPUUsage" 159 "hermesdynamicMemUsage" 158 "homelinkState" 157 "igpuTemperature" 156 "inSuperchargerGeofence" 155 "limex8664CPUUsage" 154 "limex8664MemUsage" 153 "mediaImageCacheCost" 152 "mediaImageCacheSize" 151 "mediaNeedAuthToken" 150 "mediaPlaybackStatus" 149 "mediaserveCPUUsage" 148 "mediaserveMemUsage" 147 "mirrorGeofenceActive" 146 "modemBusyActive" 145 "modemECallppAvail" 144 "mounterdDashcamCapacityGB" 143 "mounterdDeviceCount" 142 "mounterdEncryptionCapacityGB" 141 "mounterdFilesystemCountExfat" 140 "mounterdFilesystemCountExt3" 139 "mounterdFilesystemCountExt4" 138 "mounterdFilesystemCountFat32" 137 "mounterdFrontHubConnected" 136 "mounterdFrontHubDisconnected" 135 "mounterdMountCountTotal" 134 "mounterdState" 133 "muteNavVolume" 132 "navAudioVolume" 131 "nuanceserverCPUUsage" 130 "nuanceserverMemUsage" 129 "numCorrMemErrorsECC" 128 "numUncorrMemErrorsECC" 127 "nvmeDataUnitsWritten100mb" 126 "nvmePercentLifetimeUsed" 125 "nvmeTemperature" 124 "odinAuthCount" 123 "odinAuthFailCount" 122 "odinCPUUsage" 121 "odinEcuLogForceTriggerUploadState" 120 "odinEcuLogUploadState" 119 "odinFileSystemState" 118 "odinGatewayConnectionState" 117 "odinHermesConnectionState" 116 "odinHrlLogUploadState" 115 "odinHrlUploadLimits" 114 "odinListTasksCmdDurationMs" 113 "odinListTasksCmdResult" 112 "odinMemUsage" 111 "odinNetworkFailCount" 110 "odinNetworkStartCount" 109 "odinOrchestratorFailCount" 108 "odinOrchestratorStartCount" 107 "odinProcessState" 106 "odinStatusCmdDurationMs" 105 "odinStatusCmdResult" 104 "odincefCPUUsage" 103 "odincefMemUsage" 102 "polytopiax8664CPUUsage" 101 "polytopiax8664MemUsage" 100 "powerManagerState" 99 "psiCpuSome" 98 "psiIOFull" 97 "psiIOSome" 96 "psiMemFull" 95 "psiMemSome" 94 "qtcarCPUUsage" 93 "qtcarMemUsage" 92 "radioserveCPUUsage" 91 "radioserveMemUsage" 90 "rearDisplayState" 89 "rearDisplayUserPresent" 88 "releasenotesCPUUsage" 87 "releasenotesMemUsage" 86 "remoteRequestType" 85 "scheduleChargeEndTime" 84 "scheduleChargeStartTime" 83 "scheduledChargingMode" 82 "sentryIncidentCount" 81 "sentryNeedsNap" 80 "sentryState" 79 "serverCPUUsage" 78 "serverMemUsage" 77 "serviceMode" 76 "serviceModePlus" 75 "settingsAutoTurnSignal" 74 "slackerLoginResult" 73 "sleepCount" 72 "sleepState" 71 "sleepTime" 70 "sleepType" 69 "solitaireCPUUsage" 68 "solitaireMemUsage" 67 "speechrecoCPUUsage" 66 "speechrecoMemUsage" 65 "spotifyserverCPUUsage" 64 "spotifyserverMemUsage" 63 "sudokuCPUUsage" 62 "sudokuMemUsage" 61 "superchargePaymentNeeded" 60 "suspensionGeofence" 59 "systemMemSwapUsage" 58 "systemUptime" 57 "systemWakeTime" 56 "tegraModemManState" 55 "teslaMediaCacheCost" 54 "teslaMediaCacheSize" 53 "teslacefgpuCPUUsage" 52 "teslacefgpuMemUsage" 51 "teslacefzygotCPUUsage" 50 "teslacefzygotMemUsage" 49 "teslachromiumCPUUsage" 48 "teslachromiumMemUsage" 47 "testDriveMode" 46 "tmserverCPUUsage" 45 "tmserverMemUsage" 44 "touchEventsAggCount" 43 "tunerCurrentAntenna1" 42 "tunerCurrentAntenna2" 41 "tunerTemperatureCelsius" 40 "tunerTemperatureFahrenheit" 39 "tunerVoltage1V8" 38 "tunerVoltage3V3" 37 "tunerVoltageAntenna1" 36 "tunerVoltageAntenna2" 35 "tunerVoltageMQS" 34 "tunerVoltageOperation" 33 "tunerVoltageUBatt" 32 "uiFramesOver100Ms" 31 "uiFramesOver200Ms" 30 "uiMaxFrametime" 29 "uiMeanFPS" 28 "uiQtCarSwapUsage" 27 "uiQtCarUptime" 26 "valetMode" 25 "valhallaserverCPUUsage" 24 "valhallaserverMemUsage" 23 "vehicleCPUUsage" 22 "vehicleMemUsage" 21 "videodCPUUsage" 20 "videodMemUsage" 19 "vmtouchCPUUsage" 18 "vmtouchMemUsage" 17 "webbrowserCPUUsage" 16 "webbrowserMemUsage" 15 "wifiAutoJoinLowRSSI" 14 "wifiBars" 13 "wifiStackReady" 12 "wifiStackState" 11 "wifiTemperature" 10 "zramCompressedSize" 9 "zramCompressionRatio" 8 "zramFailedReads" 7 "zramFailedWrites" 6 "zramInvalidIO" 5 "zramNotifyFree" 4 "zramOriginalSize" 3 "zramReadIO" 2 "zramReadTicks" 1 "zramWriteIO" 0 "zramWriteTicks" ;
VAL_ 1056 UIS_wifiStackState 17 "WL_RESET_CONNMAN" 16 "WL_RUNNING_LOCAL" 15 "WL_CAPTIVE" 14 "WL_DISCONNECTING" 13 "WL_RUNNING" 12 "WL_WAITING_ONLINE" 11 "WL_CHECKING" 10 "WL_CONFIGURING" 9 "WL_CONNECTING" 8 "WL_SELECTING_NETWORK" 7 "WL_WAITING_AUTOCONNECT" 6 "WL_SEARCHING" 5 "WL_POWERING_ON" 4 "WL_DISABLED_WAIT" 3 "WL_POWERING_OFF" 2 "WL_WAITING_TECHNOLOGY" 1 "WL_RESETTING" 0 "DEFAULT" ;
VAL_ 1056 UIS_wifiStackReady 1 "TRUE" 0 "FALSE" ;
VAL_ 1056 UIS_wifiAutoJoinLowRSSI 1 "TRUE" 0 "FALSE" ;
VAL_ 1056 UIS_valetMode 1 "TRUE" 0 "FALSE" ;
VAL_ 1056 UIS_testDriveMode 1 "ENABLED" 0 "DISABLED" ;
VAL_ 1056 UIS_tegraModemManState 20 "INVALID" 19 "CHECKINGMODEM" 18 "CHECKINGPORTS" 17 "STOPPINGLINK" 16 "UNCONFIGURINGLINK" 15 "RUNNINGSTATUS" 14 "RUNNING" 13 "CHECKINGLINK" 12 "CONFIGURINGLINK" 11 "RETRYINGLINK" 10 "STARTINLINK" 9 "PRECONDITIONINGLINK" 8 "INITIALIZING2" 7 "CHECKINGANTENNA" 6 "ENABLINGSIM" 5 "INITIALIZING1" 4 "RECOVERING" 3 "WAKING" 2 "SLEEPING" 1 "RESTARTING" 0 "ABORTINGLINK" ;
VAL_ 1056 UIS_suspensionGeofence 1 "REQUESTED" 0 "REMOVED" ;
VAL_ 1056 UIS_sleepType 4 "Unknown" 3 "ModernStandby" 2 "S2Idle" 1 "S3" 0 "Shallow" ;
VAL_ 1056 UIS_sleepState 3 "Wake" 2 "Sleep" 1 "Run" 0 "Boot" ;
VAL_ 1056 UIS_slackerLoginResult 5000 "SLACKER_LOGIN_CREDENTIALS_MISSING" 444 "SLACKER_LOGIN_USER_BUMPED" 412 "SLACKER_LOGIN_TOKEN_INVALID_TIMESTAMP" 409 "SLACKER_LOGIN_TOKEN_REVOKED_KEY" 403 "SLACKER_LOGIN_CAPTCHA_REQUIRED" 401 "SLACKER_LOGIN_INCORRECT_CREDENTIALS" 400 "SLACKER_LOGIN_TOKEN_INVALID_SIGNATURE" 6 "SLACKER_LOGIN_BAD_ACCOUNT_LEVEL" 5 "SLACKER_LOGIN_OTHER_ERROR" 4 "SLACKER_LOGIN_NET_ERROR" 3 "SLACKER_LOGIN_TOKEN_UNKNOWN_ERROR" 2 "SLACKER_LOGIN_SUCCESS" 1 "SLACKER_LOGIN_SERVERTIME_FAILED" ;
VAL_ 1056 UIS_settingsAutoTurnSignal 1 "AUTO_CANCEL" 0 "OFF" ;
VAL_ 1056 UIS_sentryState 5 "QUIET" 4 "PANIC" 3 "AWARE" 2 "ARMED" 1 "IDLE" 0 "OFF" ;
VAL_ 1056 UIS_scheduledChargingMode 3 "TIME_WINDOW" 2 "END_BY" 1 "START_AT" 0 "OFF" ;
VAL_ 1056 UIS_remoteRequestType 106 "NAV_GPS_DESTINATION_REQUEST" 105 "TESLA_AUTH_RESPONSE" 104 "GET_MESSAGE" 103 "SET_LIGHTBAR_DITCH" 102 "SET_LIGHTBAR_MIDDLE" 101 "SET_LIGHTBAR_BRIGHTNESS" 100 "REMOVE_PRECONDITION_SCHEDULE" 99 "ADD_PRECONDITION_SCHEDULE" 98 "REMOVE_CHARGE_SCHEDULE" 97 "ADD_CHARGE_SCHEDULE" 96 "SET_REAR_ZONE_LIGHT_REQUEST" 95 "SET_FRONT_ZONE_LIGHT_REQUEST" 94 "SET_TENT_MODE_REQUEST" 93 "SET_POWERSHARE_REQUEST" 92 "SET_POWERSHARE_DISCHARGE_LIMIT" 91 "SET_POWERSHARE_FEATURE" 90 "NAVIGATION_WAYPOINTS_REQUEST" 89 "VEHICLE_CONTROL_RESET_PIN_TO_DRIVE_ADMIN" 88 "SET_TRUCK_BED_LIGHT_BRIGHTNESS" 87 "SET_TRUCK_BED_LIGHT_AUTO_STATE" 86 "SET_TRAILER_LIGHT_TEST_START_STOP" 85 "SET_POWER_FEED_SOC_LIMIT" 84 "SET_POWER_FEED_TIMER" 83 "SET_POWER_FEED_ON_OFF" 82 "SET_OUTLET_SOC_LIMIT" 81 "SET_OUTLET_TIMER" 80 "SET_OUTLETS_ON_OFF" 79 "DRIVING_CLEAR_SPEED_LIMIT_PIN_ADMIN" 78 "VEHICLE_CONTROL_RESET_PIN_TO_DRIVE" 77 "VEHICLE_CONTROL_SET_PIN_TO_DRIVE" 76 "RESERVED_SEVENTY_SIX" 75 "GET_CHARGE_ON_SOLAR_FEATURE" 74 "UPDATE_CHARGE_ON_SOLAR_FEATURE" 73 "GET_MANAGED_CHARGING_SITES" 72 "ERASE_USER_DATA" 71 "STW_HEAT_LEVEL" 70 "AUTO_STW_HEAT" 69 "NAVIGATION_ROUTE" 68 "REMOVE_MANAGED_CHARGING_SITE" 67 "ADD_MANAGED_CHARGING_SITE" 66 "SET_COP_TEMP" 65 "GUEST_MODE" 64 "BOOMBOX" 63 "BLUETOOTH_CLASSIC_PAIRING_REQUEST" 62 "CHARGE_PORT_DOOR_OPEN" 61 "CHARGE_PORT_DOOR_CLOSE" 60 "RESERVED_SIXTY" 59 "RESERVED_FIFTY_NINE" 58 "TAKE_DRIVENOTE" 57 "VIDEO_REQUEST" 56 "GET_RATE_TARIFF" 55 "RESERVED_FIFTY_FIVE" 54 "SET_VEHICLE_NAME" 53 "NAVIGATION_GPS_REQUEST" 52 "PSEUDONYM_SYNC_REQUEST" 51 "PII_KEY_REQUEST" 50 "SET_CABIN_OVERHEAT_PROTECTION" 49 "HVAC_SEAT_COOLER_ACTIONS" 48 "AUTO_SEAT_CLIMATE" 47 "DASHCAM_SAVE_CLIP" 46 "PING" 45 "HVAC_RECIRCULATION" 44 "HVAC_CLIMATE_KEEPER" 43 "SET_CHARGING_AMPS" 42 "SCHEDULED_DEPARTURE" 41 "SCHEDULED_CHARGING" 40 "VITALS_ACK" 39 "VITALS_SUBSCRIPTION" 38 "VEHICLE_DATA_ACK" 37 "VEHICLE_DATA_SUBSCRIPTION" 36 "HVAC_SEAT_HEATER_ACTIONS" 35 "HVAC_BIO_WEAPON_MODE" 34 "VEHICLE_CONTROL_WINDOW" 33 "VEHICLE_CONTROL_TRIGGER_HOMELINK" 32 "VEHICLE_CONTROL_SUNROOF_OPEN_CLOSE" 31 "VEHICLE_CONTROL_SET_VALET_MODE" 30 "VEHICLE_CONTROL_SET_SENTRY_MODE" 29 "VEHICLE_CONTROL_SCHEDULE_SOFTWARE_UPDATE" 28 "VEHICLE_CONTROL_RESET_VALET_PIN" 27 "VEHICLE_CONTROL_HONK_HORN" 26 "VEHICLE_CONTROL_FLASH_LIGHTS" 25 "VEHICLE_CONTROL_CANCEL_SOFTWARE_UPDATE" 24 "UI_SET_UPCOMING_CALENDAR_ENTRIES" 23 "GET_NEARBY_CHARGING_SITES" 22 "NAVIGATION_SUPERCHARGER_REQUEST" 21 "NAVIGATION_REQUEST" 20 "MEDIA_PREVIOUS_TRACK" 19 "MEDIA_NEXT_TRACK" 18 "MEDIA_PREVIOUS_FAVORITE" 17 "MEDIA_NEXT_FAVORITE" 16 "MEDIA_UPDATE_VOLUME" 15 "MEDIA_PLAY" 14 "HVAC_TEMPERATURE_ADJUSTMENT" 13 "HVAC_STEERING_WHEEL_HEATER" 12 "HVAC_SET_PRECONDITIONING_MAX" 11 "RESERVED_ELEVEN" 10 "HVAC_AUTO" 9 "DRIVING_SPEED_LIMIT" 8 "DRIVING_SET_SPEED_LIMIT" 7 "DRIVING_CLEAR_SPEED_LIMIT_PIN" 6 "CHARGING_START_STOP" 5 "CHARGING_SET_LIMIT" 4 "STREAM_MESSAGE" 3 "CREATE_STREAM_SESSION" 2 "REMOTE_START_DRIVE" 1 "GET_VEHICLE_DATA" 0 "UNKNOWN" ;
VAL_ 1056 UIS_rearDisplayUserPresent 1 "TRUE" 0 "FALSE" ;
VAL_ 1056 UIS_rearDisplayState 9 "ENTERTAINMENT" 8 "DOG" 7 "SENTRY" 6 "LOCK" 5 "CHARGING" 4 "DRIVING" 3 "ON" 2 "ACCESSORY" 1 "DIM" 0 "OFF" ;
VAL_ 1056 UIS_powerManagerState 31 "PMS_ENTERINGROBOTAXILOADSHED" 30 "PMS_ROBOTAXILOADSHEDDING" 29 "PMS_UPLOADDATA" 28 "PMS_EXTREMELOADSHEDDING" 27 "PMS_ENTERINGEXTREMELOADSHED" 26 "PMS_PREPARINGSLEEP" 25 "PMS_ENTERINGLOADSHED" 24 "PMS_SENTRYACTIVE" 23 "PMS_EXITINGLOADSHED" 22 "PMS_LOADSHEDDING" 21 "PMS_EXITINGSENTRY" 20 "PMS_SENTRYARMED" 19 "PMS_ENTERINGSENTRY" 18 "PMS_UNKNOWN_SNA" 17 "PMS_EXITINGSLEEP" 16 "PMS_READYFORSLEEP" 15 "PMS_WAITINGONRAILS" 14 "PMS_PERFORMANCE" 13 "PMS_HIGHPOWERSTARTED" 12 "PMS_HIGHPOWERSTOPPING" 11 "PMS_HIGHPOWERSTARTING" 10 "PMS_REBOOT" 9 "PMS_ENTERINGSLEEP" 8 "PMS_ALLTUCKEDIN" 7 "PMS_CHARGING" 6 "PMS_AUDIOSTOPPED" 5 "PMS_AUDIOSTOPPING" 4 "PMS_POWERBROWNOUT" 3 "PMS_AUDIOSTARTING" 2 "PMS_ACCDELAY" 1 "PMS_FULLPOWER" 0 "PMS_CHECKING" ;
VAL_ 1056 UIS_odinStatusCmdResult 2 "EXCEPTION" 1 "FAIL" 0 "PASS" ;
VAL_ 1056 UIS_odinProcessState 4 "UNKNOWN" 3 "RUNNING_NETWORK_AND_ORCHESTRATOR" 2 "RUNNING_ORCHESTRATOR" 1 "RUNNING_NETWORK" 0 "IDLE" ;
VAL_ 1056 UIS_odinListTasksCmdResult 2 "EXCEPTION" 1 "FAIL" 0 "PASS" ;
VAL_ 1056 UIS_odinHrlUploadLimits 1 "CELL_DAILY_UPLOAD_LIMIT_REACHED" 0 "DAILY_UPLOAD_LIMIT_REACHED" ;
VAL_ 1056 UIS_odinHrlLogUploadState 4 "HRL_FILE_UPLOADED" 3 "HRL_FILE_UPLOAD_FAILED" 2 "HRL_FILE_TRANSFER_FAILED" 1 "HRL_FILE_TRANSFERRED" 0 "SERVICE_STARTED" ;
VAL_ 1056 UIS_odinHermesConnectionState 3 "CONNECTION_ERROR" 2 "CONNECTING" 1 "CONNECTED" 0 "DISCONNECTED" ;
VAL_ 1056 UIS_odinGatewayConnectionState 2 "CONNECTION_ERROR" 1 "CONNECTED" 0 "DISCONNECTED" ;
VAL_ 1056 UIS_odinFileSystemState 4 "DIR_SIZE_LIMIT_SURPASSED" 3 "OVERSIZED_FILE" 2 "DIR_DELETED" 1 "FILE_DELETED" 0 "IDLE" ;
VAL_ 1056 UIS_odinEcuLogUploadState 5 "FAILURE" 4 "COMPLETE" 3 "UPLOADING" 2 "GET_DATA" 1 "POLLING" 0 "IDLE" ;
VAL_ 1056 UIS_odinEcuLogForceTriggerUpload 1 "REQUESTED" 0 "IDLE" ;
VAL_ 1056 UIS_mounterdState 9 "MOUNTING_STEAM" 8 "MOUNTING_LIGHTSHOW" 7 "MOUNTING_UPDATE" 6 "MOUNTING_MEDIA" 5 "MOUNTING_ENCRYPTION" 4 "MOUNTING_DASHCAM" 3 "UNMOUNTING" 2 "IDLE" 1 "TERMINATED" 0 "INVALID" ;
VAL_ 1056 UIS_modemECallppAvail 1 "ENABLED" 0 "DISABLED" ;
VAL_ 1056 UIS_modemBusyActive 1 "RUNNING" 0 "OFF" ;
VAL_ 1056 UIS_mirrorGeofenceActive 1 "TRUE" 0 "FALSE" ;
VAL_ 1056 UIS_mediaPlaybackStatus 2 "PAUSED" 1 "PLAYING" 0 "STOPPED" ;
VAL_ 1056 UIS_mediaNeedAuthToken 1 "TRUE" 0 "FALSE" ;
VAL_ 1056 UIS_inSuperchargerGeofence 1 "TRUE" 0 "FALSE" ;
VAL_ 1056 UIS_homelinkState 23 "HW_ERROR" 22 "UNIVERSAL_RECEIVER_ERROR" 21 "UNIVERSAL_RECEIVER_SUCCESS" 20 "UNIVERSAL_RECEIVER_WAIT" 19 "DEFAULT_FAIL" 18 "DEFAULT_SUCCESS" 17 "DEFAULT_WAIT" 16 "STANDARD_FAIL" 15 "STANDARD_SUCCESS" 14 "STANDARD_WAIT" 13 "CLEAR_FAIL" 12 "CLEAR_SUCCESS" 11 "CLEAR_WAIT" 10 "TIMEOUT" 9 "LEARN_FAIL" 8 "LEARN_CANCLE" 7 "LEARN_SUCCESS_NOT_ROLLING" 6 "LEARN_SUCCESS_ROLLING" 5 "LEARN_TEST" 4 "LEARN_SUCCESS" 3 "LEARN_WAIT" 2 "PROGRAM_WAIT" 1 "TRANSMITTING" 0 "IDLE" ;
VAL_ 1056 UIS_headsetPairResult 23 "HID_PAIRED" 22 "HID_MAX_NR_OF_CONNS" 21 "HID_PAGE_TIMEOUT" 20 "HID_OETC_USER" 19 "HID_REJ_BY_REMOTE_NO_RES" 18 "HID_LMP_RESPONSE_TIMEOUT" 17 "HID_AUTH_FAILURE" 16 "HID_KEY_MISSING" 15 "HID_NO_RESPONSE" 14 "HID_ALREADY_REQUESTED_BY_REMOTE" 13 "HID_UNKNOWN" 12 "HID_UNPAIRED" 11 "PAIRED" 10 "MAX_NR_OF_CONNS" 9 "PAGE_TIMEOUT" 8 "OETC_USER" 7 "REJ_BY_REMOTE_NO_RES" 6 "LMP_RESPONSE_TIMEOUT" 5 "AUTH_FAILURE" 4 "KEY_MISSING" 3 "NO_RESPONSE" 2 "ALREADY_REQUESTED_BY_REMOTE" 1 "UNKNOWN" 0 "UNPAIRED" ;
VAL_ 1056 UIS_headsetConnectionState 77 "HID_ERROR_UNKNOWN" 76 "HID_ERROR_ANTENNA_DISCONNECTED" 75 "HID_CONNECTED" 74 "HID_CONNECT_CANCELLED" 73 "HID_CONNECT_PROFILE_UNAVAILABLE" 72 "HID_CONNECT_INVALID_ARGUMENT" 71 "HID_CONNECT_ADAPTER_OFF" 70 "HID_CONNECT_NOT_SUPPORTED" 69 "HID_CONNECT_ALREADY_CONN" 68 "HID_CONNECT_DEVICE_NOT_FOUND_NO_RESOURCES" 67 "HID_CONNECT_DEVICE_NOT_FOUND_PAGE_TIMEOUT" 66 "HID_CONNECT_DEVICE_NOT_FOUND" 65 "HID_CONNECT_FAILED_REMOTE_TERMINATED" 64 "HID_CONNECT_FAILED_NO_RESOURCES" 63 "HID_CONNECT_FAILED_CONNECTION_TIMEOUT" 62 "HID_CONNECT_FAILED" 61 "HID_CONNECT_SDP_FAILURE" 60 "HID_CONNECT_PIN_MISSING" 59 "HID_CONNECT_PAGE_TIMEOUT" 58 "HID_CONNECT_REJ_BY_REMOTE_NO_RES" 57 "HID_CONNECT_MAX_NR_OF_CONNS" 56 "HID_CONNECT_CONTROLLER_BUSY" 55 "HID_CONNECT_CONN_TIMEOUT" 54 "HID_CONNECT_MAX_NR_OF_ACL" 53 "HID_CONNECT_LMP_RESPONSE_TIMEOUT" 52 "HID_CONNECT_HOST_TIMEOUT" 51 "HID_CONNECT_UNKNOWN_FAILURE" 50 "HID_DISCONNECT_UNKNOWN" 49 "HID_DISCONNECT_OETC_POWERING_OFF" 48 "HID_DISCONNECT_OETC_LOW_RESOURCE" 47 "HID_DISCONNECT_REJ_BY_REMOTE_SEC" 46 "HID_DISCONNECT_AUTH_FAIL" 45 "HID_DISCONNECT_LMP_RESPONSE_TIMEOUT" 44 "HID_DISCONNECT_OETC_USER" 43 "HID_DISCONNECT_CONN_TIMEOUT" 42 "HID_DISCONNECT_CONN_TERM_LOCAL_HOST" 41 "HID_DISCONNECT_LINKLOSS" 40 "HID_DISCONNECT_FROM_REMOTE" 39 "HID_DISCONNECTED" 38 "ERROR_UNKNOWN" 37 "ERROR_ANTENNA_DISCONNECTED" 36 "CONNECTED" 35 "CONNECT_CANCELLED" 34 "CONNECT_PROFILE_UNAVAILABLE" 33 "CONNECT_INVALID_ARGUMENT" 32 "CONNECT_ADAPTER_OFF" 31 "CONNECT_NOT_SUPPORTED" 30 "CONNECT_ALREADY_CONN" 29 "CONNECT_DEVICE_NOT_FOUND_NO_RESOURCES" 28 "CONNECT_DEVICE_NOT_FOUND_PAGE_TIMEOUT" 27 "CONNECT_DEVICE_NOT_FOUND" 26 "CONNECT_FAILED_REMOTE_TERMINATED" 25 "CONNECT_FAILED_NO_RESOURCES" 24 "CONNECT_FAILED_CONNECTION_TIMEOUT" 23 "CONNECT_FAILED" 22 "CONNECT_SDP_FAILURE" 21 "CONNECT_PIN_MISSING" 20 "CONNECT_PAGE_TIMEOUT" 19 "CONNECT_REJ_BY_REMOTE_NO_RES" 18 "CONNECT_MAX_NR_OF_CONNS" 17 "CONNECT_CONTROLLER_BUSY" 16 "CONNECT_CONN_TIMEOUT" 15 "CONNECT_MAX_NR_OF_ACL" 14 "CONNECT_LMP_RESPONSE_TIMEOUT" 13 "CONNECT_HOST_TIMEOUT" 12 "CONNECT_UNKNOWN_FAILURE" 11 "DISCONNECT_UNKNOWN" 10 "DISCONNECT_OETC_POWERING_OFF" 9 "DISCONNECT_OETC_LOW_RESOURCE" 8 "DISCONNECT_REJ_BY_REMOTE_SEC" 7 "DISCONNECT_AUTH_FAIL" 6 "DISCONNECT_LMP_RESPONSE_TIMEOUT" 5 "DISCONNECT_OETC_USER" 4 "DISCONNECT_CONN_TIMEOUT" 3 "DISCONNECT_CONN_TERM_LOCAL_HOST" 2 "DISCONNECT_LINKLOSS" 1 "DISCONNECT_FROM_REMOTE" 0 "DISCONNECTED" ;
VAL_ 1056 UIS_firmwareReleaseScope 2 "PROD" 1 "DEV" 0 "UNKNOWN" ;
VAL_ 1056 UIS_embeddedGameState 2 "FROZEN" 1 "PLAYING" 0 "STOPPED" ;
VAL_ 1056 UIS_embeddedGameName 2 "POLYTOPIA" 1 "SOLITAIRE" 0 "NONE" ;
VAL_ 1056 UIS_dumTclipUploadState 7 "TclipStateDone" 6 "TclipStateUploading" 5 "TclipStateWaiting" 4 "TclipStateTransferring" 3 "TclipStatePolling" 2 "TclipStateChecking" 1 "TclipStateIdle" 0 "TclipStateSNA" ;
VAL_ 1056 UIS_dmRearPowerState 1 "ON" 0 "OFF" ;
VAL_ 1056 UIS_dmRearLinkCheckOk 1 "PASSED" 0 "FAILED" ;
VAL_ 1056 UIS_dmRearBacklightPowerLevel 2 "HIGH_POWER" 1 "LOW_POWER" 0 "OFF" ;
VAL_ 1056 UIS_dmRearBacklightDevExists 1 "PASSED" 0 "FAILED" ;
VAL_ 1056 UIS_dmIcuPowerState 1 "ON" 0 "OFF" ;
VAL_ 1056 UIS_dmIcuLinkCheckOk 1 "PASSED" 0 "FAILED" ;
VAL_ 1056 UIS_dmIcuBacklightPowerLevel 2 "HIGH_POWER" 1 "LOW_POWER" 0 "OFF" ;
VAL_ 1056 UIS_dmIcuBacklightDevExists 1 "PASSED" 0 "FAILED" ;
VAL_ 1056 UIS_dmIcuAsilResumeFlag 4 "ACI_ERROR_RESET" 3 "SOFTWARE_RESET" 2 "REBOOT_RESET" 1 "WATCHDOG_RESET" 0 "GLOBAL_RESET" ;
VAL_ 1056 UIS_dmIcuAsilFirmwareStatus 3 "NORMAL_RUN" 2 "CALIBRATION_DONE" 1 "CALIBRATION" 0 "INITIAL_STAGE" ;
VAL_ 1056 UIS_dmCenterSOsdExactCrcCheck 2 "PASS" 1 "EXPECT_MATCH_FAIL" 0 "EXPECT_MISMATCH_FAIL" ;
VAL_ 1056 UIS_dmCenterPowerState 1 "ON" 0 "OFF" ;
VAL_ 1056 UIS_dmCenterOsdDisplayedState 1 "SHOWING" 0 "HIDDEN" ;
VAL_ 1056 UIS_dmCenterOsdDayNightState 1 "DAY" 0 "NIGHT" ;
VAL_ 1056 UIS_dmCenterModeSettingStatus 1 "PASSED" 0 "FAILED" ;
VAL_ 1056 UIS_dmCenterMOsdExactCrcCheck 2 "PASS" 1 "EXPECT_MATCH_FAIL" 0 "EXPECT_MISMATCH_FAIL" ;
VAL_ 1056 UIS_dmCenterLinkCheckOk 1 "PASSED" 0 "FAILED" ;
VAL_ 1056 UIS_dmCenterBacklightPowerLevel 2 "HIGH_POWER" 1 "LOW_POWER" 0 "OFF" ;
VAL_ 1056 UIS_dmCenterBacklightDevExists 1 "PASSED" 0 "FAILED" ;
VAL_ 1056 UIS_dmCenterAsilResumeFlag 4 "ACI_ERROR_RESET" 3 "SOFTWARE_RESET" 2 "REBOOT_RESET" 1 "WATCHDOG_RESET" 0 "GLOBAL_RESET" ;
VAL_ 1056 UIS_dmCenterAsilFirmwareStatus 3 "NORMAL_RUN" 2 "CALIBRATION_DONE" 1 "CALIBRATION" 0 "INITIAL_STAGE" ;
VAL_ 1056 UIS_dashcamStorageState 8 "RECENT_BUFFER_DURATION_REDUCED" 7 "SLOW" 6 "READ_ONLY" 5 "FULL" 4 "GETTING_FULL" 3 "ERROR" 2 "READY" 1 "REMOVED" 0 "INVALID" ;
VAL_ 1056 UIS_dashcamState 7 "STREAMING" 6 "SAVING" 5 "PAUSED" 4 "RECORDING" 3 "STOPPED" 2 "ERROR" 1 "TERMINATED" 0 "INVALID" ;
VAL_ 1056 UIS_compositorFrameMonitorState 6 "DISCONNECTED" 5 "OK" 4 "STALLED" 3 "STALLING" 2 "CORRUPT_TIMECODE" 1 "UNKNOWN_FAILURE" 0 "UNKNOWN" ;
VAL_ 1056 UIS_clusterDisplayState 9 "ENTERTAINMENT" 8 "DOG" 7 "SENTRY" 6 "LOCK" 5 "CHARGING" 4 "DRIVING" 3 "ON" 2 "ACCESSORY" 1 "DIM" 0 "OFF" ;
VAL_ 1056 UIS_chargeOnSolarNoChargeReason 3 "ALTERNATIVE_VEHICLE_CHARGE_PRIORITY" 2 "GRID_EXPORT_PRIORITY" 1 "POWERWALL_CHRAGE_PRIORITY" 0 "INSUFFICIENT_SOLAR" ;
VAL_ 1056 UIS_centerDisplayState 9 "ENTERTAINMENT" 8 "DOG" 7 "SENTRY" 6 "LOCK" 5 "CHARGING" 4 "DRIVING" 3 "ON" 2 "ACCESSORY" 1 "DIM" 0 "OFF" ;
VAL_ 1056 UIS_centerDisplayEvent 21 "CPD_TRIGGERED" 20 "CAR_LOCKED" 19 "ENTERTAINMENT_OFF" 18 "ALL_STATES_EXCEPT_ENTERTAINMENT_TURNED_ON" 17 "IC_HAZARDS_OFF_DOOR_CLOSED_NO_OCCUPANTS" 16 "IC_HAZARDS_ON" 15 "ALL_DOORS_CLOSED_NO_OCCUPANTS_CHARGE_ACTIVE" 14 "TIMEOUT" 13 "DOOR_HANDLE_PULLED" 12 "ALL_STATES_EXCEPT_SENTRY" 11 "SENTRY_PANIC_ENDED" 10 "POWER_OFF_REQUEST" 9 "DRIVE_RAIL_OFF_NO_DRIVER_PRESENT" 8 "DRIVE_RAIL_OFF_DOOR_OPEN" 7 "DRIVE_RAIL_OFF_DRIVE_PRESENT" 6 "POWER_ON_REQUEST" 5 "DOOR_OPENED" 4 "ALL_STATES_EXCEPT_ENTERTAINMENT_DRIVE_RAIL_TURNED_ON" 3 "ALL_DOORS_CLOSED_NO_OCCUPANTS" 2 "PASSED_SPEED_THRESHOLD" 1 "SHIFTED_P_TO_N" 0 "OTHER" ;
VAL_ 1056 UIS_cellularLinkManagerState 16 "INVALID" 15 "RUNNING" 14 "DISCONNECTING" 13 "ROAMINGDISALLOWED" 12 "ENTERINGAIRPLANEMODE" 11 "CHECKING" 10 "RETRYING" 9 "CONFIGURING" 8 "CONNECTING" 7 "OFONOMODEMRELOADING" 6 "SEARCHING" 5 "CONFIGURINGAPN" 4 "QUERYDIAGNOSTIC" 3 "STARTING" 2 "UPDATING" 1 "RESETTING" 0 "RECOVERING" ;
VAL_ 1056 UIS_carAssistState 5 "GROK" 4 "DICTATION" 3 "COMMAND" 2 "ERROR" 1 "IDLE" 0 "DISABLED" ;
VAL_ 1056 UIS_carAssistErrorCode 17 "CLIENT_LOGGED_OUT_TOKEN_EXPIRED" 16 "CLIENT_PROVIDER_RATE_LIMTED" 15 "CLIENT_PROVIDER_AT_CAPACITY" 14 "CLIENT_ANON_USAGE_LIMITED" 13 "CLIENT_PREM_CONN" 12 "CLIENT_SPEECH" 11 "CLIENT_REMOTE" 10 "CLIENT_DBUS" 9 "CLIENT_DISCONNECTED" 8 "CLIENT_CONNECTIVITY" 7 "CLIENT_AUDIO" 6 "CLIENT_ERROR" 5 "COMMAND_NOT_IMPLEMENTED" 4 "COMMAND_NOT_AVAILABLE" 3 "COMMAND_NOT_UNDERSTOOD" 2 "REMOTE_ERROR" 1 "REMOTE_UNKNOWN" 0 "NONE" ;
VAL_ 1056 UIS_cameraRRepeaterStreamMissing 1 "MISSING" 0 "ACTIVE" ;
VAL_ 1056 UIS_cameraRRepeaterStream 2 "ACTIVE" 1 "REQUESTED" 0 "INACTIVE" ;
VAL_ 1056 UIS_cameraRRepeaterPopup 1 "OPEN" 0 "CLOSED" ;
VAL_ 1056 UIS_cameraRRepeaterPipeline 4 "PLAYING" 3 "PAUSED" 2 "READY" 1 "NULL" 0 "SLEEP" ;
VAL_ 1056 UIS_cameraLRepeaterStreamMissing 1 "MISSING" 0 "ACTIVE" ;
VAL_ 1056 UIS_cameraLRepeaterStream 2 "ACTIVE" 1 "REQUESTED" 0 "INACTIVE" ;
VAL_ 1056 UIS_cameraLRepeaterPopup 1 "OPEN" 0 "CLOSED" ;
VAL_ 1056 UIS_cameraLRepeaterPipeline 4 "PLAYING" 3 "PAUSED" 2 "READY" 1 "NULL" 0 "SLEEP" ;
VAL_ 1056 UIS_cameraFrontStreamMissing 1 "MISSING" 0 "ACTIVE" ;
VAL_ 1056 UIS_cameraFrontStream 2 "ACTIVE" 1 "REQUESTED" 0 "INACTIVE" ;
VAL_ 1056 UIS_cameraFrontPopup 1 "OPEN" 0 "CLOSED" ;
VAL_ 1056 UIS_cameraFrontPipeline 4 "PLAYING" 3 "PAUSED" 2 "READY" 1 "NULL" 0 "SLEEP" ;
VAL_ 1056 UIS_cameraBackupStreamQuality 4 "EXCELLENT" 3 "GOOD" 2 "FAIR" 1 "POOR" 0 "UNKNOWN" ;
VAL_ 1056 UIS_cameraBackupStreamMissing 1 "MISSING" 0 "ACTIVE" ;
VAL_ 1056 UIS_cameraBackupStream 2 "ACTIVE" 1 "REQUESTED" 0 "INACTIVE" ;
VAL_ 1056 UIS_cameraBackupPopup 1 "OPEN" 0 "CLOSED" ;
VAL_ 1056 UIS_cameraBackupPipeline 4 "PLAYING" 3 "PAUSED" 2 "READY" 1 "NULL" 0 "SLEEP" ;
VAL_ 1056 UIS_bluetoothStackState 4 "ON_BLUEZ" 3 "ON_SYNERGY" 2 "ON_LGIT" 1 "ON" 0 "OFF" ;
VAL_ 1056 UIS_bluetoothStackRearState 4 "ON_BLUEZ" 3 "ON_SYNERGY" 2 "ON_LGIT" 1 "ON" 0 "OFF" ;
VAL_ 1056 UIS_bluetoothPairResult 23 "HID_PAIRED" 22 "HID_MAX_NR_OF_CONNS" 21 "HID_PAGE_TIMEOUT" 20 "HID_OETC_USER" 19 "HID_REJ_BY_REMOTE_NO_RES" 18 "HID_LMP_RESPONSE_TIMEOUT" 17 "HID_AUTH_FAILURE" 16 "HID_KEY_MISSING" 15 "HID_NO_RESPONSE" 14 "HID_ALREADY_REQUESTED_BY_REMOTE" 13 "HID_UNKNOWN" 12 "HID_UNPAIRED" 11 "PAIRED" 10 "MAX_NR_OF_CONNS" 9 "PAGE_TIMEOUT" 8 "OETC_USER" 7 "REJ_BY_REMOTE_NO_RES" 6 "LMP_RESPONSE_TIMEOUT" 5 "AUTH_FAILURE" 4 "KEY_MISSING" 3 "NO_RESPONSE" 2 "ALREADY_REQUESTED_BY_REMOTE" 1 "UNKNOWN" 0 "UNPAIRED" ;
VAL_ 1056 UIS_bluetoothConnectionState 77 "HID_ERROR_UNKNOWN" 76 "HID_ERROR_ANTENNA_DISCONNECTED" 75 "HID_CONNECTED" 74 "HID_CONNECT_CANCELLED" 73 "HID_CONNECT_PROFILE_UNAVAILABLE" 72 "HID_CONNECT_INVALID_ARGUMENT" 71 "HID_CONNECT_ADAPTER_OFF" 70 "HID_CONNECT_NOT_SUPPORTED" 69 "HID_CONNECT_ALREADY_CONN" 68 "HID_CONNECT_DEVICE_NOT_FOUND_NO_RESOURCES" 67 "HID_CONNECT_DEVICE_NOT_FOUND_PAGE_TIMEOUT" 66 "HID_CONNECT_DEVICE_NOT_FOUND" 65 "HID_CONNECT_FAILED_REMOTE_TERMINATED" 64 "HID_CONNECT_FAILED_NO_RESOURCES" 63 "HID_CONNECT_FAILED_CONNECTION_TIMEOUT" 62 "HID_CONNECT_FAILED" 61 "HID_CONNECT_SDP_FAILURE" 60 "HID_CONNECT_PIN_MISSING" 59 "HID_CONNECT_PAGE_TIMEOUT" 58 "HID_CONNECT_REJ_BY_REMOTE_NO_RES" 57 "HID_CONNECT_MAX_NR_OF_CONNS" 56 "HID_CONNECT_CONTROLLER_BUSY" 55 "HID_CONNECT_CONN_TIMEOUT" 54 "HID_CONNECT_MAX_NR_OF_ACL" 53 "HID_CONNECT_LMP_RESPONSE_TIMEOUT" 52 "HID_CONNECT_HOST_TIMEOUT" 51 "HID_CONNECT_UNKNOWN_FAILURE" 50 "HID_DISCONNECT_UNKNOWN" 49 "HID_DISCONNECT_OETC_POWERING_OFF" 48 "HID_DISCONNECT_OETC_LOW_RESOURCE" 47 "HID_DISCONNECT_REJ_BY_REMOTE_SEC" 46 "HID_DISCONNECT_AUTH_FAIL" 45 "HID_DISCONNECT_LMP_RESPONSE_TIMEOUT" 44 "HID_DISCONNECT_OETC_USER" 43 "HID_DISCONNECT_CONN_TIMEOUT" 42 "HID_DISCONNECT_CONN_TERM_LOCAL_HOST" 41 "HID_DISCONNECT_LINKLOSS" 40 "HID_DISCONNECT_FROM_REMOTE" 39 "HID_DISCONNECTED" 38 "ERROR_UNKNOWN" 37 "ERROR_ANTENNA_DISCONNECTED" 36 "CONNECTED" 35 "CONNECT_CANCELLED" 34 "CONNECT_PROFILE_UNAVAILABLE" 33 "CONNECT_INVALID_ARGUMENT" 32 "CONNECT_ADAPTER_OFF" 31 "CONNECT_NOT_SUPPORTED" 30 "CONNECT_ALREADY_CONN" 29 "CONNECT_DEVICE_NOT_FOUND_NO_RESOURCES" 28 "CONNECT_DEVICE_NOT_FOUND_PAGE_TIMEOUT" 27 "CONNECT_DEVICE_NOT_FOUND" 26 "CONNECT_FAILED_REMOTE_TERMINATED" 25 "CONNECT_FAILED_NO_RESOURCES" 24 "CONNECT_FAILED_CONNECTION_TIMEOUT" 23 "CONNECT_FAILED" 22 "CONNECT_SDP_FAILURE" 21 "CONNECT_PIN_MISSING" 20 "CONNECT_PAGE_TIMEOUT" 19 "CONNECT_REJ_BY_REMOTE_NO_RES" 18 "CONNECT_MAX_NR_OF_CONNS" 17 "CONNECT_CONTROLLER_BUSY" 16 "CONNECT_CONN_TIMEOUT" 15 "CONNECT_MAX_NR_OF_ACL" 14 "CONNECT_LMP_RESPONSE_TIMEOUT" 13 "CONNECT_HOST_TIMEOUT" 12 "CONNECT_UNKNOWN_FAILURE" 11 "DISCONNECT_UNKNOWN" 10 "DISCONNECT_OETC_POWERING_OFF" 9 "DISCONNECT_OETC_LOW_RESOURCE" 8 "DISCONNECT_REJ_BY_REMOTE_SEC" 7 "DISCONNECT_AUTH_FAIL" 6 "DISCONNECT_LMP_RESPONSE_TIMEOUT" 5 "DISCONNECT_OETC_USER" 4 "DISCONNECT_CONN_TIMEOUT" 3 "DISCONNECT_CONN_TERM_LOCAL_HOST" 2 "DISCONNECT_LINKLOSS" 1 "DISCONNECT_FROM_REMOTE" 0 "DISCONNECTED" ;
VAL_ 1056 UIS_bluetoothAutoConnectionState 3 "MANUAL_CONNECT_REQUESTED" 2 "GAVE_UP" 1 "CONNECTED" 0 "IDLE" ;
VAL_ 1056 UIS_audioType 4 "BASE_WITH_PREMIUM200" 3 "PREMIUM" 2 "BASE" 1 "NO_A2B" 0 "INVALID" ;
VAL_ 1056 UIS_audioState 7 "SLEEPING" 6 "AUDIO_NOT_PUMPING" 5 "A2B_REDISCOVERY" 4 "HFP_PUMPING" 3 "AUDIO_PUMPING" 2 "UNINITIALIZING" 1 "INITIALIZING" 0 "TERMINATED" ;
VAL_ 1056 UIS_audioSource 5 "NONE" 4 "PHONE_RX" 3 "BLUETOOTH" 2 "MICROPHONE" 1 "TUNER" 0 "MEDIA" ;
VAL_ 1056 UIS_audioMediaPlaying 39 "SODA_MUSIC" 38 "CARAOKE" 37 "KUGOU" 36 "YOUTUBE_MUSIC" 35 "YUNTING" 34 "AMAZON_MUSIC" 33 "AUDIBLE" 32 "APPLE_PODCASTS" 31 "APPLE_MUSIC" 30 "MINI_PROGRAMS" 29 "SEARCH" 28 "HOME_APPS" 27 "RECENTS_FAVORITES" 26 "TOYBOX" 25 "TUTORIAL" 24 "THEATER" 23 "BROWSER" 22 "GAME" 21 "NET_EASE_MUSIC" 20 "ONLINE_RADIO" 19 "XIMALAYA" 18 "QQ_MUSIC2" 17 "QQ_MUSIC1" 16 "TIDAL" 15 "SIRIUS_XM" 14 "STINGRAY" 13 "TUNE_IN" 12 "EU_RADIO" 11 "US_RADIO" 10 "SPOTIFY" 9 "SLACKER" 8 "BLUETOOTH" 7 "USB" 6 "DAB" 5 "XM" 4 "FM" 3 "AM" 2 "UNKNOWN" 1 "DEPRECATED" 0 "NONE" ;
VAL_ 1056 UIS_audioMediaBrowsing 39 "SODA_MUSIC" 38 "CARAOKE" 37 "KUGOU" 36 "YOUTUBE_MUSIC" 35 "YUNTING" 34 "AMAZON_MUSIC" 33 "AUDIBLE" 32 "APPLE_PODCASTS" 31 "APPLE_MUSIC" 30 "MINI_PROGRAMS" 29 "SEARCH" 28 "HOME_APPS" 27 "RECENTS_FAVORITES" 26 "TOYBOX" 25 "TUTORIAL" 24 "THEATER" 23 "BROWSER" 22 "GAME" 21 "NET_EASE_MUSIC" 20 "ONLINE_RADIO" 19 "XIMALAYA" 18 "QQ_MUSIC2" 17 "QQ_MUSIC1" 16 "TIDAL" 15 "SIRIUS_XM" 14 "STINGRAY" 13 "TUNE_IN" 12 "EU_RADIO" 11 "US_RADIO" 10 "SPOTIFY" 9 "SLACKER" 8 "BLUETOOTH" 7 "USB" 6 "DAB" 5 "XM" 4 "FM" 3 "AM" 2 "UNKNOWN" 1 "DEPRECATED" 0 "NONE" ;
VAL_ 1056 UIS_activeAppView 67 "SODA_MUSIC" 66 "HICAR" 65 "CARAOKE_WEB" 64 "KUGOU" 63 "YOUTUBE_MUSIC" 62 "YUNTING" 61 "ONLINE_RADIO" 60 "AMAZON_MUSIC" 59 "AUDIBLE" 58 "APPLE_PODCASTS" 57 "ONBOARDING_MANUAL" 56 "APPLE_MUSIC" 55 "ZOOM" 54 "MINI_PROGRAMS" 53 "CADMIUM" 52 "MESSAGES" 51 "NAV_MEDIA" 50 "BACKGAMMON" 49 "SKETCH_PAD" 48 "ARCADE" 47 "XIMALAYA" 46 "BLUETOOTH" 45 "CHESS" 44 "NETEASE" 43 "OWNERS_MANUAL" 42 "QQMUSIC" 41 "RELEASE_NOTES" 40 "SONIC" 39 "USB" 38 "THEATER" 37 "TIDAL" 36 "TUNEIN" 35 "CARAOKE" 34 "STREAMING" 33 "RADIO" 32 "SPOTIFY" 31 "CAMERA" 30 "CHARGE" 29 "MEDIA" 28 "ENTERTAINMENT" 27 "WEB" 26 "CALENDAR" 25 "TOYBOX" 24 "PHONE" 23 "ENERGY" 22 "TUTORIAL" 21 "CERULEAN" 20 "TOPAZ" 19 "DASHCAM" 18 "CARBONADO" 17 "THEATERVIEW" 16 "MAMBU" 15 "COBALT" 14 "TESLATARI" 13 "SERVICE_APPS" 12 "LIME" 11 "TEARDROP" 10 "NAV" 9 "PURPLE" 8 "CALICO" 7 "CARWASH" 6 "2048" 5 "CONTROLS" 4 "COLORIZER" 3 "XM" 2 "DEVELOPMENT" 1 "NONE" 0 "UNKNOWN" ;
VAL_ 979 UI_airbagCutoffSwState 2 "SNA" 1 "PASSENGER_AIRBAG_OFF" 0 "PASSENGER_AIRBAG_ON" ;
VAL_ 979 UI_warningIndicatorStatus 3 "SNA" 1 "WARNING_LAMP_ON" 0 "WARNING_LAMP_OFF" ;
VAL_ 1523 UI_alertID 241 "a241_AxCPError" 240 "a240_ethError" 239 "a239_stateOfVehiclesFunctionsFeedback" 238 "a238_ModemConfigMismatch" 237 "a237_ClipUploadActive" 236 "a236_ModemOnResetState" 235 "a235_AMDI2C1Timeout" 234 "a234_AMDI2C0Timeout" 233 "a233_ModemRFFailure" 232 "a232_processExitError" 231 "a231_SleepCancelled" 230 "a230_ModemSimCardMismatch" 229 "a229_SerDesError" 228 "a228_pipewireXrunBurst" 226 "a226_largePhoneContactSync" 225 "a225_clusterDisplayDisconnected" 224 "a224_centerDisplayDisconnected" 223 "a223_databaseError" 222 "a222_QtCarRestart" 221 "a221_NavigationServiceError" 220 "a220_MediaBrowseError" 219 "a219_CompositorWatchdog" 218 "a218_AudiodNoAudioDevices" 217 "a217_CgroupMemoryPressure" 216 "a216_AudioA2bCircuitProblem" 215 "a215_compositorStallDetected" 214 "a214_pmHelperFailure" 213 "a213_ISADisabled" 212 "a212_AEBSFaulted" 211 "a211_AEBSDisabled" 210 "a210_CellularCSRegFail" 209 "a209_dataCallDisconnected" 208 "a208_mqttDisconnectReason" 207 "a207_mqttClientDisconnected" 206 "a206_ModemMIAAfterWake" 205 "a205_ModemSleepSignalMismatch" 204 "a204_ModemSleepFailure" 202 "a202_sysMemoryIncorrect" 201 "a201_rearDisplayDisconnected" 200 "a200_UIFirmwareVersionMismatch" 199 "a199_HighAPedalDetectedAtCollision" 198 "a198_IncompatibleBTUSBHubHardware" 197 "a197_AMDI2C1BusInoperable" 196 "a196_AMDI2C3BusInoperable" 195 "a195_gtwMfdUdpApiFired" 194 "a194_AudioweaverRestarted" 193 "a193_TcuRNandFwVersionMismatch" 192 "a192_AudioWatchdogReboot" 191 "a191_TunerUpdateFailed" 190 "a190_TunerMIA" 189 "a189_TunerWatchdogReset" 188 "a188_TunerFirmwareMismatchedAPI" 187 "a187_TunerFirmwareMismatchedVersion" 186 "a186_ELKSUnavailable" 185 "a185_ELKSDisabled" 184 "a184_ISAFaulted" 183 "a183_DDAWFaulted" 182 "a182_VideoPipelineOverrun" 181 "a181_ModemFirmwareVersionMismatch" 180 "a180_AudiodInputRestarted" 179 "a179_TestDriveVideoDownloadFailure" 178 "a178_irqDisabled" 177 "a177_MediaPlayerFailure" 176 "a176_CellularAntennaAlert" 174 "a174_HistorySaveLoop" 173 "a173_pmSuspendFailure" 172 "a172_GraphicsLoadShedUIFailure" 171 "a171_GraphicsLoadShedRequested" 170 "a170_AMDdGPULoadShedFailure" 169 "a169_SteamLoadShedFailure" 168 "a168_dgpuPowerOnSelfTestFailure" 167 "a167_CgroupOverMemKill" 166 "a166_fsError" 165 "a165_fsCorrupted" 164 "a164_AudiodConnTimeout" 163 "a163_QtCarVehicleExitError" 162 "a162_voiceRecClipsUploaded" 161 "a161_ECallTemporarilyUnavailable" 160 "a160_SystemWatchdogFailure" 159 "a159_AudioHeartbeatFailure" 158 "a158_UsbDeviceMountError" 157 "a157_MCUActiveCoolingRequested" 156 "a156_UsbFrontHubInstallMismatch" 155 "a155_UsbFrontHubUnavailable" 154 "a154_AudiodBufferError" 153 "a153_serviceRestarted" 152 "a152_infoThrottling" 151 "a151_carComputerThermalProblem" 150 "a150_infoCPURunningHot" 149 "a149_DisplayCheckFailure" 148 "a148_SleepFailure" 147 "a147_ASILGlobalError" 146 "a146_nvmeNeedsReplacement" 145 "a145_nvmeUnsafeShutdown" 144 "a144_nvmeWarning" 143 "a143_FPSCrawling" 142 "a142_CorrectableMemoryError" 141 "a141_falconDoorOpen" 140 "a140_NeverSleepActive" 139 "a139_postponedConfigChange" 138 "a138_applyingConfigChange" 137 "a137_ServiceShellActiveConnection" 136 "a136_warnSettingsConfExists" 135 "a135_warnRunOverlayExists" 134 "a134_DashcamUsbDriveNoMedium" 133 "a133_AdspWatchdogRecoveryFailed" 132 "a132_AdspWatchdogRecoveryTriggered" 131 "a131_DisplayPortFailure" 130 "a130_QtCarClusterExitError" 129 "a129_dgpuOperationFailure" 128 "a128_dgpuNotDetected" 126 "a126_UsbErrorDriveCorrupt" 125 "a125_AMDI2C1TxRxAborted" 124 "a124_AMDI2C0TxRxAborted" 123 "a123_AMDI2C1LostArbitration" 122 "a122_AMDI2C0LostArbitration" 121 "a121_nvmeSmartLogCritical" 120 "a120_nvmePCIeLinkErrorDetected" 119 "a119_nvmeBlockDeviceMissing" 118 "a118_NVMeReset" 117 "a117_VehicleSelfTestRunning" 116 "a116_UncorrectableMemoryError" 115 "a115_IrisEDLMode" 114 "a114_drivingVisualizationDegraded" 113 "a113_DashcamHasOnboardSentryClips" 112 "a112_badUSBDevice" 111 "a111_DashcamUsbDriveNotSuperSpeed" 110 "a110_DashcamUsbDriveCorrupt" 109 "a109_DashcamUsbDriveTooSmall" 108 "a108_DashcamUsbDriveGettingFull" 107 "a107_DashcamUsbDriveTooBigForVfatFsck" 106 "a106_rebootBackstopTriggered" 105 "a105_firmwareReinstallRequested" 104 "a104_DashcamUsbDriveMissing" 103 "a103_UsbHubNotEnumerating" 102 "a102_A2bDiscoveryFailed" 101 "a101_wifiStackProblem" 100 "a100_eMMCFTLError" 99 "a099_eMMCStatusError" 98 "a098_DiskCheckFailure" 97 "a097_AudiodRestarted" 96 "a096_VideodPipelineIssueDetected" 95 "a095_CidStorageRunningLow" 94 "a094_ModemPowerOnFailure" 93 "a093_updateEnded" 92 "a092_updateStarted" 91 "a091_VehicleLinkStall" 90 "a090_RadioPingFailError" 89 "a089_RadioSoftResetError" 88 "a088_CellRemovableSimMissing" 87 "a087_BmpReset" 86 "a086_TouchEnumerationError" 85 "a085_DeserializerError" 84 "a084_SerializerError" 83 "a083_ECallProxyWatchdogTriggered" 82 "a082_NumModemRebootStuckInECall" 81 "a081_CellModemSearchExpired" 80 "a080_DashcamUsbDriveSlow" 79 "a079_DashcamUsbDriveFull" 78 "a078_DashcamUsbDriveUnmountable" 77 "a077_AudioA2bMicChannelSwap" 76 "a076_NumFalseManualECalls" 75 "a075_BackupCameraInitError" 74 "a074_EMMCHangDetected" 73 "a073_ECallDigitalMicFailed" 72 "a072_ECallAnalogMicFailed" 71 "a071_VideoPipelineError" 70 "a070_VideoPipelineWarning" 69 "a069_VideoUDPTimeout" 68 "a068_VideoUnexpectedExit" 67 "a067_WarnOnI915" 66 "a066_GpuHangDetected" 65 "a065_WiFiRecoveryReset" 64 "a064_ModemFirmwareTestFailed" 63 "a063_CellularTestFailed" 62 "a062_ENSTestFailed" 61 "a061_SIMTestFailed" 60 "a060_ECallMicDisconnected" 59 "a059_ECallSpeakerDisconnected" 58 "a058_GPSAntennaDisconnected" 57 "a057_CellAntennaDisconnected" 56 "a056_ManualECallButtonDisconnected" 55 "a055_ManualECallDisabled" 54 "a054_AudioBoostPowerBad" 53 "a053_QtCarExitError" 52 "a052_KernelPanicReported" 51 "a051_BackupCameraFrameTimeout" 50 "a050_BackupCameraIPUTimeout" 49 "a049_BrakeShiftRequired" 48 "a048_AudioPremiumAmpCheckFailed" 47 "a047_CellRoamingDisallowed" 46 "a046_BackupCameraStreamError" 45 "a045_ECallSystemCheckFailed" 44 "a044_AudioDmesgDspException" 43 "a043_InvalidMapDataOverride" 42 "a042_AudioDmesgRtThrottling" 41 "a041_AudioDmesgXrun" 40 "a040_HomelinkTransmit" 39 "a039_AudioA2bNeedRediscovery" 38 "a038_AudioWatchdogA2bI2cLockupError" 37 "a037_AudioWatchdogXrunStormError" 36 "a036_AudioWatchdog" 35 "a035_FrunkOpenChime" 34 "a034_WakeupProblem" 33 "a033_ApTrialExpired" 32 "a032_CellModemRecoveryResets" 31 "a031_BrakeFluidLow" 30 "a030_ModemVMCrash" 29 "a029_ModemMIA" 28 "a028_FrontTrunkPopupClosed" 27 "a027_AutoSteerMIA" 26 "a026_ModemResetLoopDetected" 24 "a024_WifiInternetCheckFailed" 23 "a023_CellInternetCheckFailed" 22 "a022_ApeFusesEtc" 21 "a021_RearSeatbeltUnbuckled" 20 "a020_SteeringReduced" 19 "a019_ParkBrakeFault" 18 "a018_SlipStartOn" 17 "a017_TPMSSystemFault" 16 "a016_TPMSTemperatureWarning" 15 "a015_TPMSOverPressureWarning" 14 "a014_TPMSSoftWarning" 13 "a013_TPMSHardWarning" 12 "a012_NotOnPrivateProperty" 11 "a011_IncorrectMap" 10 "a010_MapsMissing" 9 "a009_SquashfsError" 8 "a008_TouchScreenError" 7 "a007_SoftPackConfigMismatch" 6 "a006_RemoteServiceAlert" 5 "a005_HeadlightsOnDoorOpen" 4 "a004_FrunkOpen" 3 "a003_TrunkOpen" 2 "a002_DoorOpen" 1 "a001_DriverDoorOpen" 0 "ALERT_DO_NOT_USE_ZERO" ;
VAL_ 1523 UI_alertState 1 "SET" 0 "CLEARED" ;
VAL_ 1523 UI_a036_audioWatchdogReason 5 "EXCEPTION_DETECTED" 4 "TDA7802_CANNOT_CONFIGURE_AMP" 3 "TDA7802_CANNOT_OPEN_CODEC_NEG_110" 2 "IPC_DELETE_PIPELINE_FAILED_NEG_110" 1 "IPC_SET_DX_FAILED_NEG_110" 0 "DISABLING_IRQ_NUM_25" ;
VAL_ 1523 UI_a087_BmpResetType 5 "WATCHDOG" 4 "POWER_ON" 3 "WARM" 2 "COLD" 1 "GLOBAL" 0 "UNKNOWN" ;
VAL_ 1523 UI_a131_DisplayPortFailureType 1 "DPCD_READ_FAILURE" 0 "UNKNOWN_LANE_TRAIN_FAILURE" ;
VAL_ 1523 UI_a147_whichASIL 1 "A" 0 "B" ;
VAL_ 1523 UI_a147_errorCode 24 "TOUCH_PLL_WATCHDOG" 23 "DISPLAY_PLL_WATCHDOG" 22 "PANEL_BROKEN" 21 "FLASH_CRC" 20 "LVDS_FAIL_SAFE" 19 "LVDS_DLL_LOCK" 18 "NO_HS_DE" 17 "NO_VS" 16 "NO_CLOCK" 15 "SOURCE" 14 "GATE" 13 "OVER_TEMP" 12 "VGL_OVD" 11 "VGH_OVD" 10 "AVEE_OVD" 9 "AVVD_OVD" 8 "VCOM_OVD" 7 "VDDI_OVD" 6 "VGL_LVD" 5 "VGH_LVD" 4 "AVEE_LVD" 3 "AVDD_LVD" 2 "VCOM_LVD" 1 "VDDI_LVD" 0 "UNKNOWN" ;
VAL_ 1523 UI_a148_sleepType 3 "Unknown" 2 "S2Idle" 1 "S3" 0 "Shallow" ;
VAL_ 1523 UI_a148_lastFailedPmSuspendDev 18 "Timesync" 17 "LED" 16 "Button" 15 "NVME" 14 "Hermes" 13 "Cameras" 12 "Modem" 11 "Bluetooth" 10 "Wifi" 9 "USB" 8 "Audio" 7 "BluetoothRear" 6 "DGPU" 5 "Post" 4 "Memory" 3 "UsbMsd" 2 "Steam" 1 "Unknown" 0 "None" ;
VAL_ 1523 UI_a149_displayType 9 "MY_DP_P103" 8 "CT_DP_185" 7 "M3_DP_P882" 6 "SX_HDMI_R94" 5 "M3_HDMI_E2X" 4 "M3_HDMI_P88" 3 "SX_HDMI_8" 2 "SX_HDMI_11" 1 "SX_DP_17" 0 "Unknown" ;
VAL_ 1523 UI_a149_errorCode 17 "HDMIFrequencyChanged" 16 "ASILStatusFault" 15 "OsdCrcFailedToEnable" 14 "OsdCrcI2CReadWriteFailure" 13 "OsdCrcSecondaryTconMismatch" 12 "OsdCrcMainTconMismatch" 11 "PowerControl" 10 "TouchStatus" 9 "GammaControl" 8 "GatewayWedged" 7 "ResetFailure" 6 "SerDesLink" 5 "LaneTraining" 4 "BacklightEnumeration" 3 "BacklightMismatch" 2 "BacklightPower" 1 "BacklightControl" 0 "Unknown" ;
VAL_ 1523 UI_a153_processName 13 "QTCAR" 12 "QTCAR_ACCOUNTMANAGER" 11 "QTCAR_AUDIOD" 10 "QTCAR_BLUETOOTH" 9 "QTCAR_CARSERVER" 8 "QTCAR_CLUSTER" 7 "QTCAR_CONNMAN" 6 "QTCAR_EVLOGSERVICE" 5 "QTCAR_GPSMANAGER" 4 "QTCAR_MEDIASERVER" 3 "QTCAR_SPEECH_RECOGNIZER" 2 "QTCAR_SPOTIFYSERVER" 1 "QTCAR_VEHICLE" 0 "UNKNOWN" ;
VAL_ 1523 UI_a153_restartReason 3 "OVER_MEM" 2 "DEAD" 1 "LOST_SHARED_MEM" 0 "UNKNOWN" ;
VAL_ 1523 UI_a158_UsbDeviceMountErrorCode 30 "READ_ONLY_FILE_SYSTEM" 22 "INVALID_ARGUMENT" 19 "NO_SUCH_DEVICE" 16 "DEVICE_OR_RESOURCE_BUSY" 13 "PERMISSION_DENIED" 12 "OUT_OF_MEMORY" 6 "NO_SUCH_DEVICE_OR_ADDRESS" 5 "IO_ERROR" 2 "NO_SUCH_FILE_OR_DIRECTORY" ;
VAL_ 1523 UI_a165_fsCorruptedDevice 8 "FS_TSLA_VAR" 7 "FS_BMAP" 6 "FS_AMAP" 5 "FS_HOME" 4 "FS_APPS_USR" 3 "FS_APPS_VAR" 2 "FS_VAR" 1 "FS_LOG" 0 "Unknown" ;
VAL_ 1523 UI_a166_fsErrorDevice 8 "FS_TSLA_VAR" 7 "FS_BMAP" 6 "FS_AMAP" 5 "FS_HOME" 4 "FS_APPS_USR" 3 "FS_APPS_VAR" 2 "FS_VAR" 1 "FS_LOG" 0 "Unknown" ;
VAL_ 1523 UI_a167_processId 24 "tunaman" 23 "hermes_log" 22 "thermald" 21 "apviz_assetgen_mem" 20 "apviz_controls_mem" 19 "apviz_mem" 18 "dashcam_viewer" 17 "qtcar_radioserver" 16 "mediaserver" 15 "hermes_fleet_streaming" 14 "hermes_dynamic_triggers" 13 "chromium_odin" 12 "chromium_odin_gpu" 11 "chromium_app" 10 "chromium_app_gpu" 9 "chromium_fullscreen" 8 "chromium_fullscreen_gpu" 7 "chromium" 6 "chromium_gpu" 5 "valhalla_server" 4 "QtCarSpeechReco" 3 "QtCarGpsManager" 2 "QtCarTMServer" 1 "QtCar" 0 "Unknown" ;
VAL_ 1523 UI_a173_errorCode 2 "MODEM" 1 "RESERVED" 0 "NONE" ;
VAL_ 1523 UI_a173_lastFailedPmSuspendDev 18 "Timesync" 17 "LED" 16 "Button" 15 "NVME" 14 "Hermes" 13 "Cameras" 12 "Modem" 11 "Bluetooth" 10 "Wifi" 9 "USB" 8 "Audio" 7 "BluetoothRear" 6 "DGPU" 5 "Post" 4 "Memory" 3 "UsbMsd" 2 "Steam" 1 "Unknown" 0 "None" ;
VAL_ 1523 UI_a176_PrimaryAntenna 5 "SHORTED" 4 "OPEN" 3 "NORMAL" 2 "UNKNOWN" 1 "NOT_POWERED" 0 "INITIALIZING" ;
VAL_ 1523 UI_a176_SecondaryAntenna 5 "SHORTED" 4 "OPEN" 3 "NORMAL" 2 "UNKNOWN" 1 "NOT_POWERED" 0 "INITIALIZING" ;
VAL_ 1523 UI_a176_TertiaryAntenna 5 "SHORTED" 4 "OPEN" 3 "NORMAL" 2 "UNKNOWN" 1 "NOT_POWERED" 0 "INITIALIZING" ;
VAL_ 1523 UI_a177_errorCode 18 "LICENSE_ERROR" 17 "WIDEVINE_CDM_EXPIRED" 16 "ACTIVE_PHONE_CALL" 15 "PLAYBACK_ERROR" 14 "WIFI_REQUIRED" 13 "UNSPECIFIED_ERROR" 12 "PLAYING_ON_ANOTHER_DEVICE" 11 "FAILED_TO_LOAD_TRACKS" 10 "INVALID_STREAM" 9 "INVALID_URL" 8 "EXPLICIT_CONTENT" 7 "STREAMING_DISABLED" 6 "NO_RESPONSE_FROM_MEDIA_SERVER" 5 "BITRATE_TOO_HIGH" 4 "NO_INTERNET" 3 "NETWORK_ERROR" 2 "NO_STATION" 1 "NO_PLAYER" 0 "NO_ERROR" ;
VAL_ 1523 UI_a192_AudioRebootState 9 "REBOOTED_CRITICAL_KERNEL_ERROR" 8 "REBOOTED_KERNEL_ERROR" 7 "BLOCKED_REASON_CAR_NOT_PARKED" 6 "BLOCKED_REASON_REBOOT_TIME_EXPIRED" 5 "BLOCKED_REASON_REBOOT_COMMAND_FAILED" 4 "BLOCKED_REASON_SOFTWARE_UPDATE_IN_PROGRESS" 3 "BLOCKED_REASON_GATEWAY_UPDATE_IN_PROGRESS" 2 "BLOCKED_REASON_TOWING_MODE_REQUESTED" 1 "BLOCKED_REASON_AUDIO_POWER_ISSUE_DETECTED" 0 "BLOCKED_REASON_UNEXPECTED_AUDIO_STATE" ;
VAL_ 1523 UI_a214_lastFailedPmSuspendDev 18 "Timesync" 17 "LED" 16 "Button" 15 "NVME" 14 "Hermes" 13 "Cameras" 12 "Modem" 11 "Bluetooth" 10 "Wifi" 9 "USB" 8 "Audio" 7 "BluetoothRear" 6 "DGPU" 5 "Post" 4 "Memory" 3 "UsbMsd" 2 "Steam" 1 "Unknown" 0 "None" ;
VAL_ 1523 UI_a216_circuitProblem 42 "NON_LOCALIZED_SHORT_TO_VBAT" 41 "NON_LOCALIZED_SHORT_TO_GND" 15 "INDETERMINATE_FAULT" 13 "CABLE_REVERSE_CONNECTED" 12 "CABLE_DISCONNECTED_OR_OPEN_CIRCUIT" 11 "CABLE_SHORTED_TOGETHER" 10 "CABLE_SHORTED_TO_VBAT" 9 "CABLE_SHORTED_TO_GND" ;
VAL_ 1523 UI_a216_circuitNode 3 "SLAVE_AMP" 2 "SLAVE_MIC" 1 "SLAVE_NODE" 0 "MASTER_NODE" ;
VAL_ 1523 UI_a217_cgroupName 24 "tunaman" 23 "hermes_log" 22 "thermald" 21 "apviz_assetgen_mem" 20 "apviz_controls_mem" 19 "apviz_mem" 18 "dashcam_viewer" 17 "qtcar_radioserver" 16 "mediaserver" 15 "hermes_fleet_streaming" 14 "hermes_dynamic_triggers" 13 "chromium_odin" 12 "chromium_odin_gpu" 11 "chromium_app" 10 "chromium_app_gpu" 9 "chromium_fullscreen" 8 "chromium_fullscreen_gpu" 7 "chromium" 6 "chromium_gpu" 5 "valhalla_server" 4 "QtCarSpeechReco" 3 "QtCarGpsManager" 2 "QtCarTMServer" 1 "QtCar" 0 "Unknown" ;
VAL_ 1523 UI_a220_errorCode 11 "UPDATE_REQUIRED" 10 "CONTENT_BLOCKED" 9 "SERVICE_UNAVAILABLE" 8 "INTERNAL_SERVER_ERROR" 7 "TOO_MANY_REQUESTS" 6 "TIMEOUT" 5 "NOT_FOUND" 4 "FORBIDDEN" 3 "UNAUTHORIZED" 2 "BAD_REQUEST" 1 "INTERNAL_ERROR" 0 "NETWORK_ERROR" ;
VAL_ 1523 UI_a222_errorCode 11 "TIMED_OUT" 10 "OVER_GEM_OBJECT_MEMORY" 9 "OVER_MEMORY" 8 "LOST_SHARED_MEMORY" 7 "MANUAL" 6 "START_FTRACE_SNIFFING" 5 "CHANGED_TEXT_ACCESSIBILITY_OPTION" 4 "EXIT_TRANSPORT_MODE" 3 "ENTER_TRANSPORT_MODE" 2 "CUSTOMER_MODE_REQUESTED" 1 "LANGUAGE_CHANGED" 0 "OTHER" ;
VAL_ 1523 UI_a223_database 39 "APP_PUSH_NOTIFICATION" 38 "RADIO_SERVER_SETTINGS" 37 "TM_SERVER_SETTINGS" 36 "SPOTIFY_SERVER_SETTINGS" 35 "RELEASE_NOTES_SETTINGS" 34 "QTCAR_VEHICLE_POWER_SETTINGS" 33 "QTCAR_ENERGY_MONITOR_SETTINGS" 32 "ENERGY_CONSUMPTION" 31 "QTCAR_DV_SERVER_SETTINGS" 30 "QTCAR_CONNMAN_SETTINGS" 29 "QTCAR_AUDIOD_SETTINGS" 28 "OWNERS_MANUAL_SETTINGS" 27 "OWNERS_MANUAL_ADAPTER_SETTINGS" 26 "QTCAR_MONITOR_SETTINGS" 25 "QTCAR_MEDIA_SERVER2_SETTINGS" 24 "QTCAR_GPS_MANAGER_SETTINGS" 23 "QTCAR_FIRMWARE_INSTALL_SETTINGS" 22 "QTCAR_ECALL_CLIENT_SETTINGS" 21 "DASHCAM_VIEWER_SETTINGS" 20 "QTCAR_CONN_METRICS_SETTINGS" 19 "ACCOUNT_MANAGER_SETTINGS" 18 "BT_DEVICES" 17 "CALENDAR" 16 "NUANCE_SERVER_SETTINGS" 15 "PHONEBOOK_V2" 14 "QTCAR_BLUETOOTH_SETTINGS" 13 "QTCAR_EVLOG_SERVICE_SETTINGS" 12 "QTCAR_SERVER_SETTINGS" 11 "QTCAR_SETTINGS" 10 "QTCAR_SPEECH_RECOGNIZER_SETTINGS" 9 "QTCAR_VEHICLE_SETTINGS" 8 "VEHICLE_DATAKEYS" 7 "MSG_TRACK" 6 "PLACES_RECOMMENDATION" 5 "VEHICLE_LOG2" 4 "PROFILE_FRECENCY" 3 "PROFILE_PLACES_RECENT" 2 "PLACES_RECENT" 1 "FRECENCY" 0 "UNKNOWN" ;
VAL_ 1523 UI_a229_errorCode 13 "HDMI_FREQ" 12 "LINK_DETECT" 11 "SIGNAL_DETECT" 10 "TMDS_CLOCK" 9 "RX_FIVE_V_DETECT" 8 "INIT_DONE" 7 "CFG_CKSUM" 6 "FPD_THREE_LINK_RDY" 5 "FPD_THREE_TX_STS" 4 "TMDS_VALID" 3 "HDMI_PLL_LOCK" 2 "FREQ_STABLE" 1 "CLOCK_RECV" 0 "DL_MODE" ;
VAL_ 1523 UI_a231_sleepType 3 "Unknown" 2 "S2Idle" 1 "S3" 0 "Shallow" ;
VAL_ 1523 UI_a232_processExited 24 "SPOTIFY_SERVER" 23 "QTCAR" 22 "QTCAR_CLUSTER" 21 "QTCAR_VEHICLE" 20 "QTCAR_BLUETOOTH" 19 "QTCAR_CONNMAN" 18 "QTCAR_DVSERVER" 17 "QTCAR_EVLOGSERVICE" 16 "QTCAR_FIRMWAREINSTALL" 15 "QTCAR_MEDIASERVERV2" 14 "QTCAR_RADIOSERVER" 13 "QTCAR_SIMSERVICE" 12 "QTCAR_SPEECHRECOGNIZER" 11 "QTCAR_STARTUP" 10 "QTCAR_TMSERVER" 9 "QTCAR_AUDIOD" 8 "QTCAR_CHECKINTERNET" 7 "QTCAR_ECALLCLIENT" 6 "QTCAR_ENERGYMONITOR" 5 "QTCAR_GPSMANAGER" 4 "QTCAR_MONITOR" 3 "QTCAR_SERVER" 2 "QTCAR_VEHICLEPOWER" 1 "UNKNOWN" ;
VAL_ 1523 UI_a232_processSignal 11 "SEGMENTATION_FAULT" 8 "FLOATING_POINT_EXCEPTION" 7 "BUS_ERROR" 6 "ABORT" 4 "ILLEGAL_INSTRUCTION" 1 "UNKNOWN" ;
VAL_ 1523 UI_a240_ethErrorType 6 "TX_FLOOD" 5 "RX_FLOOD" 4 "TX_OVERRUN" 3 "RX_OVERRUN" 2 "TX_ERROR" 1 "RX_ERROR" 0 "UNKNOWN" ;
VAL_ 1657 UI_rgbEnableState 2 "AUTO" 1 "ON" 0 "OFF" ;
VAL_ 1657 UI_rgbEffectType 20 "RAMP_5000MS" 19 "RAMP_4750MS" 18 "RAMP_4500MS" 17 "RAMP_4250MS" 16 "RAMP_4000MS" 15 "RAMP_3750MS" 14 "RAMP_3500MS" 13 "RAMP_3250MS" 12 "RAMP_3000MS" 11 "RAMP_2750MS" 10 "RAMP_2500MS" 9 "RAMP_2250MS" 8 "RAMP_2000MS" 7 "RAMP_1750MS" 6 "RAMP_1500MS" 5 "RAMP_1250MS" 4 "RAMP_1000MS" 3 "RAMP_750MS" 2 "RAMP_500MS" 1 "RAMP_250MS" 0 "RAMP_INSTANT" ;
VAL_ 1657 UI_rgbBrightnessLevel 127 "SNA" ;
